VERSION "DNNBNNNYNNNNNNNNNNNNNNNNNNYYYNNNNNNNNNNNNN/4/%%%/4/'%**4NNN///"

NS_ :

BS_:

BU_: KCU_GS KCU_DM KW LCU_R LCU_F OFFCAR_SKM SKM SWCU VCU DBCU BCU_R BCU_F SCU_DRV DCU_PSG DCU_DRV SCU_PSG ACU OFFCAR_VCU OFFCAR_ACU IVI H_PUMP CCCU OFFCAR_SSCU SSCU M2M RCL_L RCL_R FCL_R FCL_L
VAL_TABLE_ Parking_lights 1 "ON " 0 "OFF" ;
VAL_TABLE_ lamp_fault 3 "Init" 1 "Fault" 0 "NoFault" ;
VAL_TABLE_ aVtSig_EN_ENABLE 1 "ENABLE" 0 "DISABLE" ;
VAL_TABLE_ aVtSig_ST_ON_OFF 1 "ON" 0 "OFF" ;
VAL_TABLE_ aVtSig_REQ_IDLE_ON_OFF 2 "ON" 1 "OFF" 0 "IDLE" ;
VAL_TABLE_ aVtSig_REQ_ON_OFF 1 "ON" 0 "OFF" ;
VAL_TABLE_ Statusvalues 1 "On" 0 "IDLE" ;
VAL_TABLE_ Enable_Disable 1 "Enable" 0 "Disable" ;
VAL_TABLE_ OpenClose 1 "OPEN" 0 "CLOSE" ;
VAL_TABLE_ DayNight 1 "Day" 0 "Night" ;
VAL_TABLE_ Applied_Not_Applied 2 "Applied" 1 "Not applied" 0 "IDLE" ;
VAL_TABLE_ Activate_Deactivate 2 "Activate" 1 "Deactivate" 0 "IDLE" ;
VAL_TABLE_ Stop_resume_charging 2 "Resume" 1 "Stop" 0 "IDLE" ;
VAL_TABLE_ Open_Request 2 "CLOSE" 1 "OPEN" 0 "IDLE" ;
VAL_TABLE_ HW_index 1 "6D IMU" 0 "5D IMU" ;
VAL_TABLE_ Window_Control 4 "Request auto down" 3 "Request down" 2 "Request auto up" 1 "Request up" 0 "IDLE" ;
VAL_TABLE_ acceleration_gyroscope_state 15 "Signal failure" 14 "Initialisation is running" 12 "Signal in specification " 11 "Initialisation is ready" 8 "Reserved" 7 "Reserved" 1 "IMU not available" 0 "IMU available" ;
VAL_TABLE_ AC_Modes 3 "HEAT" 2 "COOL" 1 "FAN" 0 "DRY" ;
VAL_TABLE_ Wipers_state 1 "Stop" 0 "Start" ;
VAL_TABLE_ ON_OFF 0 "IDLE" 2 "ON" 1 "OFF" ;
VAL_TABLE_ VehicleStates 5 "Charging" 4 "Precharging" 3 "Theft" 2 "Sleep" 1 "Accessory" 0 "Standby" ;
VAL_TABLE_ Fault_State 1 "FAULT" 0 "CLEAR" ;
VAL_TABLE_ Door_State 1 "CLOSED" 0 "OPEN" ;
VAL_TABLE_ MirrorHeaterRequest 1 "HEATER ON" 0 "HEATER OFF" ;
VAL_TABLE_ Lockrequest 2 "UNLOCK" 1 "LOCK" 0 "IDLE" ;
VAL_TABLE_ Window_Request 2 "DRIVE DOWN" 1 "DRIVE UP" 0 "STOP" ;
VAL_TABLE_ MirrorLightStatus 1 "LIGHT ON" 0 "LIGHT OFF" ;
VAL_TABLE_ MirrorRequest 4 "DRIVE RIGHT" 3 "DRIVE LEFT" 2 "DRIVE DOWN" 1 "DRIVE UP" 0 "STOPPED" ;
VAL_TABLE_ state1 1 "on" 0 "off" ;
VAL_TABLE_ Enable 1 "Enable Seat ECU" 0 "No action" ;
VAL_TABLE_ TORQUE_VECTORING_MODES 2 "FWD" 1 "AWL" 0 "RWL" ;
VAL_TABLE_ MODE_GEARBOX 4 "M" 3 "D" 2 "N" 1 "R" 0 "P" ;
VAL_TABLE_ Light_State 1 "NON FUNCTIOINAL" 0 "OK" ;
VAL_TABLE_ Strip_REQ 2 "ON 100percent" 1 "ON 50percent" 0 "OFF" ;
VAL_TABLE_ Beam_REQ 1 "ON" 0 "OFF" ;
VAL_TABLE_ HeaterStatus 2 "Seat HEater On High Level" 1 "Seat Heater On Low Level" 0 "Seat Heater Dissabled" ;
VAL_TABLE_ C1_KEYFOB_RKE_button_value 18 "Long press BT6" 17 "Long press BT5" 16 "Long press BT4" 15 "Long press BT3" 14 "Long press BT2" 13 "Long press BT1" 12 "Double press BT6" 11 "Double press BT5" 10 "Double press BT4" 9 "Double press BT3" 8 "Double press BT2" 7 "Double press BT1" 6 "Short press BT6" 5 "Short press BT5" 4 "Short press BT4" 3 "Short press BT3" 2 "Short press BT2" 1 "Short press BT1" 0 "No keys are pressed" ;
VAL_TABLE_ KEYFOB_PEPS_Status 6 "KEYFOB detected INSIDE" 5 "KEYFOB detected on FRONT side" 4 "KEYFOB detected on BACKside" 3 "KEYFOB detected on RIGHT side" 2 "KEYFOB detected on LEFT side" 1 "EARLY KEYFOB detection" 0 "KEYFOB is not detected" ;
VAL_TABLE_ Antenna_status 2 "Open" 1 "Short circuit" 0 "Ok" ;
VAL_TABLE_ DataBase_KEYFOB_Status 0 "EMPTY" 1 "1 Active KEYFOB" 2 "2 Active KEYFOBs" 3 "3 Active KEYFOBs" 4 "4 Active KEYFOBs" ;
VAL_TABLE_ KEYFOB_IMMO_Status 0 "IDLE" 1 "Not authenticated" 2 "Authenticated" ;
VAL_TABLE_ KEYFOB_Battery_Status 0 "OK" 1 "LOW" ;
VAL_TABLE_ Rampup_status 1 "Program 2 selected" 0 "Program 1 selected" ;
VAL_TABLE_ Motor_status 3 "Motor is stopped due to error" 2 "Motor is manually stopped" 1 "Motor given speed not reached" 0 "Motor is running at given speed" ;
VAL_TABLE_ Rampup_program 1 "program 2" 0 "program 1" ;
VAL_TABLE_ Motor_start_stop 1 "Motor start" 0 "Motor stop" ;

BO_ 2564460785 OFFCAR_SSCU_REQ: 8 OFFCAR_SSCU
 SG_ OFFCAR_SSCU_req : 7|64@0- (1,0) [0|0] ""  SSCU

BO_ 2564485520 OFFCAR_SSCU_RESP: 8 SSCU
 SG_ OFFCAR_SSCU_resp : 7|64@0+ (1,0) [0|0] ""  OFFCAR_SSCU

BO_ 158 BODY_KCU_GS_REQ: 3 KCU_GS
 SG_ IVI_PRND_mode_REQ : 2|3@0+ (1,0) [0|7] "enum"  VCU,M2M
 SG_ CRC : 23|8@0+ (1,0) [0|255] ""  VCU
 SG_ COUNTER : 11|4@0+ (1,0) [0|15] ""  VCU

BO_ 157 BODY_KCU_DM_REQ: 3 KCU_DM
 SG_ IVI_driving_mode_REQ : 3|4@0+ (1,0) [0|7] "enum"  VCU,M2M
 SG_ IVI_stability_mode_REQ : 6|3@0+ (1,0) [0|6] "enum"  VCU,M2M
 SG_ CRC : 23|8@0+ (1,0) [0|255] ""  VCU
 SG_ COUNTER : 11|4@0+ (1,0) [0|15] ""  VCU

BO_ 950 IVI_GPS: 8 IVI
 SG_ IVI_latitude : 7|25@0- (1E-005,0) [-90|90] "deg"  OFFCAR_VCU
 SG_ IVI_longitude : 30|26@0- (1E-005,0) [-180|180] "deg"  OFFCAR_VCU
 SG_ IVI_altitude : 52|13@0+ (1,-400) [-400|7791] "m"  OFFCAR_VCU

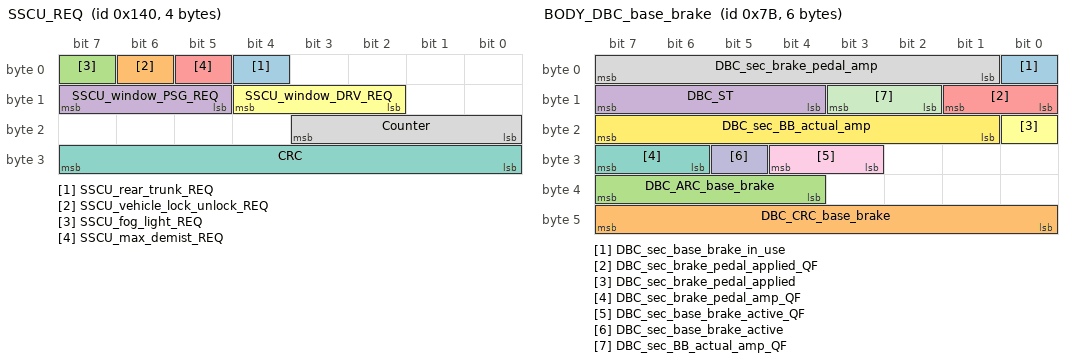
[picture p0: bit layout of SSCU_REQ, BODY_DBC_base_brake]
BO_ 320 SSCU_REQ: 4 SSCU
 SG_ SSCU_rear_trunk_REQ : 4|1@0+ (1,0) [0|1] ""  VCU
 SG_ SSCU_vehicle_lock_unlock_REQ : 6|1@0+ (1,0) [0|1] ""  VCU
 SG_ SSCU_fog_light_REQ : 7|1@0+ (1,0) [0|1] ""  BCU_R,VCU
 SG_ SSCU_window_PSG_REQ : 15|3@0+ (1,0) [0|7] ""  VCU
 SG_ SSCU_max_demist_REQ : 5|1@0+ (1,0) [0|1] ""  IVI
 SG_ SSCU_window_DRV_REQ : 12|3@0+ (1,0) [0|7] ""  VCU
 SG_ CRC : 31|8@0+ (1,0) [0|255] ""  DCU_DRV,DCU_PSG,IVI,VCU
 SG_ Counter : 19|4@0+ (1,0) [0|15] ""  DCU_DRV,DCU_PSG,IVI,VCU

BO_ 1300 SSCU_ERR: 3 SSCU
 SG_ SSCU_thermal_driver_led_ERR : 8|1@0+ (1,0) [0|1] ""  VCU,IVI
 SG_ SSCU_right_window_led_ERR : 9|1@0+ (1,0) [0|1] ""  VCU,IVI
 SG_ SSCU_left_window_led_ERR : 0|1@0+ (1,0) [0|1] ""  VCU,IVI
 SG_ SSCU_rear_fog_led_ERR : 2|2@0+ (1,0) [0|3] ""  VCU,IVI
 SG_ SSCU_max_demist_led_ERR : 4|2@0+ (1,0) [0|3] ""  VCU,IVI
 SG_ SSCU_doors_lock_led_ERR : 6|2@0+ (1,0) [0|3] ""  VCU,IVI
 SG_ SSCU_rear_trunk_led_ERR : 7|1@0+ (1,0) [0|1] ""  VCU,IVI
 SG_ SSCU_mcu_ERR : 11|2@0+ (1,0) [0|3] ""  VCU,IVI
 SG_ SSCU_right_window_key_ERR : 12|1@0+ (1,0) [0|1] ""  VCU,IVI
 SG_ SSCU_left_window_key_ERR : 13|1@0+ (1,0) [0|1] ""  VCU,IVI
 SG_ SSCU_rear_fog_key_ERR : 14|1@0+ (1,0) [0|1] ""  VCU,IVI
 SG_ SSCU_max_demist_key_ERR : 15|1@0+ (1,0) [0|1] ""  VCU,IVI
 SG_ SSCU_doors_lock_key_ERR : 16|1@0+ (1,0) [0|1] ""  VCU,IVI
 SG_ SSCU_rear_trunk_key_ERR : 17|1@0+ (1,0) [0|1] ""  VCU,IVI
 SG_ SSCU_right_window_key_incohe_ERR : 18|1@0+ (1,0) [0|1] ""  VCU,IVI
 SG_ SSCU_left_window_key_incohe_ERR : 19|1@0+ (1,0) [0|1] ""  VCU,IVI
 SG_ SSCU_communication_ERR : 20|1@0+ (1,0) [0|1] ""  VCU,IVI

BO_ 123 BODY_DBC_base_brake: 6 VCU
 SG_ DBC_sec_base_brake_in_use : 0|1@0+ (1,0) [0|1] ""  BCU_F,BCU_R
 SG_ DBC_CRC_base_brake : 47|8@0+ (1,0) [0|255] ""  BCU_F,BCU_R
 SG_ DBC_ARC_base_brake : 39|4@0+ (1,0) [0|15] ""  BCU_F,BCU_R
 SG_ DBC_ST : 15|4@0+ (1,0) [0|12] ""  BCU_F,BCU_R
 SG_ DBC_sec_brake_pedal_applied_QF : 9|2@0+ (1,0) [0|1] ""  BCU_F,BCU_R
 SG_ DBC_sec_brake_pedal_applied : 16|1@0+ (1,0) [0|1] ""  BCU_F,BCU_R
 SG_ DBC_sec_brake_pedal_amp_QF : 31|2@0+ (1,0) [0|1] ""  BCU_F,BCU_R
 SG_ DBC_sec_brake_pedal_amp : 7|7@0+ (1,0) [0|100] "%"  BCU_F,BCU_R
 SG_ DBC_sec_base_brake_active_QF : 28|2@0+ (1,0) [0|2] ""  BCU_F,BCU_R
 SG_ DBC_sec_base_brake_active : 29|1@0+ (1,0) [0|1] ""  BCU_F,BCU_R
 SG_ DBC_sec_BB_actual_amp_QF : 11|2@0+ (1,0) [0|3] ""  BCU_F,BCU_R
 SG_ DBC_sec_BB_actual_amp : 23|7@0+ (1,0) [0|100] "%"  BCU_F,BCU_R

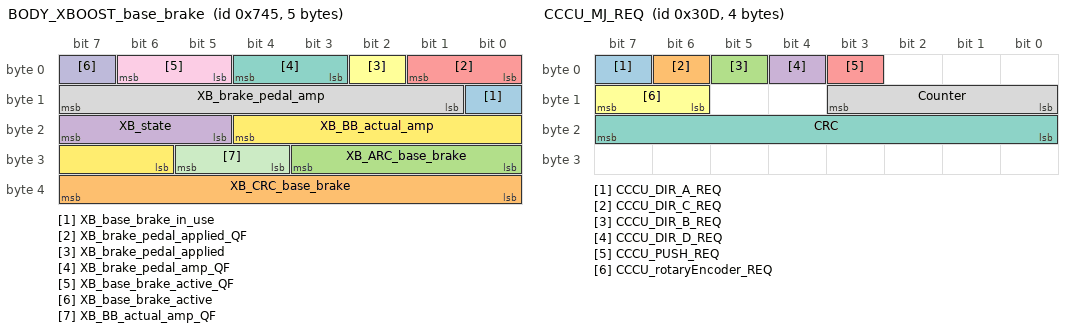
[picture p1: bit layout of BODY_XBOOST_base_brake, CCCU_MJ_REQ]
BO_ 1861 BODY_XBOOST_base_brake: 5 VCU
 SG_ XB_base_brake_in_use : 8|1@0+ (1,0) [0|1] ""  BCU_F,BCU_R
 SG_ XB_CRC_base_brake : 39|8@0+ (1,0) [0|255] ""  BCU_F,BCU_R
 SG_ XB_ARC_base_brake : 27|4@0+ (1,0) [0|15] ""  BCU_F,BCU_R
 SG_ XB_state : 23|3@0+ (1,0) [0|6] ""  BCU_F,BCU_R
 SG_ XB_brake_pedal_applied_QF : 1|2@0+ (1,0) [0|2] ""  BCU_F,BCU_R
 SG_ XB_brake_pedal_applied : 2|1@0+ (1,0) [0|1] ""  BCU_F,BCU_R
 SG_ XB_brake_pedal_amp_QF : 4|2@0+ (1,0) [0|3] ""  BCU_F,BCU_R
 SG_ XB_brake_pedal_amp : 15|7@0+ (1,0) [0|100] "%"  BCU_F,BCU_R
 SG_ XB_base_brake_active_QF : 6|2@0+ (1,0) [0|2] ""  BCU_F,BCU_R
 SG_ XB_base_brake_active : 7|1@0+ (1,0) [0|1] ""  BCU_F,BCU_R
 SG_ XB_BB_actual_amp_QF : 29|2@0+ (1,0) [0|3] ""  BCU_F,BCU_R
 SG_ XB_BB_actual_amp : 20|7@0+ (1,0) [0|100] "%"  BCU_F,BCU_R

BO_ 808 SKM_ST: 3 SKM
 SG_ SKM_KEYBLADE_unlock_ST : 1|1@0+ (1,0) [0|1] ""  VCU,M2M
 SG_ SKM_PEPS_active_ST : 2|1@0+ (1,0) [0|1] ""  VCU,M2M
 SG_ SKM_KEYFOB_data_base_ST : 5|3@0+ (1,0) [0|4] ""  VCU,M2M
 SG_ SKM_KEYFOB_IMMO_ST : 7|2@0+ (1,0) [0|3] ""  VCU,M2M
 SG_ CRC : 23|8@0+ (1,0) [0|255] ""  VCU
 SG_ COUNTER : 11|4@0+ (1,0) [0|15] ""  VCU

BO_ 804 SKM_KEYFOB_ST: 7 SKM
 SG_ SKM_KEYFOB_PEPS_ST_4 : 36|3@0+ (1,0) [0|7] ""  VCU,M2M
 SG_ SKM_KEYFOB_PEPS_ST_3 : 30|3@0+ (1,0) [0|7] ""  VCU,M2M
 SG_ SKM_KEYFOB_PEPS_ST_2 : 8|3@0+ (1,0) [0|7] ""  VCU,M2M
 SG_ SKM_KEYFOB_PEPS_ST_1 : 2|3@0+ (1,0) [0|7] ""  VCU,M2M
 SG_ SKM_KEYFOB_RKE_distance_4 : 33|1@0+ (1,0) [0|1] ""  VCU,M2M
 SG_ SKM_KEYFOB_RKE_distance_3 : 26|1@0+ (1,0) [0|1] ""  VCU,M2M
 SG_ SKM_KEYFOB_RKE_distance_2 : 21|1@0+ (1,0) [0|1] ""  VCU,M2M
 SG_ SKM_KEYFOB_RKE_distance_1 : 15|1@0+ (1,0) [0|1] ""  VCU,M2M
 SG_ SKM_KEYFOB_RKE_ST_4 : 25|5@0+ (1,0) [0|31] ""  BCU_R,VCU,M2M
 SG_ SKM_KEYFOB_RKE_ST_3 : 19|5@0+ (1,0) [0|31] ""  BCU_R,VCU,M2M
 SG_ SKM_KEYFOB_RKE_ST_2 : 13|5@0+ (1,0) [0|31] ""  BCU_R,VCU,M2M
 SG_ SKM_KEYFOB_RKE_ST_1 : 7|5@0+ (1,0) [0|31] ""  BCU_R,VCU,M2M
 SG_ SKM_KEYFOB_battery_ST_4 : 32|1@0+ (1,0) [0|1] ""  VCU,M2M
 SG_ SKM_KEYFOB_battery_ST_3 : 27|1@0+ (1,0) [0|1] ""  VCU,M2M
 SG_ SKM_KEYFOB_battery_ST_2 : 20|1@0+ (1,0) [0|1] ""  VCU,M2M
 SG_ SKM_KEYFOB_battery_ST_1 : 14|1@0+ (1,0) [0|1] ""  VCU,M2M
 SG_ CRC : 55|8@0+ (1,0) [0|255] ""  VCU
 SG_ COUNTER : 43|4@0+ (1,0) [0|15] ""  VCU

BO_ 2025 BODY_LCU_F_UDS_RESP: 8 LCU_F
 SG_ LCU_F_uds_resp : 7|64@0+ (1,0) [0|255] ""  IVI,DBCU

BO_ 2024 BODY_LCU_F_UDS_REQ: 8 IVI
 SG_ LCU_F_uds_req : 7|64@0+ (1,0) [0|255] ""  LCU_F

BO_ 1584 LCU_F_XCP: 8 LCU_F
 SG_ LCU_F_xcp : 0|64@1+ (1,0) [0|1.84467440737096E+019] ""  OFFCAR_VCU

BO_ 1585 OFFCAR_LCU_F_XCP: 8 OFFCAR_VCU
 SG_ OFFCAR_LCU_F_xcp : 0|64@1+ (1,0) [0|0] ""  LCU_F

BO_ 2027 BODY_LCU_R_UDS_RESP: 8 LCU_R
 SG_ LCU_R_uds_resp : 7|64@0+ (1,0) [0|255] ""  IVI,DBCU

BO_ 2026 BODY_LCU_R_UDS_REQ: 8 IVI
 SG_ LCU_R_uds_req : 7|64@0+ (1,0) [0|255] ""  LCU_R

BO_ 1586 LCU_R_XCP: 8 LCU_R
 SG_ LCU_R_xcp : 0|64@1+ (1,0) [0|1.84467440737096E+019] ""  OFFCAR_VCU

BO_ 1587 OFFCAR_LCU_R_XCP: 8 OFFCAR_VCU
 SG_ OFFCAR_LCU_R_xcp : 0|64@1+ (1,0) [0|0] ""  LCU_R

BO_ 2029 BODY_CCCU_UDS_RESP: 8 CCCU
 SG_ CCCU_uds_resp : 7|64@0+ (1,0) [0|255] ""  IVI,DBCU

BO_ 2028 BODY_CCCU_UDS_REQ: 8 IVI
 SG_ CCCU_uds_req : 7|64@0+ (1,0) [0|255] ""  CCCU

BO_ 1582 CCCU_XCP: 8 CCCU
 SG_ CCCU_xcp : 0|64@1+ (1,0) [0|1.84467440737096E+019] ""  OFFCAR_VCU

BO_ 1156 CCCU_Bootloader: 8 CCCU
 SG_ CCCU_Bootloader : 0|64@1+ (1,0) [0|1.84467440737096E+019] ""  OFFCAR_VCU

BO_ 1157 OFFCAR_CCCU_Bootloader: 8 OFFCAR_VCU
 SG_ OFFCAR_CCCU_bootloader : 0|64@1+ (1,0) [0|0] ""  CCCU

BO_ 1583 OFFCAR_CCCU_XCP: 8 OFFCAR_VCU
 SG_ OFFCAR_CCCU_xcp : 0|64@1+ (1,0) [0|0] ""  CCCU

BO_ 1048 CCCU_version_info: 8 CCCU
 SG_ CCCU_versionDbc m3 : 63|8@0+ (1,0) [0|255] ""  OFFCAR_VCU,M2M
 SG_ CCCU_versionSerialNumber m3 : 15|48@0+ (1,0) [0|281474976710655] ""  OFFCAR_VCU,M2M
 SG_ CCCU_HW_versionPatch m2 : 31|8@0+ (1,0) [0|255] ""  OFFCAR_VCU,M2M
 SG_ CCCU_HW_versionMinor m2 : 23|8@0+ (1,0) [0|255] ""  OFFCAR_VCU,M2M
 SG_ CCCU_HW_versionMajor m2 : 15|8@0+ (1,0) [0|255] ""  OFFCAR_VCU,M2M
 SG_ CCCU_FW_commitHash m1 : 39|32@0+ (1,0) [0|4294967295] ""  OFFCAR_VCU,M2M
 SG_ CCCU_FW_versionPatch m1 : 31|8@0+ (1,0) [0|255] ""  OFFCAR_VCU,M2M
 SG_ CCCU_FW_versionMinor m1 : 23|8@0+ (1,0) [0|255] ""  OFFCAR_VCU,M2M
 SG_ CCCU_FW_versionMajor m1 : 15|8@0+ (1,0) [0|255] ""  OFFCAR_VCU,M2M
 SG_ CCCU_FW_versionDev m1 : 5|1@0+ (1,0) [0|1] ""  OFFCAR_VCU,M2M
 SG_ CCCU_BL_commitHash m0 : 39|32@0+ (1,0) [0|4294967295] ""  OFFCAR_VCU,M2M
 SG_ CCCU_BL_versionPatch m0 : 31|8@0+ (1,0) [0|255] ""  OFFCAR_VCU,M2M
 SG_ CCCU_BL_versionMinor m0 : 23|8@0+ (1,0) [0|255] ""  OFFCAR_VCU,M2M
 SG_ CCCU_BL_versionMajor m0 : 15|8@0+ (1,0) [0|255] ""  OFFCAR_VCU,M2M
 SG_ CCCU_BL_versionDev m0 : 5|1@0+ (1,0) [0|1] ""  OFFCAR_VCU,M2M
 SG_ CCCU_version_info_MUX M : 7|2@0+ (1,0) [0|3] ""  OFFCAR_VCU,M2M

BO_ 1299 CCCU_ERR: 4 CCCU
 SG_ CCCU_internal_FATAL_ERR : 0|1@0+ (1,0) [0|1] ""  VCU,IVI,M2M
 SG_ CCCU_internal_ERR : 1|1@0+ (1,0) [0|1] ""  VCU,IVI,M2M
 SG_ CCCU_joystick_ERR : 3|1@0+ (1,0) [0|1] ""  VCU,IVI,M2M
 SG_ Counter : 19|4@0+ (1,0) [0|15] ""  VCU,IVI,M2M
 SG_ CRC : 31|8@0+ (1,0) [0|255] ""  VCU,IVI,M2M

BO_ 781 CCCU_MJ_REQ: 4 CCCU
 SG_ CCCU_DIR_A_REQ : 7|1@0+ (1,0) [0|1] ""  IVI,VCU,M2M
 SG_ CCCU_DIR_C_REQ : 6|1@0+ (1,0) [0|1] ""  IVI,VCU,M2M
 SG_ CCCU_DIR_B_REQ : 5|1@0+ (1,0) [0|1] ""  IVI,VCU,M2M
 SG_ CCCU_DIR_D_REQ : 4|1@0+ (1,0) [0|1] ""  IVI,VCU,M2M
 SG_ CCCU_PUSH_REQ : 3|1@0+ (1,0) [0|1] ""  IVI,VCU,M2M
 SG_ CCCU_rotaryEncoder_REQ : 15|2@0+ (1,0) [0|2] "enum"  IVI,VCU,M2M
 SG_ CRC : 23|8@0+ (1,0) [0|255] ""  IVI,VCU
 SG_ Counter : 11|4@0+ (1,0) [0|15] ""  IVI,VCU

BO_ 1823 BODY_IMU1_CLU_ID3: 8 VCU
 SG_ IMU1_vert_acc_QF : 20|4@1+ (1,0) [0|0] ""  BCU_F,BCU_R
 SG_ IMU1_pitch_rate_QF : 16|4@1+ (1,0) [0|0] ""  BCU_F,BCU_R
 SG_ IMU1_pitch_rate : 0|16@1+ (0.005,-163.83) [-163.83|163.845] "deg/s"  BCU_F,BCU_R
 SG_ IMU1_chksum_clu_id3 : 56|8@1+ (1,0) [0|0] ""  BCU_F,BCU_R
 SG_ IMU1_aliv_clu_id3 : 52|4@1+ (1,0) [0|15] ""  BCU_F,BCU_R
 SG_ IMU1_vert_acc : 24|16@1+ (0.002,-65.532) [-65.532|65.538] "m/s2"  BCU_F,BCU_R

BO_ 1822 BODY_IMU1_CLU_ID2: 8 VCU
 SG_ IMU1_long_acc : 24|16@1+ (0.002,-65.532) [-65.532|65.538] "m/s2"  BCU_F,BCU_R
 SG_ IMU1_long_acc_QF : 20|4@1+ (1,0) [0|0] ""  BCU_F,BCU_R
 SG_ IMU1_roll_rate_QF : 16|4@1+ (1,0) [0|0] ""  BCU_F,BCU_R
 SG_ IMU1_chksum_clu_id2 : 56|8@1+ (1,0) [0|0] ""  BCU_F,BCU_R
 SG_ IMU1_aliv_clu_id2 : 52|4@1+ (1,0) [0|15] ""  BCU_F,BCU_R
 SG_ IMU1_roll_rate : 0|16@1+ (0.005,-163.83) [-163.83|163.845] "deg/s"  BCU_F,BCU_R

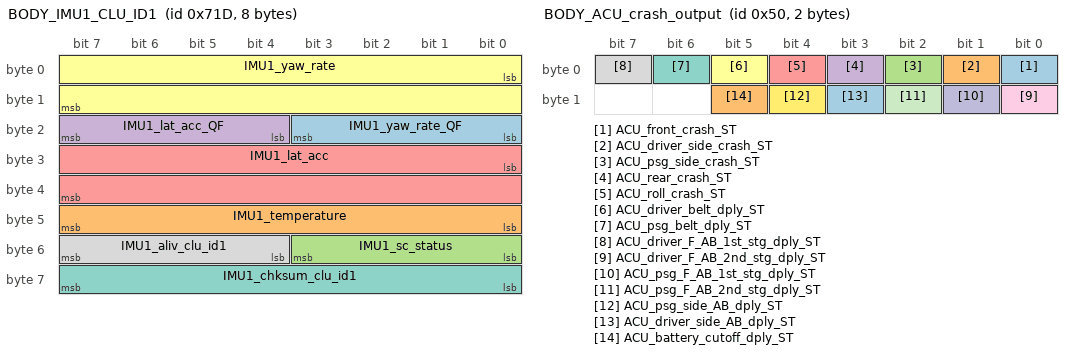
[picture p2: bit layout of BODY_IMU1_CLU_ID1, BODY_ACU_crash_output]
BO_ 1821 BODY_IMU1_CLU_ID1: 8 VCU
 SG_ IMU1_yaw_rate_QF : 16|4@1+ (1,0) [0|0] ""  BCU_F,BCU_R,ACU
 SG_ IMU1_temperature : 40|8@1+ (1,-50) [-50|205] "degC"  BCU_F,BCU_R
 SG_ IMU1_sc_status : 48|4@1+ (1,0) [0|0] ""  BCU_F,BCU_R
 SG_ IMU1_lat_acc_QF : 20|4@1+ (1,0) [0|0] ""  BCU_F,BCU_R
 SG_ IMU1_lat_acc : 24|16@1+ (0.002,-65.532) [-65.532|65.538] "m/s2"  BCU_F,BCU_R
 SG_ IMU1_yaw_rate : 0|16@1+ (0.005,-163.83) [-163.83|163.845] "deg/s"  BCU_F,BCU_R,ACU
 SG_ IMU1_chksum_clu_id1 : 56|8@1+ (1,0) [0|0] ""  BCU_F,BCU_R
 SG_ IMU1_aliv_clu_id1 : 52|4@1+ (1,0) [0|15] ""  BCU_F,BCU_R

BO_ 2009 BODY_SWCU_UDS_RESP: 8 SWCU
 SG_ SWCU_uds_resp : 7|64@0+ (1,0) [0|255] ""  IVI,DBCU

BO_ 2008 BODY_SWCU_UDS_REQ: 8 IVI
 SG_ SWCU_uds_req : 7|64@0+ (1,0) [0|255] ""  SWCU

BO_ 2003 BODY_SKM_UDS_RESP: 8 SKM
 SG_ SKM_uds_resp : 7|64@0+ (1,0) [0|255] ""  IVI,DBCU

BO_ 2002 BODY_SKM_UDS_REQ: 8 IVI
 SG_ SKM_uds_req : 7|64@0+ (1,0) [0|255] ""  SKM

BO_ 2001 BODY_DBCU_UDS_RESP: 8 DBCU
 SG_ DBCU_uds_resp : 7|64@0+ (1,0) [0|255] ""  IVI

BO_ 2000 BODY_DBCU_UDS_REQ: 8 IVI
 SG_ DBCU_uds_req : 7|64@0+ (1,0) [0|255] ""  DBCU

BO_ 1998 BODY_BCU_R_UDS_REQ: 8 IVI
 SG_ BCU_R_uds_req : 7|64@0+ (1,0) [0|255] ""  BCU_R

BO_ 1999 BODY_BCU_R_UDS_RESP: 8 BCU_R
 SG_ BCU_R_uds_resp : 7|64@0+ (1,0) [0|255] ""  IVI,DBCU

BO_ 1997 BODY_BCU_F_UDS_RESP: 8 BCU_F
 SG_ BCU_F_uds_resp : 7|64@0+ (1,0) [0|255] ""  IVI,DBCU

BO_ 1996 BODY_BCU_F_UDS_REQ: 8 IVI
 SG_ BCU_F_uds_req : 7|64@0+ (1,0) [0|255] ""  BCU_F

BO_ 1995 BODY_SCU_PSG_UDS_RESP: 8 SCU_PSG
 SG_ SCU_PSG_uds_resp : 7|64@0+ (1,0) [0|255] ""  IVI,DBCU

BO_ 1994 BODY_SCU_PSG_UDS_REQ: 8 IVI
 SG_ SCU_PSG_uds_req : 7|64@0+ (1,0) [0|255] ""  SCU_PSG

BO_ 1993 BODY_SCU_DRV_UDS_RESP: 8 SCU_DRV
 SG_ SCU_DRV_uds_resp : 7|64@0+ (1,0) [0|255] ""  IVI,DBCU

BO_ 1992 BODY_SCU_DRV_UDS_REQ: 8 IVI
 SG_ SCU_DRV_uds_req : 7|64@0+ (1,0) [0|255] ""  SCU_DRV

BO_ 1991 BODY_DCU_PSG_UDS_RESP: 8 DCU_PSG
 SG_ DCU_PSG_uds_resp : 7|64@0+ (1,0) [0|255] ""  IVI,DBCU

BO_ 1990 BODY_DCU_PSG_UDS_REQ: 8 IVI
 SG_ DCU_PSG_uds_req : 7|64@0+ (1,0) [0|255] ""  DCU_PSG

BO_ 1989 BODY_DCU_DRV_UDS_RESP: 8 DCU_DRV
 SG_ DCU_DRV_uds_resp : 7|64@0+ (1,0) [0|255] ""  IVI,DBCU

BO_ 1988 BODY_DCU_DRV_UDS_REQ: 8 IVI
 SG_ DCU_DRV_uds_req : 7|64@0+ (1,0) [0|255] ""  DCU_DRV

BO_ 1987 BODY_IVI_UDS_RESP: 8 IVI
 SG_ IVI_uds_resp : 7|64@0+ (1,0) [0|255] ""  IVI,DBCU

BO_ 1986 BODY_IVI_UDS_REQ: 8 IVI
 SG_ IVI_uds_req : 7|64@0+ (1,0) [0|255] ""  IVI

BO_ 1985 BODY_VCU_UDS_RESP: 8 VCU
 SG_ VCU_uds_resp : 7|64@0+ (1,0) [0|255] ""  IVI,DBCU

BO_ 1984 BODY_VCU_UDS_REQ: 8 IVI
 SG_ VCU_uds_req : 7|64@0+ (1,0) [0|255] ""  VCU

BO_ 1977 BODY_XBOOST_UDS_RESP: 8 VCU
 SG_ XBOOST_uds_resp : 7|64@0+ (1,0) [0|255] ""  IVI,DBCU

BO_ 1976 BODY_XBOOST_UDS_REQ: 8 IVI
 SG_ XBOOST_uds_req : 7|64@0+ (1,0) [0|255] ""  VCU

BO_ 1975 BODY_PDM_F_UDS_RESP: 8 VCU
 SG_ PDM_F_uds_resp : 7|64@0+ (1,0) [0|255] ""  IVI,DBCU

BO_ 1983 BODY_PDM_F_UDS_REQ: 8 IVI
 SG_ PDM_F_uds_req : 7|64@0+ (1,0) [0|255] ""  VCU

BO_ 1973 BODY_PCU_UDS_RESP: 8 VCU
 SG_ PCU_uds_resp : 7|64@0+ (1,0) [0|255] ""  IVI,DBCU

BO_ 1972 BODY_PCU_UDS_REQ: 8 IVI
 SG_ PCU_uds_req : 7|64@0+ (1,0) [0|255] ""  VCU

BO_ 1971 BODY_PDU_UDS_RESP: 8 VCU
 SG_ PDU_uds_resp : 7|64@0+ (1,0) [0|255] ""  IVI,DBCU

BO_ 1970 BODY_PDU_UDS_REQ: 8 IVI
 SG_ PDU_uds_req : 7|64@0+ (1,0) [0|255] ""  VCU

BO_ 1955 BODY_DBC1280_UDS_RESP: 8 VCU
 SG_ DBC1280_uds_resp : 7|64@0+ (1,0) [0|255] ""  IVI,DBCU

BO_ 1954 BODY_DBC1280_UDS_REQ: 8 IVI
 SG_ DBC1280_uds_req : 7|64@0+ (1,0) [0|255] ""  VCU

BO_ 1953 BODY_PDM_R_UDS_RESP: 8 VCU
 SG_ PDM_R_uds_resp : 7|64@0+ (1,0) [0|255] ""  IVI,DBCU

BO_ 1952 BODY_PDM_R_UDS_REQ: 8 IVI
 SG_ PDM_R_uds_req : 7|64@0+ (1,0) [0|255] ""  VCU

BO_ 1939 BODY_CCU_F_UDS_RESP: 8 VCU
 SG_ CCU_F_uds_resp : 7|64@0+ (1,0) [0|255] ""  IVI,DBCU

BO_ 1938 BODY_CCU_F_UDS_REQ: 8 IVI
 SG_ CCU_F_uds_req : 7|64@0+ (1,0) [0|255] ""  VCU

BO_ 1927 BODY_OBC_UDS_RESP: 8 VCU
 SG_ OBC_uds_resp : 7|64@0+ (1,0) [0|255] ""  IVI,DBCU

BO_ 1926 BODY_OBC_UDS_REQ: 8 IVI
 SG_ OBC_uds_req : 7|64@0+ (1,0) [0|255] ""  VCU

BO_ 1925 BODY_CCU_R_UDS_RESP: 8 VCU
 SG_ CCU_R_uds_resp : 7|64@0+ (1,0) [0|255] ""  IVI,DBCU

BO_ 1924 BODY_CCU_R_UDS_REQ: 8 IVI
 SG_ CCU_R_uds_req : 7|64@0+ (1,0) [0|255] ""  VCU

BO_ 1923 BODY_BFI_RL_UDS_RESP: 8 VCU
 SG_ BFI_RL_uds_resp : 7|64@0+ (1,0) [0|255] ""  IVI,DBCU

BO_ 1922 BODY_BFI_RL_UDS_REQ: 8 IVI
 SG_ BFI_RL_uds_req : 7|64@0+ (1,0) [0|255] ""  VCU

BO_ 1921 BODY_BFI_RR_UDS_RESP: 8 VCU
 SG_ BFI_RR_uds_resp : 7|64@0+ (1,0) [0|255] ""  IVI,DBCU

BO_ 1920 BODY_BFI_RR_UDS_REQ: 8 IVI
 SG_ BFI_RR_uds_req : 7|64@0+ (1,0) [0|255] ""  VCU

BO_ 948 BODY_PDU_SLAVE_01_UDS_RESP: 8 VCU
 SG_ PDU_slave_01_uds_resp : 7|64@0+ (1,0) [0|255] ""  IVI,DBCU

BO_ 947 BODY_PDU_SLAVE_01_UDS_REQ: 8 IVI
 SG_ PDU_slave_01_uds_req : 7|64@0+ (1,0) [0|255] ""  VCU

BO_ 1005 BODY_PDU_SLAVE_02_UDS_RESP: 8 VCU
 SG_ PDU_slave_02_uds_resp : 7|64@0+ (1,0) [0|255] ""  IVI,DBCU

BO_ 949 BODY_PDU_SLAVE_02_UDS_REQ: 8 IVI
 SG_ PDU_slave_02_uds_req : 7|64@0+ (1,0) [0|255] ""  VCU

BO_ 952 BODY_PDU_SLAVE_03_UDS_RESP: 8 VCU
 SG_ PDU_slave_03_uds_resp : 7|64@0+ (1,0) [0|255] ""  IVI,DBCU

BO_ 951 BODY_PDU_SLAVE_03_UDS_REQ: 8 IVI
 SG_ PDU_slave_03_uds_req : 7|64@0+ (1,0) [0|255] ""  VCU

BO_ 954 BODY_PDU_SLAVE_04_UDS_RESP: 8 VCU
 SG_ PDU_slave_04_uds_resp : 7|64@0+ (1,0) [0|255] ""  IVI,DBCU

BO_ 953 BODY_PDU_SLAVE_04_UDS_REQ: 8 IVI
 SG_ PDU_slave_04_uds_req : 7|64@0+ (1,0) [0|255] ""  VCU

BO_ 956 BODY_PDU_SLAVE_05_UDS_RESP: 8 VCU
 SG_ PDU_slave_05_uds_resp : 7|64@0+ (1,0) [0|255] ""  IVI,DBCU

BO_ 955 BODY_PDU_SLAVE_05_UDS_REQ: 8 IVI
 SG_ PDU_slave_05_uds_req : 7|64@0+ (1,0) [0|255] ""  VCU

BO_ 958 BODY_PDU_SLAVE_06_UDS_RESP: 8 VCU
 SG_ PDU_slave_06_uds_resp : 7|64@0+ (1,0) [0|255] ""  IVI,DBCU

BO_ 957 BODY_PDU_SLAVE_06_UDS_REQ: 8 IVI
 SG_ PDU_slave_06_uds_req : 7|64@0+ (1,0) [0|255] ""  VCU

BO_ 960 BODY_PDU_SLAVE_07_UDS_RESP: 8 VCU
 SG_ PDU_slave_07_uds_resp : 7|64@0+ (1,0) [0|255] ""  IVI,DBCU

BO_ 959 BODY_PDU_SLAVE_07_UDS_REQ: 8 IVI
 SG_ PDU_slave_07_uds_req : 7|64@0+ (1,0) [0|255] ""  VCU

BO_ 962 BODY_PDU_SLAVE_08_UDS_RESP: 8 VCU
 SG_ PDU_slave_08_uds_resp : 7|64@0+ (1,0) [0|255] ""  IVI,DBCU

BO_ 961 BODY_PDU_SLAVE_08_UDS_REQ: 8 IVI
 SG_ PDU_slave_08_uds_req : 7|64@0+ (1,0) [0|255] ""  VCU

BO_ 964 BODY_PDU_SLAVE_09_UDS_RESP: 8 VCU
 SG_ PDU_slave_09_uds_resp : 7|64@0+ (1,0) [0|255] ""  IVI,DBCU

BO_ 963 BODY_PDU_SLAVE_09_UDS_REQ: 8 IVI
 SG_ PDU_slave_09_uds_req : 7|64@0+ (1,0) [0|255] ""  VCU

BO_ 966 BODY_PDU_SLAVE_10_UDS_RESP: 8 VCU
 SG_ PDU_slave_10_uds_resp : 7|64@0+ (1,0) [0|255] ""  IVI,DBCU

BO_ 965 BODY_PDU_SLAVE_10_UDS_REQ: 8 IVI
 SG_ PDU_slave_10_uds_req : 7|64@0+ (1,0) [0|255] ""  VCU

BO_ 968 BODY_PDU_SLAVE_11_UDS_RESP: 8 VCU
 SG_ PDU_slave_11_uds_resp : 7|64@0+ (1,0) [0|255] ""  IVI,DBCU

BO_ 967 BODY_PDU_SLAVE_11_UDS_REQ: 8 IVI
 SG_ PDU_slave_11_uds_req : 7|64@0+ (1,0) [0|255] ""  VCU

BO_ 970 BODY_PDU_SLAVE_12_UDS_RESP: 8 VCU
 SG_ PDU_slave_12_uds_resp : 7|64@0+ (1,0) [0|255] ""  IVI,DBCU

BO_ 969 BODY_PDU_SLAVE_12_UDS_REQ: 8 IVI
 SG_ PDU_slave_12_uds_req : 7|64@0+ (1,0) [0|255] ""  VCU

BO_ 972 BODY_PDU_SLAVE_13_UDS_RESP: 8 VCU
 SG_ PDU_slave_13_uds_resp : 7|64@0+ (1,0) [0|255] ""  IVI,DBCU

BO_ 971 BODY_PDU_SLAVE_13_UDS_REQ: 8 IVI
 SG_ PDU_slave_13_uds_req : 7|64@0+ (1,0) [0|255] ""  VCU

BO_ 974 BODY_PDU_SLAVE_14_UDS_RESP: 8 VCU
 SG_ PDU_slave_14_uds_resp : 7|64@0+ (1,0) [0|255] ""  IVI,DBCU

BO_ 973 BODY_PDU_SLAVE_14_UDS_REQ: 8 IVI
 SG_ PDU_slave_14_uds_req : 7|64@0+ (1,0) [0|255] ""  VCU

BO_ 976 BODY_PDU_SLAVE_15_UDS_RESP: 8 VCU
 SG_ PDU_slave_15_uds_resp : 7|64@0+ (1,0) [0|255] ""  IVI,DBCU

BO_ 975 BODY_PDU_SLAVE_15_UDS_REQ: 8 IVI
 SG_ PDU_slave_15_uds_req : 7|64@0+ (1,0) [0|255] ""  VCU

BO_ 978 BODY_PDU_SLAVE_16_UDS_RESP: 8 VCU
 SG_ PDU_slave_16_uds_resp : 7|64@0+ (1,0) [0|255] ""  IVI,DBCU

BO_ 977 BODY_PDU_SLAVE_16_UDS_REQ: 8 IVI
 SG_ PDU_slave_16_uds_req : 7|64@0+ (1,0) [0|255] ""  VCU

BO_ 980 BODY_PDU_SLAVE_17_UDS_RESP: 8 VCU
 SG_ PDU_slave_17_uds_resp : 7|64@0+ (1,0) [0|255] ""  IVI,DBCU

BO_ 979 BODY_PDU_SLAVE_17_UDS_REQ: 8 IVI
 SG_ PDU_slave_17_uds_req : 7|64@0+ (1,0) [0|255] ""  VCU

BO_ 982 BODY_PDU_SLAVE_18_UDS_RESP: 8 VCU
 SG_ PDU_slave_18_uds_resp : 7|64@0+ (1,0) [0|255] ""  IVI,DBCU

BO_ 981 BODY_PDU_SLAVE_18_UDS_REQ: 8 IVI
 SG_ PDU_slave_18_uds_req : 7|64@0+ (1,0) [0|255] ""  VCU

BO_ 984 BODY_PDU_SLAVE_19_UDS_RESP: 8 VCU
 SG_ PDU_slave_19_uds_resp : 7|64@0+ (1,0) [0|255] ""  IVI,DBCU

BO_ 983 BODY_PDU_SLAVE_19_UDS_REQ: 8 IVI
 SG_ PDU_slave_19_uds_req : 7|64@0+ (1,0) [0|255] ""  VCU

BO_ 986 BODY_PDU_SLAVE_20_UDS_RESP: 8 VCU
 SG_ PDU_slave_20_uds_resp : 7|64@0+ (1,0) [0|255] ""  IVI,DBCU

BO_ 985 BODY_PDU_SLAVE_20_UDS_REQ: 8 IVI
 SG_ PDU_slave_20_uds_req : 7|64@0+ (1,0) [0|255] ""  VCU

BO_ 988 BODY_PDU_SLAVE_21_UDS_RESP: 8 VCU
 SG_ PDU_slave_21_uds_resp : 7|64@0+ (1,0) [0|255] ""  IVI,DBCU

BO_ 987 BODY_PDU_SLAVE_21_UDS_REQ: 8 IVI
 SG_ PDU_slave_21_uds_req : 7|64@0+ (1,0) [0|255] ""  VCU

BO_ 990 BODY_PDU_SLAVE_22_UDS_RESP: 8 VCU
 SG_ PDU_slave_22_uds_resp : 7|64@0+ (1,0) [0|255] ""  IVI,DBCU

BO_ 989 BODY_PDU_SLAVE_22_UDS_REQ: 8 IVI
 SG_ PDU_slave_22_uds_req : 7|64@0+ (1,0) [0|255] ""  VCU

BO_ 992 BODY_PDU_SLAVE_23_UDS_RESP: 8 VCU
 SG_ PDU_slave_23_uds_resp : 7|64@0+ (1,0) [0|255] ""  IVI,DBCU

BO_ 991 BODY_PDU_SLAVE_23_UDS_REQ: 8 IVI
 SG_ PDU_slave_23_uds_req : 7|64@0+ (1,0) [0|255] ""  VCU

BO_ 994 BODY_PDU_SLAVE_24_UDS_RESP: 8 VCU
 SG_ PDU_slave_24_uds_resp : 7|64@0+ (1,0) [0|255] ""  IVI,DBCU

BO_ 993 BODY_PDU_SLAVE_24_UDS_REQ: 8 IVI
 SG_ PDU_slave_24_uds_req : 7|64@0+ (1,0) [0|255] ""  VCU

BO_ 996 BODY_PDU_SLAVE_25_UDS_RESP: 8 VCU
 SG_ PDU_slave_25_uds_resp : 7|64@0+ (1,0) [0|255] ""  IVI,DBCU

BO_ 995 BODY_PDU_SLAVE_25_UDS_REQ: 8 IVI
 SG_ PDU_slave_25_uds_req : 7|64@0+ (1,0) [0|255] ""  VCU

BO_ 998 BODY_PDU_SLAVE_26_UDS_RESP: 8 VCU
 SG_ PDU_slave_26_uds_resp : 7|64@0+ (1,0) [0|255] ""  IVI,DBCU

BO_ 997 BODY_PDU_SLAVE_26_UDS_REQ: 8 IVI
 SG_ PDU_slave_26_uds_req : 7|64@0+ (1,0) [0|255] ""  VCU

BO_ 1000 BODY_PDU_SLAVE_27_UDS_RESP: 8 VCU
 SG_ PDU_slave_27_uds_resp : 7|64@0+ (1,0) [0|255] ""  IVI,DBCU

BO_ 999 BODY_PDU_SLAVE_27_UDS_REQ: 8 IVI
 SG_ PDU_slave_27_uds_req : 7|64@0+ (1,0) [0|255] ""  VCU

BO_ 1002 BODY_PDU_SLAVE_28_UDS_RESP: 8 VCU
 SG_ PDU_slave_28_uds_resp : 7|64@0+ (1,0) [0|255] ""  IVI,DBCU

BO_ 1001 BODY_PDU_SLAVE_28_UDS_REQ: 8 IVI
 SG_ PDU_slave_28_uds_req : 7|64@0+ (1,0) [0|255] ""  VCU

BO_ 1004 BODY_PDU_SLAVE_29_UDS_RESP: 8 VCU
 SG_ PDU_slave_29_uds_resp : 7|64@0+ (1,0) [0|255] ""  IVI,DBCU

BO_ 1003 BODY_PDU_SLAVE_29_UDS_REQ: 8 IVI
 SG_ PDU_slave_29_uds_req : 7|64@0+ (1,0) [0|255] ""  VCU

BO_ 2297364746 H_PUMP_ST: 8 H_PUMP
 SG_ H_PUMP_motor_temp : 50|8@0- (1,80) [-48|207] "�C"  BCU_R,M2M
 SG_ H_PUMP_inverter_temp : 42|8@0- (1,80) [-48|207] "�C"  BCU_R,M2M
 SG_ H_PUMP_input_voltage : 34|8@0+ (0.25,0) [0|63.75] "V"  BCU_R,M2M
 SG_ H_PUMP_actual_current : 26|8@0+ (0.12,0) [0|30.6] "A"  BCU_R,M2M
 SG_ H_PUMP_actual_motor_speed : 22|12@0+ (1,0) [0|4095] "rpm"  BCU_R,M2M,IVI
 SG_ H_PUMP_motor_ST : 7|2@0+ (1,0) [0|3] ""  BCU_R,M2M
 SG_ H_PUMP_motor_temp_low_ERR : 13|1@0+ (1,0) [0|1] ""  BCU_R,M2M
 SG_ H_PUMP_motor_temp_high_ERR : 14|1@0+ (1,0) [0|1] ""  BCU_R,M2M
 SG_ H_PUMP_motor_start_ERR : 10|1@0+ (1,0) [0|1] ""  BCU_R,M2M
 SG_ H_PUMP_motor_rampup_ERR : 9|1@0+ (1,0) [0|1] ""  BCU_R,M2M
 SG_ H_PUMP_voltage_low_ERR : 8|1@0+ (1,0) [0|1] ""  BCU_R,M2M
 SG_ H_PUMP_voltage_high_ERR : 23|1@0+ (1,0) [0|1] ""  BCU_R,M2M
 SG_ H_PUMP_inverter_temp_high_ERR : 12|1@0+ (1,0) [0|1] ""  BCU_R,M2M
 SG_ H_PUMP_inverter_current_high_ERR : 11|1@0+ (1,0) [0|1] ""  BCU_R,M2M
 SG_ H_PUMP_motor_temp_low_WARN : 3|1@0+ (1,0) [0|1] ""  BCU_R,M2M
 SG_ H_PUMP_motor_temp_high_WARN : 4|1@0+ (1,0) [0|1] ""  BCU_R,M2M
 SG_ H_PUMP_voltage_low_WARN : 0|1@0+ (1,0) [0|1] ""  BCU_R,M2M
 SG_ H_PUMP_voltage_high_WARN : 15|1@0+ (1,0) [0|1] ""  BCU_R,M2M
 SG_ H_PUMP_inverter_temp_high_WARN : 2|1@0+ (1,0) [0|1] ""  BCU_R,M2M
 SG_ H_PUMP_inv_current_high_WARN : 1|1@0+ (1,0) [0|1] ""  BCU_R,M2M
 SG_ H_PUMP_rampup_ST : 5|1@0+ (1,0) [0|1] ""  BCU_R,M2M

BO_ 2364475905 BCU_R_hydraulic_pump: 2 BCU_R
 SG_ BCU_R_clear_err_REQ : 10|1@0+ (1,0) [0|1] ""  H_PUMP,M2M
 SG_ BCU_R_rampup_REQ : 6|1@0+ (1,0) [0|1] ""  H_PUMP,M2M
 SG_ BCU_R_motor_EN : 7|1@0+ (1,0) [0|1] ""  H_PUMP,M2M
 SG_ BCU_R_set_point_motor_speed_REQ : 5|11@0+ (1.2,600) [600|3000] "rpm"  H_PUMP,M2M

BO_ 1792 OFFCAR_ACU_func_REQ: 8 OFFCAR_ACU
 SG_ OFFCAR_ACU_functional_REQ : 7|64@0+ (1,0) [0|0] ""  ACU

BO_ 2033 OFFCAR_ACU_dply_REQ: 8 OFFCAR_ACU
 SG_ OFFCAR_ACU_deployment_REQ : 7|64@0+ (1,0) [0|0] ""  ACU

BO_ 1813 BODY_ACU_UDS_REQ: 8 IVI
 SG_ ACU_uds_req : 7|64@0+ (1,0) [0|0] ""  ACU

BO_ 2041 OFFCAR_ACU_dply_RESP: 8 ACU
 SG_ ACU_airbag_deployment_RESP : 7|64@0+ (1,0) [0|0] ""  OFFCAR_ACU

BO_ 1919 BODY_ACU_UDS_RESP: 8 ACU
 SG_ ACU_uds_resp : 7|64@0+ (1,0) [0|0] ""  IVI,DBCU

BO_ 80 BODY_ACU_crash_output: 2 ACU
 SG_ ACU_front_crash_ST : 0|1@0+ (1,0) [0|1] ""  VCU,M2M
 SG_ ACU_driver_side_crash_ST : 1|1@0+ (1,0) [0|1] ""  VCU,M2M
 SG_ ACU_psg_side_crash_ST : 2|1@0+ (1,0) [0|1] ""  VCU,M2M
 SG_ ACU_rear_crash_ST : 3|1@0+ (1,0) [0|1] ""  VCU,M2M
 SG_ ACU_roll_crash_ST : 4|1@0+ (1,0) [0|1] ""  VCU,M2M
 SG_ ACU_driver_belt_dply_ST : 5|1@0+ (1,0) [0|1] ""  VCU,M2M
 SG_ ACU_psg_belt_dply_ST : 6|1@0+ (1,0) [0|1] ""  VCU,M2M
 SG_ ACU_driver_F_AB_1st_stg_dply_ST : 7|1@0+ (1,0) [0|1] ""  VCU,M2M
 SG_ ACU_driver_F_AB_2nd_stg_dply_ST : 8|1@0+ (1,0) [0|1] ""  VCU,M2M
 SG_ ACU_psg_F_AB_1st_stg_dply_ST : 9|1@0+ (1,0) [0|1] ""  VCU,M2M
 SG_ ACU_psg_F_AB_2nd_stg_dply_ST : 10|1@0+ (1,0) [0|1] ""  VCU,M2M
 SG_ ACU_psg_side_AB_dply_ST : 12|1@0+ (1,0) [0|1] ""  VCU,M2M
 SG_ ACU_driver_side_AB_dply_ST : 11|1@0+ (1,0) [0|1] ""  VCU,M2M
 SG_ ACU_battery_cutoff_dply_ST : 13|1@0+ (1,0) [0|1] ""  VCU,M2M

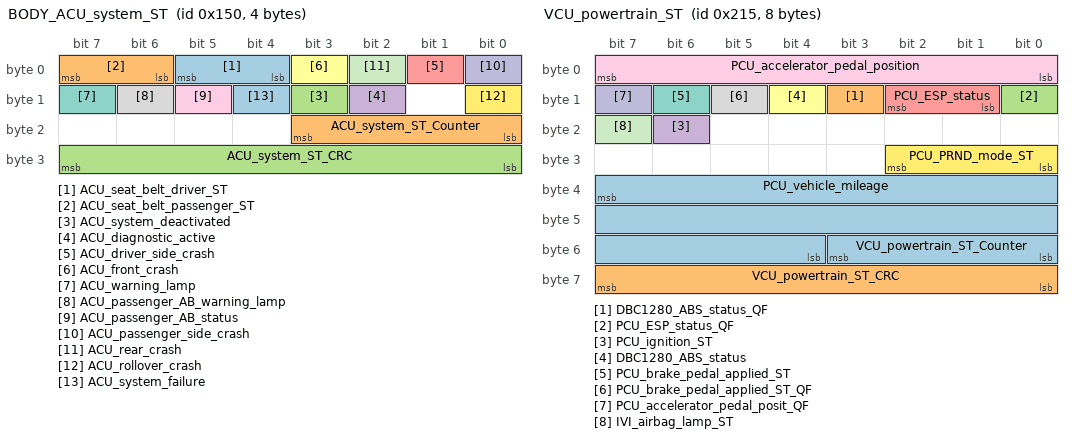
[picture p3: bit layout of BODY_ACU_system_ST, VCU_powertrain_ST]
BO_ 336 BODY_ACU_system_ST: 4 ACU
 SG_ ACU_seat_belt_driver_ST : 5|2@0+ (1,0) [0|3] ""  VCU,IVI,M2M
 SG_ ACU_seat_belt_passenger_ST : 7|2@0+ (1,0) [0|3] ""  VCU,IVI,SCU_PSG,M2M
 SG_ ACU_system_deactivated : 11|1@0+ (1,0) [0|1] ""  VCU,IVI,M2M
 SG_ ACU_diagnostic_active : 10|1@0+ (1,0) [0|1] ""  VCU,IVI,M2M
 SG_ ACU_driver_side_crash : 1|1@0+ (1,0) [0|1] ""  VCU,IVI,BCU_F,M2M
 SG_ ACU_front_crash : 3|1@0+ (1,0) [0|1] ""  VCU,IVI,BCU_F,M2M
 SG_ ACU_warning_lamp : 15|1@0+ (1,0) [0|1] ""  VCU,IVI,M2M
 SG_ ACU_passenger_AB_warning_lamp : 14|1@0+ (1,0) [0|1] ""  VCU,IVI,M2M
 SG_ ACU_passenger_AB_status : 13|1@0+ (1,0) [0|1] ""  VCU,IVI,M2M
 SG_ ACU_passenger_side_crash : 0|1@0+ (1,0) [0|1] ""  VCU,IVI,BCU_F,M2M
 SG_ ACU_rear_crash : 2|1@0+ (1,0) [0|1] ""  VCU,IVI,BCU_F,M2M
 SG_ ACU_rollover_crash : 8|1@0+ (1,0) [0|1] ""  VCU,IVI,BCU_F,M2M
 SG_ ACU_system_failure : 12|1@0+ (1,0) [0|1] ""  VCU,IVI,M2M
 SG_ ACU_system_ST_Counter : 19|4@0+ (1,0) [0|15] ""  VCU,IVI
 SG_ ACU_system_ST_CRC : 31|8@0+ (1,0) [0|255] ""  VCU,IVI

BO_ 533 VCU_powertrain_ST: 8 VCU
 SG_ PCU_vehicle_mileage : 39|20@0+ (1,0) [0|1048575] "km"  ACU,M2M
 SG_ DBC1280_ABS_status_QF : 11|1@0+ (1,0) [0|1] ""  ACU,M2M
 SG_ PCU_ESP_status_QF : 8|1@0+ (1,0) [0|1] ""  ACU,M2M
 SG_ PCU_ignition_ST : 22|1@0+ (1,0) [0|1] ""  ACU,M2M
 SG_ PCU_ESP_status : 10|2@0+ (1,0) [0|2] ""  ACU,M2M
 SG_ DBC1280_ABS_status : 12|1@0+ (1,0) [0|1] ""  ACU,M2M
 SG_ PCU_brake_pedal_applied_ST : 14|1@0+ (1,0) [0|1] ""  ACU,M2M
 SG_ PCU_brake_pedal_applied_ST_QF : 13|1@0+ (1,0) [0|1] ""  ACU,M2M
 SG_ PCU_accelerator_pedal_position : 7|8@0+ (0.4,0) [0|100] "%"  ACU,M2M
 SG_ PCU_accelerator_pedal_posit_QF : 15|1@0+ (1,0) [0|1] ""  ACU,M2M
 SG_ IVI_airbag_lamp_ST : 23|1@0+ (1,0) [0|1] ""  ACU,M2M
 SG_ PCU_PRND_mode_ST : 26|3@0+ (1,0) [0|7] "enum"  ACU,M2M
 SG_ VCU_powertrain_ST_Counter : 51|4@0+ (1,0) [0|15] ""  ACU
 SG_ VCU_powertrain_ST_CRC : 63|8@0+ (1,0) [0|255] ""  ACU

BO_ 1024 VCU_VIN: 8 VCU
 SG_ VIN_9 m1 : 23|8@0+ (1,0) [0|255] ""  ACU
 SG_ VIN_8 m1 : 15|8@0+ (1,0) [0|255] ""  ACU
 SG_ VIN_7 m0 : 63|8@0+ (1,0) [0|255] ""  ACU
 SG_ VIN_6 m0 : 55|8@0+ (1,0) [0|255] ""  ACU
 SG_ VIN_5 m0 : 47|8@0+ (1,0) [0|255] ""  ACU
 SG_ VIN_4 m0 : 39|8@0+ (1,0) [0|255] ""  ACU
 SG_ VIN_3 m0 : 31|8@0+ (1,0) [0|255] ""  ACU
 SG_ VIN_2 m0 : 23|8@0+ (1,0) [0|255] ""  ACU
 SG_ VIN_17 m2 : 31|8@0+ (1,0) [0|255] ""  ACU
 SG_ VIN_16 m2 : 23|8@0+ (1,0) [0|255] ""  ACU
 SG_ VIN_15 m2 : 15|8@0+ (1,0) [0|255] ""  ACU
 SG_ VIN_14 m1 : 63|8@0+ (1,0) [0|255] ""  ACU
 SG_ VIN_13 m1 : 55|8@0+ (1,0) [0|255] ""  ACU
 SG_ VIN_12 m1 : 47|8@0+ (1,0) [0|255] ""  ACU
 SG_ VIN_11 m1 : 39|8@0+ (1,0) [0|255] ""  ACU
 SG_ VIN_10 m1 : 31|8@0+ (1,0) [0|255] ""  ACU
 SG_ VIN_1 m0 : 15|8@0+ (1,0) [0|255] ""  ACU
 SG_ VIN_MUX M : 7|8@0+ (1,0) [0|255] ""  ACU

BO_ 523 BODY_IVI_timestamp: 5 IVI
 SG_ IVI_date_year : 7|7@0+ (1,2000) [2000|2127] "year"  ACU,VCU,M2M,SKM,SWCU
 SG_ IVI_date_second : 39|6@0+ (1,0) [0|59] "second"  ACU,VCU,M2M,SKM,SWCU
 SG_ IVI_date_month : 0|4@0+ (1,0) [0|12] "month"  ACU,VCU,M2M,SKM,SWCU
 SG_ IVI_date_minute : 31|6@0+ (1,0) [0|59] "minute"  ACU,VCU,M2M,SKM,SWCU
 SG_ IVI_date_hour : 23|5@0+ (1,0) [0|23] "hour"  ACU,VCU,M2M,SKM,SWCU
 SG_ IVI_date_day : 12|5@0+ (1,0) [0|31] "day"  ACU,VCU,M2M,SKM,SWCU

BO_ 524 IVI_ambient_lights_REQ: 7 IVI
 SG_ IVI_red_REQ : 7|8@0+ (1,0) [0|255] ""  DBCU,BCU_R,M2M
 SG_ IVI_green_REQ : 15|8@0+ (1,0) [0|255] ""  DBCU,BCU_R,M2M
 SG_ IVI_blue_REQ : 23|8@0+ (1,0) [0|255] ""  DBCU,BCU_R,M2M
 SG_ IVI_intensity_REQ : 31|4@0+ (6.67,0) [0|100] "%"  DBCU,BCU_R,M2M
 SG_ IVI_white_red_REQ : 39|8@0+ (1,0) [0|255] ""  DBCU,BCU_R,M2M
 SG_ IVI_white_green_REQ : 47|8@0+ (1,0) [0|255] ""  DBCU,BCU_R,M2M
 SG_ IVI_white_blue_REQ : 55|8@0+ (1,0) [0|255] ""  DBCU,BCU_R,M2M

BO_ 660 BODY_CCU_REQ: 1 VCU
 SG_ CCU_F_aero_cooling_REQ : 7|2@0+ (1,0) [0|3] "enum"  BCU_F
 SG_ CCU_R_aero_cooling_REQ : 5|2@0+ (1,0) [0|3] "enum"  BCU_R

BO_ 1155 OFFCAR_IVI_Bootloader: 8 OFFCAR_VCU
 SG_ OFFCAR_IVI_bootloader : 0|64@1+ (1,0) [0|0] ""  IVI

BO_ 1154 IVI_Bootloader: 8 IVI
 SG_ IVI_bootloader : 0|64@1+ (1,0) [0|0] ""  OFFCAR_VCU

BO_ 642 OFFCAR_SKM_REQ: 1 OFFCAR_SKM
 SG_ OFFCAR_SKM_PEPS_EN : 5|1@0+ (1,0) [0|0] ""  SKM
 SG_ OFFCAR_SKM_learning_mode_EN : 4|3@0+ (1,0) [0|0] ""  SKM
 SG_ OFFCAR_SKM_IMMO_mode_EN : 6|1@0+ (1,0) [0|0] ""  SKM
 SG_ OFFCAR_SKM_ignition_ST : 7|1@0+ (1,0) [0|0] ""  SKM

BO_ 117 BODY_EPS_02: 8 VCU
 SG_ EPS_PinionAgValid : 9|2@0+ (1,0) [0|3] "" BCU_F,BCU_R
 SG_ EPS_PinionAg : 22|15@0+ (0.1,-1638.4) [-1638.4|1638.2] "Deg" BCU_F,BCU_R

BO_ 641 OFFCAR_SKM_KEYFOB_learn_value: 8 OFFCAR_SKM
 SG_ OFFCAR_SKM_key_learn_val_4 : 55|16@0+ (1,0) [0|65535] ""  SKM
 SG_ OFFCAR_SKM_key_learn_val_3 : 39|16@0+ (1,0) [0|65535] ""  SKM
 SG_ OFFCAR_SKM_key_learn_val_2 : 23|16@0+ (1,0) [0|65535] ""  SKM
 SG_ OFFCAR_SKM_key_learn_val_1 : 7|16@0+ (1,0) [0|65535] ""  SKM

BO_ 1294 IVI_ERR: 8 IVI
 SG_ IVI_reserved_ERR : 7|64@0+ (1,0) [0|0] ""  VCU,M2M

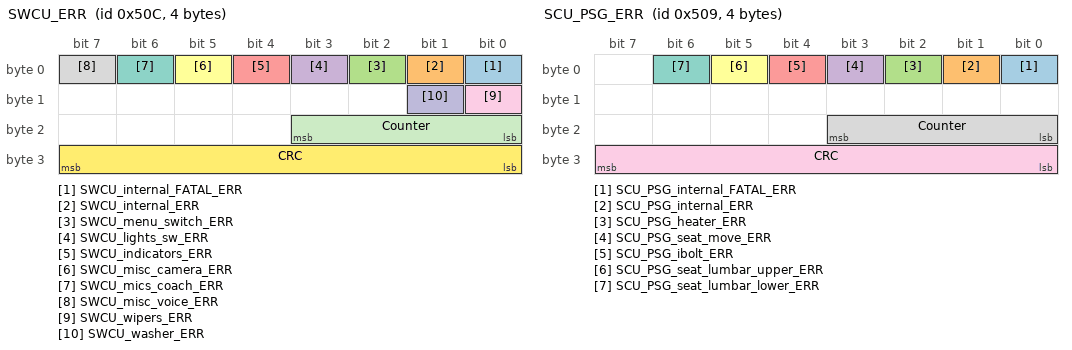
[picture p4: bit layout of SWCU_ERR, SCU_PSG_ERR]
BO_ 1292 SWCU_ERR: 4 SWCU
 SG_ SWCU_internal_FATAL_ERR : 0|1@0+ (1,0) [0|1] "" VCU,IVI,M2M
 SG_ SWCU_internal_ERR : 1|1@0+ (1,0) [0|1] "" VCU,IVI,M2M
 SG_ SWCU_menu_switch_ERR : 2|1@0+ (1,0) [0|1] "" VCU,IVI,M2M
 SG_ SWCU_lights_sw_ERR : 3|1@0+ (1,0) [0|1] "" VCU,IVI,M2M
 SG_ SWCU_indicators_ERR : 4|1@0+ (1,0) [0|1] "" VCU,IVI,M2M
 SG_ SWCU_misc_camera_ERR : 5|1@0+ (1,0) [0|1] "" VCU,IVI,M2M
 SG_ SWCU_mics_coach_ERR : 6|1@0+ (1,0) [0|1] "" VCU,IVI,M2M
 SG_ SWCU_misc_voice_ERR : 7|1@0+ (1,0) [0|1] "" VCU,IVI,M2M
 SG_ SWCU_wipers_ERR : 8|1@0+ (1,0) [0|1] "" VCU,IVI,M2M
 SG_ SWCU_washer_ERR : 9|1@0+ (1,0) [0|1] "" VCU,IVI,M2M
 SG_ Counter : 19|4@0+ (1,0)[0|15] "" VCU,IVI,M2M
 SG_ CRC : 31|8@0+ (1,0)[0|255] "" VCU,IVI,M2M

BO_ 779 BODY_PCU_suspension_ST: 4 VCU
 SG_ PCU_suspension_lvl_RR : 31|8@0+ (0.1,-12.5) [-12.5|13] "mm"  BCU_R
 SG_ PCU_suspension_lvl_RL : 23|8@0+ (0.1,-12.5) [-12.5|13] "mm"  BCU_R
 SG_ PCU_suspension_lvl_FR : 15|8@0+ (0.1,-12.5) [-12.5|13] "mm"  BCU_R
 SG_ PCU_suspension_lvl_FL : 7|8@0+ (0.1,-12.5) [-12.5|13] "mm"  BCU_R

BO_ 1289 SCU_PSG_ERR: 4 SCU_PSG
 SG_ SCU_PSG_internal_FATAL_ERR : 0|1@0+ (1,0) [0|1] "" VCU,IVI,M2M
 SG_ SCU_PSG_internal_ERR : 1|1@0+ (1,0) [0|1] "" VCU,IVI,M2M
 SG_ SCU_PSG_heater_ERR : 2|1@0+ (1,0) [0|1] "" VCU,IVI,M2M
 SG_ SCU_PSG_seat_move_ERR : 3|1@0+ (1,0) [0|1] "" VCU,IVI,M2M
 SG_ SCU_PSG_ibolt_ERR : 4|1@0+ (1,0) [0|1] "" VCU,IVI,M2M
 SG_ SCU_PSG_seat_lumbar_upper_ERR : 5|1@0+ (1,0) [0|1] "" IVI,VCU,M2M
 SG_ SCU_PSG_seat_lumbar_lower_ERR : 6|1@0+ (1,0) [0|1] "" IVI,VCU,M2M
 SG_ Counter : 19|4@0+ (1,0)[0|15] "" VCU,IVI,M2M
 SG_ CRC : 31|8@0+ (1,0)[0|255] "" VCU,IVI,M2M

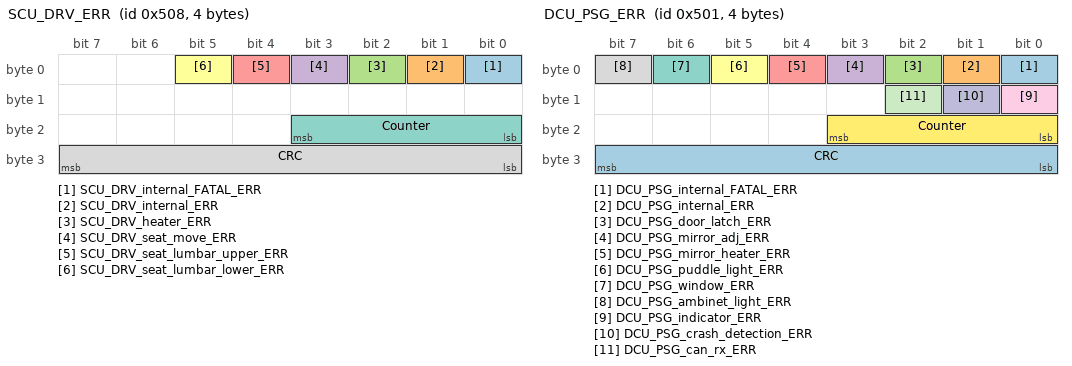
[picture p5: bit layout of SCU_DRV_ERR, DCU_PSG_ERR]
BO_ 1288 SCU_DRV_ERR: 4 SCU_DRV
 SG_ SCU_DRV_internal_FATAL_ERR : 0|1@0+ (1,0) [0|1] "" VCU,IVI,M2M
 SG_ SCU_DRV_internal_ERR : 1|1@0+ (1,0) [0|1] "" VCU,IVI,M2M
 SG_ SCU_DRV_heater_ERR : 2|1@0+ (1,0) [0|1] "" VCU,IVI,M2M
 SG_ SCU_DRV_seat_move_ERR : 3|1@0+ (1,0) [0|1] "" VCU,IVI,M2M
 SG_ SCU_DRV_seat_lumbar_upper_ERR : 4|1@0+ (1,0) [0|1] "" IVI,VCU,M2M
 SG_ SCU_DRV_seat_lumbar_lower_ERR : 5|1@0+ (1,0) [0|1] "" IVI,VCU,M2M
 SG_ Counter : 19|4@0+ (1,0)[0|15] "" VCU,IVI,M2M
 SG_ CRC : 31|8@0+ (1,0)[0|255] "" VCU,IVI,M2M

BO_ 1283 DBCU_ERR: 4 DBCU
 SG_ DBCU_internal_FATAL_ERR : 0|1@0+ (1,0) [0|1] ""  VCU,IVI,M2M
 SG_ DBCU_internal_ERR : 1|1@0+ (1,0) [0|1] ""  VCU,IVI,M2M
 SG_ DBCU_camera_heater_ERR : 2|1@0+ (1,0) [0|1] ""  VCU,IVI,M2M
 SG_ DBCU_glovebox_ERR : 3|1@0+ (1,0) [0|1] ""  VCU,IVI,M2M
 SG_ DBCU_horn_sw_ERR : 4|1@0+ (1,0) [0|1] ""  VCU,IVI,M2M
 SG_ DBCU_illumination_ERR : 5|1@0+ (1,0) [0|1] ""  VCU,IVI,M2M
 SG_ DBCU_IVI_disp_pwr_ERR : 6|1@0+ (1,0) [0|1] ""  VCU,IVI,M2M
 SG_ DBCU_IVI_eth_pwr_ERR : 7|1@0+ (1,0) [0|1] ""  VCU,IVI,M2M
 SG_ DBCU_pre_amp_ERR : 8|1@0+ (1,0) [0|1] ""  VCU,IVI,M2M
 SG_ DBCU_SWCU_pwr_ERR : 9|1@0+ (1,0) [0|1] ""  VCU,IVI,M2M
 SG_ DBCU_steering_clmn_depth_ERR : 10|1@0+ (1,0) [0|1] ""  VCU,IVI,M2M
 SG_ DBCU_steering_clmn_height_ERR : 11|1@0+ (1,0) [0|1] ""  VCU,IVI,M2M
 SG_ DBCU_illumination_knob_ERR : 12|1@0+ (1,0) [0|1] ""  VCU,IVI,M2M
 SG_ DBCU_diag_port_pwr_ERR : 13|1@0+ (1,0) [0|1] ""  VCU,IVI,M2M
 SG_ DBCU_IVI_disp_knob_pwr_ERR : 14|1@0+ (1,0) [0|1] ""  VCU,IVI,M2M
 SG_ DBCU_CCCU_pwr_ERR : 15|1@0+ (1,0) [0|1] ""  VCU,IVI,M2M
 SG_ Counter : 19|4@0+ (1,0) [0|15] ""  VCU,IVI,M2M
 SG_ CRC : 31|8@0+ (1,0) [0|255] ""  VCU,IVI,M2M

BO_ 1281 DCU_PSG_ERR: 4 DCU_PSG
 SG_ DCU_PSG_internal_FATAL_ERR : 0|1@0+ (1,0) [0|1] ""  VCU,IVI,M2M
 SG_ DCU_PSG_internal_ERR : 1|1@0+ (1,0) [0|1] ""  VCU,IVI,M2M
 SG_ DCU_PSG_door_latch_ERR : 2|1@0+ (1,0) [0|1] ""  VCU,IVI,M2M
 SG_ DCU_PSG_mirror_adj_ERR : 3|1@0+ (1,0) [0|1] ""  VCU,IVI,M2M
 SG_ DCU_PSG_mirror_heater_ERR : 4|1@0+ (1,0) [0|1] ""  VCU,IVI,M2M
 SG_ DCU_PSG_puddle_light_ERR : 5|1@0+ (1,0) [0|1] ""  VCU,IVI,M2M
 SG_ DCU_PSG_window_ERR : 6|1@0+ (1,0) [0|1] ""  VCU,IVI,M2M
 SG_ DCU_PSG_ambinet_light_ERR : 7|1@0+ (1,0) [0|1] ""  VCU,IVI,M2M
 SG_ DCU_PSG_indicator_ERR : 8|1@0+ (1,0) [0|1] ""  VCU,IVI,M2M
 SG_ DCU_PSG_crash_detection_ERR : 9|1@0+ (1,0) [0|1] ""  VCU,IVI,M2M
 SG_ DCU_PSG_can_rx_ERR : 10|1@0+ (1,0) [0|1] ""  VCU,IVI,M2M
 SG_ Counter : 19|4@0+ (1,0) [0|15] ""  VCU,IVI,M2M
 SG_ CRC : 31|8@0+ (1,0) [0|255] ""  VCU,IVI,M2M

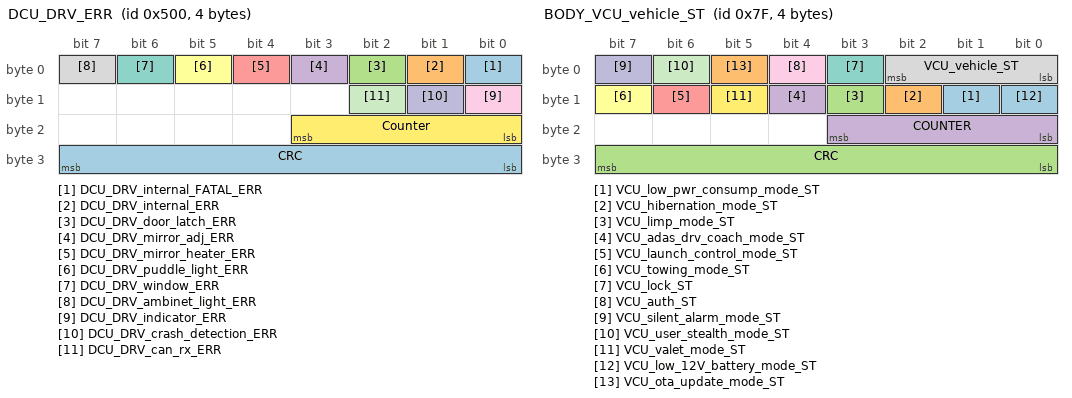
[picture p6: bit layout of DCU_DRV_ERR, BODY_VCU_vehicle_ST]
BO_ 1280 DCU_DRV_ERR: 4 DCU_DRV
 SG_ DCU_DRV_internal_FATAL_ERR : 0|1@0+ (1,0) [0|1] ""  VCU,IVI,M2M
 SG_ DCU_DRV_internal_ERR : 1|1@0+ (1,0) [0|1] ""  VCU,IVI,M2M
 SG_ DCU_DRV_door_latch_ERR : 2|1@0+ (1,0) [0|1] ""  VCU,IVI,M2M
 SG_ DCU_DRV_mirror_adj_ERR : 3|1@0+ (1,0) [0|1] ""  VCU,IVI,M2M
 SG_ DCU_DRV_mirror_heater_ERR : 4|1@0+ (1,0) [0|1] ""  VCU,IVI,M2M
 SG_ DCU_DRV_puddle_light_ERR : 5|1@0+ (1,0) [0|1] ""  VCU,IVI,M2M
 SG_ DCU_DRV_window_ERR : 6|1@0+ (1,0) [0|1] ""  VCU,IVI,M2M
 SG_ DCU_DRV_ambinet_light_ERR : 7|1@0+ (1,0) [0|1] ""  VCU,IVI,M2M
 SG_ DCU_DRV_indicator_ERR : 8|1@0+ (1,0) [0|1] ""  VCU,IVI,M2M
 SG_ DCU_DRV_crash_detection_ERR : 9|1@0+ (1,0) [0|1] ""  VCU,IVI,M2M
 SG_ DCU_DRV_can_rx_ERR : 10|1@0+ (1,0) [0|1] ""  VCU,IVI,M2M
 SG_ Counter : 19|4@0+ (1,0) [0|15] ""  VCU,IVI,M2M
 SG_ CRC : 31|8@0+ (1,0) [0|255] ""  VCU,IVI,M2M

BO_ 1319 SKM_KEYFOB_RKE_RSSI_DBG: 8 SKM
 SG_ SKM_KEYFOB_4_RKE_RSSI : 55|16@0+ (1,0) [0|0] ""  OFFCAR_SKM
 SG_ SKM_KEYFOB_3_RKE_RSSI : 39|16@0+ (1,0) [0|0] ""  OFFCAR_SKM
 SG_ SKM_KEYFOB_2_RKE_RSSI : 23|16@0+ (1,0) [0|0] ""  OFFCAR_SKM
 SG_ SKM_KEYFOB_1_RKE_RSSI : 7|16@0+ (1,0) [0|0] ""  OFFCAR_SKM

BO_ 2032 OFFCAR_command_REQ: 8 OFFCAR_VCU
 SG_ OFFCAR_mule_gear_REQ : 7|1@0+ (1,0) [0|1] "enum"  BCU_R

BO_ 1579 OFFCAR_VCU_XCP: 8 OFFCAR_VCU
 SG_ OFFCAR_VCU_xcp : 0|64@1+ (1,0) [0|0] ""  VCU

BO_ 1578 VCU_XCP: 8 VCU
 SG_ VCU_xcp : 0|64@1+ (1,0) [0|0] ""  OFFCAR_VCU

BO_ 1573 OFFCAR_SWCU_XCP: 8 OFFCAR_VCU
 SG_ OFFCAR_SWCU_xcp : 0|64@1+ (1,0) [0|0] ""  SWCU

BO_ 1572 SWCU_XCP: 8 SWCU
 SG_ SWCU_xcp : 0|64@1+ (1,0) [0|0] ""  OFFCAR_VCU

BO_ 1571 OFFCAR_SKM_XCP: 8 OFFCAR_VCU
 SG_ OFFCAR_SKM_xcp : 0|64@1+ (1,0) [0|0] ""  SKM

BO_ 1570 SKM_XCP: 8 SKM
 SG_ SKM_xcp : 0|64@1+ (1,0) [0|0] ""  OFFCAR_VCU

BO_ 1566 OFFCAR_DCU_PSG_XCP: 8 OFFCAR_VCU
 SG_ OFFCAR_DCU_PSG_xcp : 0|64@1+ (1,0) [0|0] ""  DCU_PSG

BO_ 1565 DCU_PSG_XCP: 8 DCU_PSG
 SG_ DCU_PSG_xcp : 0|64@1+ (1,0) [0|0] ""  OFFCAR_VCU

BO_ 1563 OFFCAR_DCU_DRV_XCP: 8 OFFCAR_VCU
 SG_ OFFCAR_DCU_DRV_xcp : 0|64@1+ (1,0) [0|0] ""  DCU_DRV

BO_ 1562 DCU_DRV_XCP: 8 DCU_DRV
 SG_ DCU_DRV_xcp : 0|64@1+ (1,0) [0|0] ""  OFFCAR_VCU

BO_ 1561 OFFCAR_DBCU_XCP: 8 OFFCAR_VCU
 SG_ OFFCAR_DBCU_xcp : 0|64@1+ (1,0) [0|0] ""  DBCU

BO_ 1560 DBCU_XCP: 8 DBCU
 SG_ DBCU_xcp : 0|64@1+ (1,0) [0|0] ""  OFFCAR_VCU

BO_ 1555 OFFCAR_BCU_R_XCP: 8 OFFCAR_VCU
 SG_ OFFCAR_BCU_R_xcp : 0|64@1+ (1,0) [0|0] ""  BCU_R

BO_ 1554 BCU_R_XCP: 8 BCU_R
 SG_ BCU_R_xcp : 0|64@1+ (1,0) [0|0] ""  OFFCAR_VCU

BO_ 1553 OFFCAR_BCU_F_XCP: 8 OFFCAR_VCU
 SG_ OFFCAR_BCU_F_xcp : 0|64@1+ (1,0) [0|0] ""  BCU_F

BO_ 1552 BCU_F_XCP: 8 BCU_F
 SG_ BCU_F_xcp : 0|64@1+ (1,0) [0|0] ""  OFFCAR_VCU

BO_ 1539 OFFCAR_SCU_PSG_XCP: 8 OFFCAR_VCU
 SG_ OFFCAR_SCU_PSG_xcp : 0|64@1+ (1,0) [0|0] ""  SCU_PSG

BO_ 1538 SCU_PSG_XCP: 8 SCU_PSG
 SG_ SCU_PSG_xcp : 0|64@1+ (1,0) [0|0] ""  OFFCAR_VCU

BO_ 1537 OFFCAR_SCU_DRV_XCP: 8 OFFCAR_VCU
 SG_ OFFCAR_SCU_DRV_xcp : 0|64@1+ (1,0) [0|0] ""  SCU_DRV

BO_ 1536 SCU_DRV_XCP: 8 SCU_DRV
 SG_ SCU_DRV_xcp : 0|64@1+ (1,0) [0|0] ""  OFFCAR_VCU

BO_ 127 BODY_VCU_vehicle_ST: 4 VCU
 SG_ VCU_low_pwr_consump_mode_ST : 9|1@0+ (1,0) [0|1] "" IVI,M2M,SCU_DRV,SCU_PSG,SWCU,DCU_DRV,DCU_PSG,SKM,DBCU,BCU_F,BCU_R
 SG_ VCU_hibernation_mode_ST : 10|1@0+ (1,0) [0|1] "" IVI,M2M
 SG_ VCU_limp_mode_ST : 11|1@0+ (1,0) [0|1] "" IVI,M2M
 SG_ VCU_adas_drv_coach_mode_ST : 12|1@0+ (1,0) [0|1] "" IVI,M2M,SWCU
 SG_ VCU_launch_control_mode_ST : 14|1@0+ (1,0) [0|1] "" IVI,M2M,SWCU
 SG_ VCU_towing_mode_ST : 15|1@0+ (1,0) [0|1] "" IVI,M2M
 SG_ VCU_lock_ST : 3|1@0+ (1,0) [0|1] ""  BCU_R,IVI,DCU_PSG,DCU_DRV,M2M
 SG_ VCU_vehicle_ST : 2|3@0+ (1,0) [0|7] ""  SWCU,SCU_PSG,SCU_DRV,IVI,DCU_PSG,DCU_DRV,BCU_R,BCU_F,SKM,DBCU,M2M
 SG_ VCU_auth_ST : 4|1@0+ (1,0) [0|1] ""  IVI,M2M
 SG_ VCU_silent_alarm_mode_ST : 7|1@0+ (1,0) [0|1] ""  IVI,M2M,SWCU,DCU_DRV,DCU_PSG,SKM,BCU_F,BCU_R,DBCU
 SG_ VCU_user_stealth_mode_ST : 6|1@0+ (1,0) [0|1] ""  IVI,M2M,SCU_DRV,SCU_PSG,SWCU,DCU_DRV,DCU_PSG,SKM,DBCU,BCU_F,BCU_R
 SG_ VCU_valet_mode_ST : 13|1@0+ (1,0) [0|1] ""  IVI,M2M,SCU_DRV,SCU_PSG,SWCU,DCU_DRV,DCU_PSG,SKM,DBCU,BCU_F,BCU_R
 SG_ VCU_low_12V_battery_mode_ST : 8|1@0+ (1,0) [0|1] "" IVI,M2M,SCU_DRV,SCU_PSG,SWCU,DCU_DRV,DCU_PSG,SKM,DBCU,BCU_F,BCU_R
 SG_ VCU_ota_update_mode_ST : 5|1@0+ (1,0) [0|1] "" IVI,M2M,SCU_DRV,SCU_PSG,SWCU,DCU_DRV,DCU_PSG,SKM,DBCU,BCU_F,BCU_R
 SG_ CRC : 31|8@0+ (1,0) [0|255] ""  SWCU,SCU_PSG,SCU_DRV,IVI,DCU_PSG,DCU_DRV,SKM,BCU_R,BCU_F,DBCU
 SG_ COUNTER : 19|4@0+ (1,0) [0|15] ""  SWCU,SCU_PSG,SCU_DRV,IVI,DCU_PSG,DCU_DRV,SKM,BCU_R,BCU_F,DBCU

BO_ 803 SKM_KEYFOB_learn_value: 8 SKM
 SG_ SKM_VCU_key_learn_val_4 : 55|16@0+ (1,0) [0|65535] ""  OFFCAR_SKM
 SG_ SKM_VCU_key_learn_val_3 : 39|16@0+ (1,0) [0|65535] ""  OFFCAR_SKM
 SG_ SKM_VCU_key_learn_val_2 : 23|16@0+ (1,0) [0|65535] ""  OFFCAR_SKM
 SG_ SKM_VCU_key_learn_val_1 : 7|16@0+ (1,0) [0|65535] ""  OFFCAR_SKM

BO_ 1153 OFFCAR_SKM_Bootloader: 8 OFFCAR_VCU
 SG_ OFFCAR_SKM_bootloader : 0|64@1+ (1,0) [0|0] ""  SKM

BO_ 1152 SKM_Bootloader: 8 SKM
 SG_ SKM_bootloader : 0|64@1+ (1,0) [0|0] ""  OFFCAR_VCU

BO_ 1318 SKM_KEYFOB_4_RSSI_DBG: 8 SKM
 SG_ SKM_KEYFOB_4_RSSI_4 : 55|16@0+ (1,0) [0|65535] ""  OFFCAR_SKM
 SG_ SKM_KEYFOB_4_RSSI_3 : 39|16@0+ (1,0) [0|65535] ""  OFFCAR_SKM
 SG_ SKM_KEYFOB_4_RSSI_2 : 23|16@0+ (1,0) [0|65535] ""  OFFCAR_SKM
 SG_ SKM_KEYFOB_4_RSSI_1 : 7|16@0+ (1,0) [0|65535] ""  OFFCAR_SKM

BO_ 1317 SKM_KEYFOB_3_RSSI_DBG: 8 SKM
 SG_ SKM_KEYFOB_3_RSSI_4 : 55|16@0+ (1,0) [0|65535] ""  OFFCAR_SKM
 SG_ SKM_KEYFOB_3_RSSI_3 : 39|16@0+ (1,0) [0|65535] ""  OFFCAR_SKM
 SG_ SKM_KEYFOB_3_RSSI_2 : 23|16@0+ (1,0) [0|65535] ""  OFFCAR_SKM
 SG_ SKM_KEYFOB_3_RSSI_1 : 7|16@0+ (1,0) [0|65535] ""  OFFCAR_SKM

BO_ 1316 SKM_KEYFOB_2_RSSI_DBG: 8 SKM
 SG_ SKM_KEYFOB_2_RSSI_4 : 55|16@0+ (1,0) [0|65535] ""  OFFCAR_SKM
 SG_ SKM_KEYFOB_2_RSSI_3 : 39|16@0+ (1,0) [0|65535] ""  OFFCAR_SKM
 SG_ SKM_KEYFOB_2_RSSI_2 : 23|16@0+ (1,0) [0|65535] ""  OFFCAR_SKM
 SG_ SKM_KEYFOB_2_RSSI_1 : 7|16@0+ (1,0) [0|65535] ""  OFFCAR_SKM

BO_ 1315 SKM_KEYFOB_1_RSSI_DBG: 8 SKM
 SG_ SKM_KEYFOB_1_RSSI_4 : 55|16@0+ (1,0) [0|65535] ""  OFFCAR_SKM
 SG_ SKM_KEYFOB_1_RSSI_3 : 39|16@0+ (1,0) [0|65535] ""  OFFCAR_SKM
 SG_ SKM_KEYFOB_1_RSSI_2 : 23|16@0+ (1,0) [0|65535] ""  OFFCAR_SKM
 SG_ SKM_KEYFOB_1_RSSI_1 : 7|16@0+ (1,0) [0|65535] ""  OFFCAR_SKM

BO_ 640 VCU_SKM_REQ: 3 VCU
 SG_ VCU_PEPS_EN : 6|1@0+ (1,0) [0|1] ""  SKM,M2M
 SG_ VCU_IMMO_mode_EN : 7|1@0+ (1,0) [0|1] ""  SKM,M2M
 SG_ CRC : 23|8@0+ (1,0) [0|255] ""  SKM
 SG_ COUNTER : 11|4@0+ (1,0) [0|15] ""  SKM

BO_ 1041 SKM_version_info: 8 SKM
 SG_ SKM_FW_commit_hash m1 : 39|32@0+ (1,0) [0|0] ""  OFFCAR_SKM,OFFCAR_VCU,M2M
 SG_ SKM_BL_commit_hash m0 : 39|32@0+ (1,0) [0|0] ""  OFFCAR_SKM,OFFCAR_VCU,M2M
 SG_ SKM_version_dbc m3 : 63|8@0+ (1,0) [0|255] ""  OFFCAR_SKM,OFFCAR_VCU,M2M
 SG_ SKM_BL_version_dev m0 : 5|1@0+ (1,0) [0|1] ""  OFFCAR_SKM,OFFCAR_VCU,M2M
 SG_ SKM_FW_version_dev m1 : 5|1@0+ (1,0) [0|1] ""  OFFCAR_SKM,OFFCAR_VCU,M2M
 SG_ SKM_HW_version_patch m2 : 31|8@0+ (1,0) [0|255] ""  OFFCAR_SKM,OFFCAR_VCU,M2M
 SG_ SKM_HW_version_minor m2 : 23|8@0+ (1,0) [0|255] ""  OFFCAR_SKM,OFFCAR_VCU,M2M
 SG_ SKM_HW_version_major m2 : 15|8@0+ (1,0) [0|255] ""  OFFCAR_SKM,OFFCAR_VCU,M2M
 SG_ SKM_FW_version_patch m1 : 31|8@0+ (1,0) [0|255] ""  OFFCAR_SKM,OFFCAR_VCU,M2M
 SG_ SKM_FW_version_minor m1 : 23|8@0+ (1,0) [0|255] ""  OFFCAR_SKM,OFFCAR_VCU,M2M
 SG_ SKM_FW_version_major m1 : 15|8@0+ (1,0) [0|255] ""  OFFCAR_SKM,OFFCAR_VCU,M2M
 SG_ SKM_BL_version_patch m0 : 31|8@0+ (1,0) [0|255] ""  OFFCAR_SKM,OFFCAR_VCU,M2M
 SG_ SKM_BL_version_minor m0 : 23|8@0+ (1,0) [0|255] ""  OFFCAR_SKM,OFFCAR_VCU,M2M
 SG_ SKM_BL_version_major m0 : 15|8@0+ (1,0) [0|255] ""  OFFCAR_SKM,OFFCAR_VCU,M2M
 SG_ SKM_version_serial_number m3 : 15|48@0+ (1,0) [0|281474976710655] ""  OFFCAR_SKM,OFFCAR_VCU,M2M
 SG_ SKM_version_info_MUX M : 7|2@0+ (1,0) [0|3] ""  OFFCAR_SKM,OFFCAR_VCU,M2M

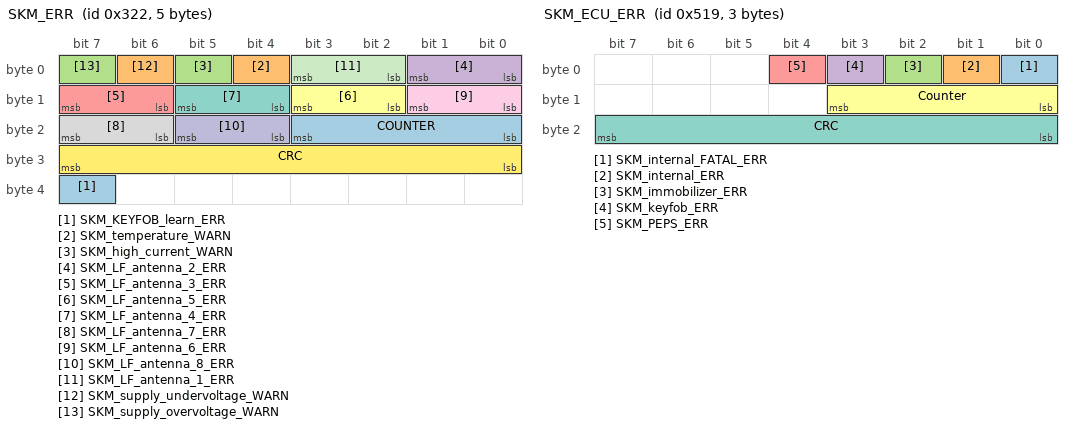
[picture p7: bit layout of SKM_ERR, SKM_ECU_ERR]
BO_ 802 SKM_ERR: 5 SKM
 SG_ SKM_KEYFOB_learn_ERR : 39|1@0+ (1,0) [0|1] ""  OFFCAR_SKM
 SG_ SKM_temperature_WARN : 4|1@0+ (1,0) [0|1] ""  OFFCAR_SKM
 SG_ SKM_high_current_WARN : 5|1@0+ (1,0) [0|1] ""  OFFCAR_SKM
 SG_ SKM_LF_antenna_2_ERR : 1|2@0+ (1,0) [0|2] ""  OFFCAR_SKM
 SG_ SKM_LF_antenna_3_ERR : 15|2@0+ (1,0) [0|2] ""  OFFCAR_SKM
 SG_ SKM_LF_antenna_5_ERR : 11|2@0+ (1,0) [0|2] ""  OFFCAR_SKM
 SG_ SKM_LF_antenna_4_ERR : 13|2@0+ (1,0) [0|2] ""  OFFCAR_SKM
 SG_ SKM_LF_antenna_7_ERR : 23|2@0+ (1,0) [0|2] ""  OFFCAR_SKM
 SG_ SKM_LF_antenna_6_ERR : 9|2@0+ (1,0) [0|2] ""  OFFCAR_SKM
 SG_ SKM_LF_antenna_8_ERR : 21|2@0+ (1,0) [0|2] ""  OFFCAR_SKM
 SG_ SKM_LF_antenna_1_ERR : 3|2@0+ (1,0) [0|2] ""  OFFCAR_SKM
 SG_ CRC : 31|8@0+ (1,0) [0|255] ""  OFFCAR_SKM
 SG_ COUNTER : 19|4@0+ (1,0) [0|15] ""  OFFCAR_SKM
 SG_ SKM_supply_undervoltage_WARN : 6|1@0+ (1,0) [0|1] ""  OFFCAR_SKM
 SG_ SKM_supply_overvoltage_WARN : 7|1@0+ (1,0) [0|1] ""  OFFCAR_SKM

BO_ 1305 SKM_ECU_ERR: 3 SKM
 SG_ SKM_internal_FATAL_ERR : 0|1@0+ (1,0) [0|1] "" VCU,IVI,M2M
 SG_ SKM_internal_ERR : 1|1@0+ (1,0) [0|1] "" VCU,IVI,M2M
 SG_ SKM_immobilizer_ERR : 2|1@0+ (1,0) [0|1] "" VCU,IVI,M2M
 SG_ SKM_keyfob_ERR : 3|1@0+ (1,0) [0|1] "" VCU,IVI,M2M
 SG_ SKM_PEPS_ERR : 4|1@0+ (1,0) [0|1] "" VCU,IVI,M2M
 SG_ Counter : 11|4@0+ (1,0)[0|15] "" VCU,IVI,M2M
 SG_ CRC : 23|8@0+ (1,0)[0|255] "" VCU,IVI,M2M

BO_ 801 SKM_KEYFOB_ST_DBG: 7 SKM
 SG_ SKM_PEPS_active_ST : 46|1@0+ (1,0) [0|1] ""  OFFCAR_SKM
 SG_ SKM_KEYFOB_battery_ST_4 : 36|1@0+ (1,0) [0|1] ""  OFFCAR_SKM
 SG_ SKM_KEYFOB_battery_ST_3 : 37|1@0+ (1,0) [0|1] ""  OFFCAR_SKM
 SG_ SKM_KEYFOB_battery_ST_2 : 38|1@0+ (1,0) [0|1] ""  OFFCAR_SKM
 SG_ SKM_KEYFOB_RKE_ST_4 : 8|5@0+ (1,0) [0|31] ""  OFFCAR_SKM
 SG_ SKM_KEYFOB_RKE_ST_3 : 13|5@0+ (1,0) [0|31] ""  OFFCAR_SKM
 SG_ SKM_KEYFOB_RKE_ST_2 : 2|5@0+ (1,0) [0|31] ""  OFFCAR_SKM
 SG_ SKM_KEYFOB_RKE_ST_1 : 7|5@0+ (1,0) [0|31] ""  OFFCAR_SKM
 SG_ SKM_KEYFOB_PEPS_ST_4 : 26|3@0+ (1,0) [0|7] ""  OFFCAR_SKM
 SG_ SKM_KEYFOB_PEPS_ST_3 : 29|3@0+ (1,0) [0|7] ""  OFFCAR_SKM
 SG_ SKM_KEYFOB_PEPS_ST_2 : 16|3@0+ (1,0) [0|7] ""  OFFCAR_SKM
 SG_ SKM_KEYFOB_PEPS_ST_1 : 19|3@0+ (1,0) [0|7] ""  OFFCAR_SKM
 SG_ SKM_KEYFOB_data_base_ST : 33|3@0+ (1,0) [0|4] ""  OFFCAR_SKM
 SG_ SKM_KEYFOB_battery_ST_1 : 39|1@0+ (1,0) [0|1] ""  OFFCAR_SKM
 SG_ SKM_KEYFOB_IMMO_ST : 35|2@0+ (1,0) [0|3] ""  OFFCAR_SKM
 SG_ CRC : 55|8@0+ (1,0) [0|255] ""  OFFCAR_SKM
 SG_ COUNTER : 43|4@0+ (1,0) [0|15] ""  OFFCAR_SKM

BO_ 1112 DCU_PSG_Bootloader: 8 DCU_PSG
 SG_ DCU_PSG_bootloader : 0|64@1+ (1,0) [0|0] ""  OFFCAR_VCU

BO_ 1113 OFFCAR_DCU_PSG_Bootloader: 8 OFFCAR_VCU
 SG_ OFFCAR_DCU_PSG_bootloader : 0|64@1+ (1,0) [0|0] ""  DCU_PSG

BO_ 1111 OFFCAR_DCU_DRV_Bootloader: 8 OFFCAR_VCU
 SG_ OFFCAR_DCU_DRV_bootloader : 0|64@1+ (1,0) [0|0] ""  DCU_DRV

BO_ 1110 DCU_DRV_Bootloader: 8 DCU_DRV
 SG_ DCU_DRV_bootloader : 0|64@1+ (1,0) [0|0] ""  OFFCAR_VCU

BO_ 1121 OFFCAR_BCU_F_Bootloader: 8 OFFCAR_VCU
 SG_ OFFCAR_BCU_F_bootloader : 0|64@1+ (1,0) [0|0] ""  BCU_F

BO_ 1120 BCU_F_Bootloader: 8 BCU_F
 SG_ BCU_F_bootloader : 0|64@1+ (1,0) [0|0] ""  OFFCAR_VCU

BO_ 1117 OFFCAR_DBCU_Bootloader: 8 OFFCAR_VCU
 SG_ OFFCAR_DBCU_bootloader : 0|64@1+ (1,0) [0|0] ""  DBCU

BO_ 1116 DBCU_Bootloader: 8 DBCU
 SG_ DBCU_bootloader : 0|64@1+ (1,0) [0|0] ""  OFFCAR_VCU

BO_ 1109 OFFCAR_SCU_PSG_Bootloader: 8 OFFCAR_VCU
 SG_ OFFCAR_SCU_PSG_bootloader : 0|64@1+ (1,0) [0|0] ""  SCU_PSG

BO_ 1107 OFFCAR_SCU_DRV_Bootloader: 8 OFFCAR_VCU
 SG_ OFFCAR_SCU_DRV_bootloader : 0|64@1+ (1,0) [0|0] ""  SCU_DRV

BO_ 1108 SCU_PSG_Bootloader: 8 SCU_PSG
 SG_ SCU_PSG_bootloader : 0|64@1+ (1,0) [0|0] ""  OFFCAR_VCU

BO_ 1106 SCU_DRV_Bootloader: 8 SCU_DRV
 SG_ SCU_DRV_bootloader : 0|64@1+ (1,0) [0|0] ""  OFFCAR_VCU

BO_ 1150 SWCU_Bootloader: 8 SWCU
 SG_ SWCU_bootloader : 0|64@1+ (1,0) [0|0] ""  OFFCAR_VCU

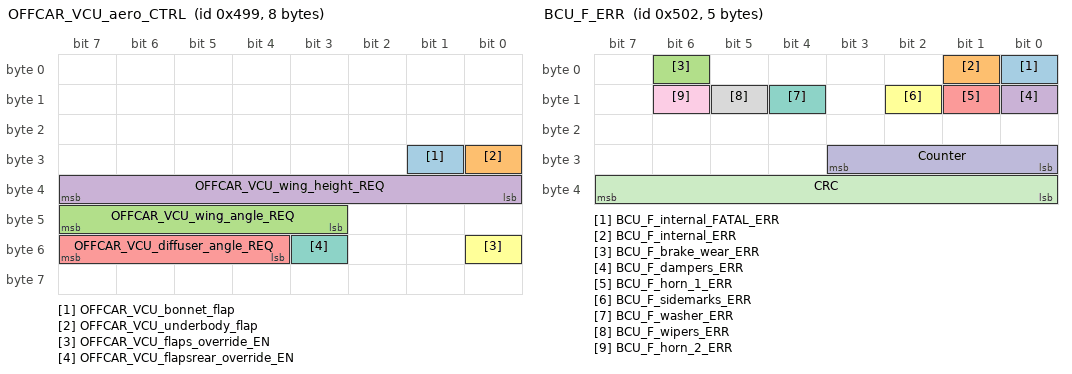
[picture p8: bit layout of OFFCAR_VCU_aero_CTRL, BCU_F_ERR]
BO_ 1177 OFFCAR_VCU_aero_CTRL: 8 OFFCAR_VCU
 SG_ OFFCAR_VCU_bonnet_flap : 25|1@0+ (1,0) [0|0] ""  BCU_F
 SG_ OFFCAR_VCU_underbody_flap : 24|1@0+ (1,0) [0|0] ""  BCU_F
 SG_ OFFCAR_VCU_wing_angle_REQ : 47|5@0- (1,15) [-1|30] "deg"  BCU_R
 SG_ OFFCAR_VCU_wing_height_REQ : 39|8@0- (1,127) [-1|254] "mm"  BCU_R
 SG_ OFFCAR_VCU_diffuser_angle_REQ : 55|4@0- (1,7) [-1|14] "deg"  BCU_R
 SG_ OFFCAR_VCU_flaps_override_EN : 48|1@0+ (1,0) [0|0] ""  BCU_F
 SG_ OFFCAR_VCU_flapsrear_override_EN : 51|1@0+ (1,0) [0|0] ""  BCU_R

BO_ 1151 OFFCAR_SWCU_Bootloader: 8 OFFCAR_VCU
 SG_ OFFCAR_SWCU_bootloader : 0|64@1+ (1,0) [0|0] ""  SWCU

BO_ 1119 OFFCAR_BCU_R_Bootloader: 8 OFFCAR_VCU
 SG_ OFFCAR_BCU_R_bootloader : 0|64@1+ (1,0) [0|0] ""  BCU_R

BO_ 1118 BCU_R_Bootloader: 8 BCU_R
 SG_ BCU_R_bootloader : 0|64@1+ (1,0) [0|0] ""  OFFCAR_VCU

BO_ 1115 OFFCAR_VCU_Bootloader: 8 OFFCAR_VCU
 SG_ OFFCAR_VCU_bootloader : 0|64@1+ (1,0) [0|0] ""  VCU

BO_ 1114 VCU_Bootloader: 8 VCU
 SG_ VCU_bootloader : 0|64@1+ (1,0) [0|0] ""  OFFCAR_VCU

BO_ 1282 BCU_F_ERR: 5 BCU_F
 SG_ BCU_F_internal_FATAL_ERR : 0|1@0+ (1,0) [0|1] ""  VCU,IVI,M2M
 SG_ BCU_F_internal_ERR : 1|1@0+ (1,0) [0|1] ""  VCU,IVI,M2M
 SG_ BCU_F_brake_wear_ERR : 6|1@0+ (1,0) [0|1] ""  VCU,IVI,M2M
 SG_ BCU_F_dampers_ERR : 8|1@0+ (1,0) [0|1] ""  VCU,IVI,M2M
 SG_ BCU_F_horn_1_ERR : 9|1@0+ (1,0) [0|1] ""  VCU,IVI,M2M
 SG_ BCU_F_sidemarks_ERR : 10|1@0+ (1,0) [0|1] ""  VCU,IVI,M2M
 SG_ BCU_F_washer_ERR : 12|1@0+ (1,0) [0|1] ""  VCU,IVI,M2M
 SG_ BCU_F_wipers_ERR : 13|1@0+ (1,0) [0|1] ""  VCU,IVI,M2M
 SG_ BCU_F_horn_2_ERR : 14|1@0+ (1,0) [0|1] ""  VCU,IVI,M2M
 SG_ Counter : 27|4@0+ (1,0) [0|15] ""  VCU,IVI,M2M
 SG_ CRC : 39|8@0+ (1,0) [0|255] ""  VCU,IVI,M2M

BO_ 1293 BCU_R_ERR: 5 BCU_R
 SG_ BCU_R_internal_FATAL_ERR : 0|1@0+ (1,0) [0|1] "" VCU,IVI,M2M
 SG_ BCU_R_internal_ERR : 1|1@0+ (1,0) [0|1] "" VCU,IVI,M2M
 SG_ BCU_R_hydraulic_pump_ERR : 2|1@0+ (1,0) [0|1] "" VCU,IVI,M2M
 SG_ BCU_R_hydraulic_accumulator_ERR : 3|1@0+ (1,0) [0|1] "" VCU,IVI,M2M
 SG_ BCU_R_suspension_ERR : 5|1@0+ (1,0) [0|1] "" VCU,IVI,M2M
 SG_ BCU_R_wing_angle_ERR : 6|1@0+ (1,0) [0|1] "" VCU,IVI,M2M
 SG_ BCU_R_wing_height_ERR : 7|1@0+ (1,0) [0|1] "" VCU,IVI,M2M
 SG_ BCU_R_reverse_light_ERR : 9|1@0+ (1,0) [0|1] "" VCU,IVI,M2M
 SG_ BCU_R_fog_light_ERR : 10|1@0+ (1,0) [0|1] "" VCU,IVI,M2M
 SG_ BCU_R_brakes_wear_ERR : 11|1@0+ (1,0)[0|1] "" VCU,IVI,M2M
 SG_ BCU_R_tailgate_latch_ERR : 12|1@0+ (1,0)[0|1] "" VCU,IVI,M2M
 SG_ BCU_R_sidemarks_ERR : 13|1@0+ (1,0)[0|1] "" VCU,IVI,M2M
 SG_ BCU_R_licenselight_ERR : 15|1@0+ (1,0)[0|1] "" VCU,IVI,M2M
 SG_ BCU_R_brake_light_ERR : 16|1@0+ (1,0)[0|1] "" VCU,IVI,M2M
 SG_ BCU_R_trunk_light_ERR : 17|1@0+ (1,0)[0|1] "" VCU,IVI,M2M
 SG_ BCU_R_ultrasonic_board_ERR : 18|1@0+ (1,0) [0|16] ""  VCU,M2M
 SG_ Counter : 27|4@0+ (1,0)[0|15] "" VCU,IVI,M2M
 SG_ CRC : 39|8@0+ (1,0)[0|255] "" VCU,IVI,M2M

BO_ 768 BODY_IVI_GW_REQ: 8 IVI
 SG_ IVI_charge_soc_LIM_CTRL : 39|7@0+ (1,0) [0|100] "%"  VCU,M2M
 SG_ IVI_stop_resume_charging_REQ : 7|2@0+ (1,0) [0|3] ""  VCU,M2M
 SG_ IVI_charge_current_LIM_CTRL : 31|7@0+ (1,0) [0|32] "A"  VCU,M2M
 SG_ IVI_TPMS_low_pressure_reset_REQ : 41|1@0+ (1,0) [0|0] ""  VCU,M2M
 SG_ IVI_valet_mode_REQ : 42|1@0+ (1,0) [0|1] ""  VCU,DBCU,M2M
 SG_ IVI_AC_recirculation_REQ : 55|2@0+ (1,0) [0|0] ""  VCU,M2M
 SG_ IVI_AC_flow_dir_REQ : 23|7@0+ (1,0) [0|7] ""  VCU,M2M
 SG_ IVI_AC_temp_CTRL : 15|8@0+ (0.5,-40) [-40|62] "C"  VCU,M2M
 SG_ IVI_AC_ON_CTRL : 1|1@0+ (1,0) [0|1] ""  VCU,M2M
 SG_ IVI_AC_fan_speed_REQ : 5|4@0+ (1,0) [0|15] ""  VCU,M2M
 SG_ IVI_AC_max_demist_REQ : 40|1@0+ (1,0) [0|1] ""  VCU,DCU_DRV,DCU_PSG,M2M,DBCU
 SG_ IVI_AC_max_cooling_REQ : 16|1@0+ (1,0) [0|1] ""  VCU,M2M
 SG_ IVI_AC_max_heating_REQ : 24|1@0+ (1,0) [0|1] ""  VCU,M2M
 SG_ IVI_AC_auto_mode_REQ : 32|1@0+ (1,0) [0|1] ""  VCU,M2M
 SG_ IVI_precooling_REQ : 47|1@0+ (1,0) [0|1] ""  VCU,M2M
 SG_ IVI_preheating_REQ : 46|1@0+ (1,0) [0|1] ""  VCU,M2M
 SG_ Counter : 51|4@0+ (1,0) [0|15] ""  VCU
 SG_ CRC : 63|8@0+ (1,0) [0|255] ""  VCU

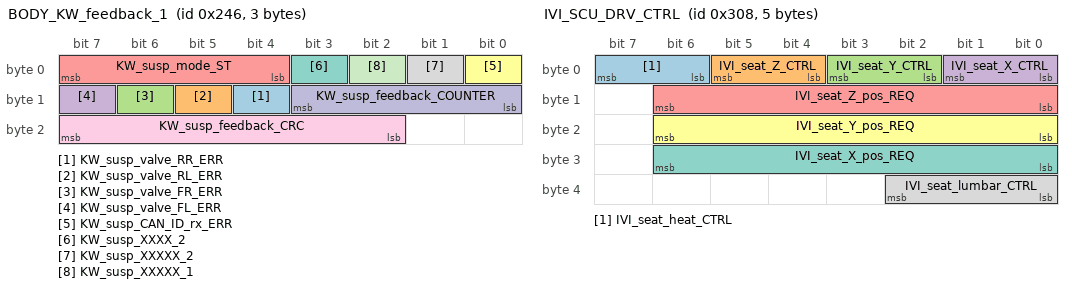
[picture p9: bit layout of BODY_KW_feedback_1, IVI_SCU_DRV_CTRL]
BO_ 582 BODY_KW_feedback_1: 3 KW
 SG_ KW_susp_valve_RR_ERR : 12|1@0+ (1,0) [0|1] ""  VCU,M2M
 SG_ KW_susp_valve_RL_ERR : 13|1@0+ (1,0) [0|1] ""  VCU,M2M
 SG_ KW_susp_valve_FR_ERR : 14|1@0+ (1,0) [0|1] ""  VCU,M2M
 SG_ KW_susp_valve_FL_ERR : 15|1@0+ (1,0) [0|1] ""  VCU,M2M
 SG_ KW_susp_mode_ST : 7|4@0+ (1,0) [0|5] ""  VCU,M2M
 SG_ KW_susp_CAN_ID_rx_ERR : 0|1@0+ (1,0) [0|1] ""  VCU,M2M
 SG_ KW_susp_XXXX_2 : 3|1@0+ (1,0) [0|1] ""  VCU,M2M
 SG_ KW_susp_XXXXX_2 : 1|1@0+ (1,0) [0|1] ""  VCU,M2M
 SG_ KW_susp_feedback_CRC : 23|6@0+ (1,0) [0|255] ""  VCU,M2M
 SG_ KW_susp_feedback_COUNTER : 11|4@0+ (1,0) [0|15] ""  VCU,M2M
 SG_ KW_susp_XXXXX_1 : 2|1@0+ (1,0) [0|1] ""  VCU,M2M

BO_ 583 KW_feedback_2: 4 KW
 SG_ KW_susp_current_demand_rr : 21|6@0+ (0.03,0) [0|1.875] "A"  VCU,M2M
 SG_ KW_susp_current_demand_rl : 29|6@0+ (0.03,0) [0|1.875] "A"  VCU,M2M
 SG_ KW_susp_current_demand_fr : 5|6@0+ (0.03,0) [0|1.875] "A"  VCU,M2M
 SG_ KW_susp_current_demand_fl : 13|6@0+ (0.03,0) [0|1.875] "A"  VCU,M2M

BO_ 1045 VCU_version_info: 8 VCU
 SG_ VCU_FW_commit_hash m1 : 39|32@0+ (1,0) [0|0] ""  OFFCAR_VCU,M2M
 SG_ VCU_BL_commit_hash m0 : 39|32@0+ (1,0) [0|0] ""  OFFCAR_VCU,M2M
 SG_ VCU_version_dbc m3 : 63|8@0+ (1,0) [0|255] ""  OFFCAR_VCU,M2M
 SG_ VCU_BL_version_dev m0 : 5|1@0+ (1,0) [0|1] ""  OFFCAR_VCU,M2M
 SG_ VCU_FW_version_dev m1 : 5|1@0+ (1,0) [0|1] ""  OFFCAR_VCU,M2M
 SG_ VCU_HW_version_patch m2 : 31|8@0+ (1,0) [0|16777215] ""  OFFCAR_VCU,M2M
 SG_ VCU_HW_version_minor m2 : 23|8@0+ (1,0) [0|16777215] ""  OFFCAR_VCU,M2M
 SG_ VCU_HW_version_major m2 : 15|8@0+ (1,0) [0|16777215] ""  OFFCAR_VCU,M2M
 SG_ VCU_FW_version_patch m1 : 31|8@0+ (1,0) [0|16777215] ""  OFFCAR_VCU,M2M
 SG_ VCU_FW_version_minor m1 : 23|8@0+ (1,0) [0|16777215] ""  OFFCAR_VCU,M2M
 SG_ VCU_FW_version_major m1 : 15|8@0+ (1,0) [0|16777215] ""  OFFCAR_VCU,M2M
 SG_ VCU_BL_version_patch m0 : 31|8@0+ (1,0) [0|16777215] ""  OFFCAR_VCU,M2M
 SG_ VCU_BL_version_minor m0 : 23|8@0+ (1,0) [0|16777215] ""  OFFCAR_VCU,M2M
 SG_ VCU_BL_version_major m0 : 15|8@0+ (1,0) [0|16777215] ""  OFFCAR_VCU,M2M
 SG_ VCU_version_serial_number m3 : 15|48@0+ (1,0) [0|65535] ""  OFFCAR_VCU,M2M
 SG_ VCU_version_info_MUX M : 7|2@0+ (1,0) [0|3] ""  OFFCAR_VCU,M2M

BO_ 1032 BCU_F_version_info: 8 BCU_F
 SG_ BCU_F_FW_commit_hash m1 : 39|32@0+ (1,0) [0|0] ""  OFFCAR_VCU,M2M
 SG_ BCU_F_BL_commit_hash m0 : 39|32@0+ (1,0) [0|0] ""  OFFCAR_VCU,M2M
 SG_ BCU_F_version_dbc m3 : 63|8@0+ (1,0) [0|255] ""  OFFCAR_VCU,M2M
 SG_ BCU_F_BL_version_dev m0 : 5|1@0+ (1,0) [0|1] ""  OFFCAR_VCU,M2M
 SG_ BCU_F_FW_version_dev m1 : 5|1@0+ (1,0) [0|1] ""  OFFCAR_VCU,M2M
 SG_ BCU_F_HW_version_patch m2 : 31|8@0+ (1,0) [0|16777215] ""  OFFCAR_VCU,M2M
 SG_ BCU_F_HW_version_minor m2 : 23|8@0+ (1,0) [0|16777215] ""  OFFCAR_VCU,M2M
 SG_ BCU_F_HW_version_major m2 : 15|8@0+ (1,0) [0|16777215] ""  OFFCAR_VCU,M2M
 SG_ BCU_F_FW_version_patch m1 : 31|8@0+ (1,0) [0|16777215] ""  OFFCAR_VCU,M2M
 SG_ BCU_F_FW_version_minor m1 : 23|8@0+ (1,0) [0|16777215] ""  OFFCAR_VCU,M2M
 SG_ BCU_F_FW_version_major m1 : 15|8@0+ (1,0) [0|16777215] ""  OFFCAR_VCU,M2M
 SG_ BCU_F_BL_version_patch m0 : 31|8@0+ (1,0) [0|16777215] ""  OFFCAR_VCU,M2M
 SG_ BCU_F_BL_version_minor m0 : 23|8@0+ (1,0) [0|16777215] ""  OFFCAR_VCU,M2M
 SG_ BCU_F_BL_version_major m0 : 15|8@0+ (1,0) [0|16777215] ""  OFFCAR_VCU,M2M
 SG_ BCU_F_version_serial_number m3 : 15|48@0+ (1,0) [0|65535] ""  OFFCAR_VCU,M2M
 SG_ BCU_F_version_info_MUX M : 7|2@0+ (1,0) [0|3] ""  OFFCAR_VCU,M2M

BO_ 1033 BCU_R_version_info: 8 BCU_R
 SG_ BCU_R_FW_commit_hash m1 : 39|32@0+ (1,0) [0|0] ""  OFFCAR_VCU,M2M
 SG_ BCU_R_BL_commit_hash m0 : 39|32@0+ (1,0) [0|0] ""  OFFCAR_VCU,M2M
 SG_ BCU_R_version_dbc m3 : 63|8@0+ (1,0) [0|255] ""  OFFCAR_VCU,M2M
 SG_ BCU_R_BL_version_dev m0 : 5|1@0+ (1,0) [0|1] ""  OFFCAR_VCU,M2M
 SG_ BCU_R_FW_version_dev m1 : 5|1@0+ (1,0) [0|1] ""  OFFCAR_VCU,M2M
 SG_ BCU_R_HW_version_patch m2 : 31|8@0+ (1,0) [0|16777215] ""  OFFCAR_VCU,M2M
 SG_ BCU_R_HW_version_minor m2 : 23|8@0+ (1,0) [0|16777215] ""  OFFCAR_VCU,M2M
 SG_ BCU_R_HW_version_major m2 : 15|8@0+ (1,0) [0|16777215] ""  OFFCAR_VCU,M2M
 SG_ BCU_R_FW_version_patch m1 : 31|8@0+ (1,0) [0|16777215] ""  OFFCAR_VCU,M2M
 SG_ BCU_R_FW_version_minor m1 : 23|8@0+ (1,0) [0|16777215] ""  OFFCAR_VCU,M2M
 SG_ BCU_R_FW_version_major m1 : 15|8@0+ (1,0) [0|16777215] ""  OFFCAR_VCU,M2M
 SG_ BCU_R_BL_version_patch m0 : 31|8@0+ (1,0) [0|16777215] ""  OFFCAR_VCU,M2M
 SG_ BCU_R_BL_version_minor m0 : 23|8@0+ (1,0) [0|16777215] ""  OFFCAR_VCU,M2M
 SG_ BCU_R_BL_version_major m0 : 15|8@0+ (1,0) [0|16777215] ""  OFFCAR_VCU,M2M
 SG_ BCU_R_version_serial_number m3 : 15|48@0+ (1,0) [0|65535] ""  OFFCAR_VCU,M2M
 SG_ BCU_R_version_info_MUX M : 7|2@0+ (1,0) [0|3] ""  OFFCAR_VCU,M2M

BO_ 1047 IVI_version_info: 8 IVI
 SG_ IVI_version_dbc m3 : 63|8@0+ (1,0) [0|0] ""  OFFCAR_VCU,M2M
 SG_ IVI_version_serial_number m3 : 15|48@0+ (1,0) [0|0] ""  OFFCAR_VCU,M2M
 SG_ IVI_HW_version_patch m2 : 31|8@0+ (1,0) [0|0] ""  OFFCAR_VCU,M2M
 SG_ IVI_HW_version_minor m2 : 23|8@0+ (1,0) [0|0] ""  OFFCAR_VCU,M2M
 SG_ IVI_HW_version_major m2 : 15|8@0+ (1,0) [0|0] ""  OFFCAR_VCU,M2M
 SG_ IVI_FW_commit_hash m1 : 39|32@0+ (1,0) [0|0] ""  OFFCAR_VCU,M2M
 SG_ IVI_FW_version_patch m1 : 31|8@0+ (1,0) [0|0] ""  OFFCAR_VCU,M2M
 SG_ IVI_FW_version_minor m1 : 23|8@0+ (1,0) [0|0] ""  OFFCAR_VCU,M2M
 SG_ IVI_FW_version_major m1 : 15|8@0+ (1,0) [0|0] ""  OFFCAR_VCU,M2M
 SG_ IVI_FW_version_dev m1 : 5|1@0+ (1,0) [0|0] ""  OFFCAR_VCU,M2M
 SG_ IVI_BL_commit_hash m0 : 39|32@0+ (1,0) [0|0] ""  OFFCAR_VCU,M2M
 SG_ IVI_BL_version_patch m0 : 31|8@0+ (1,0) [0|0] ""  OFFCAR_VCU,M2M
 SG_ IVI_BL_version_minor m0 : 23|8@0+ (1,0) [0|0] ""  OFFCAR_VCU,M2M
 SG_ IVI_BL_version_major m0 : 15|8@0+ (1,0) [0|0] ""  OFFCAR_VCU,M2M
 SG_ IVI_BL_version_dev m0 : 5|1@0+ (1,0) [0|0] ""  OFFCAR_VCU,M2M
 SG_ IVI_version_info_MUX M : 7|2@0+ (1,0) [0|0] ""  OFFCAR_VCU,M2M

BO_ 1042 SWCU_version_info: 8 SWCU
 SG_ SWCU_version_dbc m3 : 63|8@0+ (1,0) [0|0] ""  OFFCAR_VCU,M2M
 SG_ SWCU_version_serial_number m3 : 15|48@0+ (1,0) [0|0] ""  OFFCAR_VCU,M2M
 SG_ SWCU_HW_version_patch m2 : 31|8@0+ (1,0) [0|0] ""  OFFCAR_VCU,M2M
 SG_ SWCU_HW_version_minor m2 : 23|8@0+ (1,0) [0|0] ""  OFFCAR_VCU,M2M
 SG_ SWCU_HW_version_major m2 : 15|8@0+ (1,0) [0|0] ""  OFFCAR_VCU,M2M
 SG_ SWCU_FW_commit_hash m1 : 39|32@0+ (1,0) [0|0] ""  OFFCAR_VCU,M2M
 SG_ SWCU_FW_version_patch m1 : 31|8@0+ (1,0) [0|0] ""  OFFCAR_VCU,M2M
 SG_ SWCU_FW_version_minor m1 : 23|8@0+ (1,0) [0|0] ""  OFFCAR_VCU,M2M
 SG_ SWCU_FW_version_major m1 : 15|8@0+ (1,0) [0|0] ""  OFFCAR_VCU,M2M
 SG_ SWCU_FW_version_dev m1 : 5|1@0+ (1,0) [0|0] ""  OFFCAR_VCU,M2M
 SG_ SWCU_BL_commit_hash m0 : 39|32@0+ (1,0) [0|0] ""  OFFCAR_VCU,M2M
 SG_ SWCU_BL_version_patch m0 : 31|8@0+ (1,0) [0|0] ""  OFFCAR_VCU,M2M
 SG_ SWCU_BL_version_minor m0 : 23|8@0+ (1,0) [0|0] ""  OFFCAR_VCU,M2M
 SG_ SWCU_BL_version_major m0 : 15|8@0+ (1,0) [0|0] ""  OFFCAR_VCU,M2M
 SG_ SWCU_BL_version_dev m0 : 5|1@0+ (1,0) [0|0] ""  OFFCAR_VCU,M2M
 SG_ SWCU_version_info_MUX M : 7|2@0+ (1,0) [0|0] ""  OFFCAR_VCU,M2M

BO_ 1036 DBCU_version_info: 8 DBCU
 SG_ DBCU_FW_commit_hash m1 : 39|32@0+ (1,0) [0|0] ""  OFFCAR_VCU,M2M
 SG_ DBCU_BL_commit_hash m0 : 39|32@0+ (1,0) [0|0] ""  OFFCAR_VCU,M2M
 SG_ DBCU_version_dbc m3 : 63|8@0+ (1,0) [0|255] ""  OFFCAR_VCU,M2M
 SG_ DBCU_BL_version_dev m0 : 5|1@0+ (1,0) [0|1] ""  OFFCAR_VCU,M2M
 SG_ DBCU_FW_version_dev m1 : 5|1@0+ (1,0) [0|1] ""  OFFCAR_VCU,M2M
 SG_ DBCU_HW_version_patch m2 : 31|8@0+ (1,0) [0|16777215] ""  OFFCAR_VCU,M2M
 SG_ DBCU_HW_version_minor m2 : 23|8@0+ (1,0) [0|16777215] ""  OFFCAR_VCU,M2M
 SG_ DBCU_HW_version_major m2 : 15|8@0+ (1,0) [0|16777215] ""  OFFCAR_VCU,M2M
 SG_ DBCU_FW_version_patch m1 : 31|8@0+ (1,0) [0|16777215] ""  OFFCAR_VCU,M2M
 SG_ DBCU_FW_version_minor m1 : 23|8@0+ (1,0) [0|16777215] ""  OFFCAR_VCU,M2M
 SG_ DBCU_FW_version_major m1 : 15|8@0+ (1,0) [0|16777215] ""  OFFCAR_VCU,M2M
 SG_ DBCU_BL_version_patch m0 : 31|8@0+ (1,0) [0|16777215] ""  OFFCAR_VCU,M2M
 SG_ DBCU_BL_version_minor m0 : 23|8@0+ (1,0) [0|16777215] ""  OFFCAR_VCU,M2M
 SG_ DBCU_BL_version_major m0 : 15|8@0+ (1,0) [0|16777215] ""  OFFCAR_VCU,M2M
 SG_ DBCU_version_serial_number m3 : 15|48@0+ (1,0) [0|65535] ""  OFFCAR_VCU,M2M
 SG_ DBCU_version_info_MUX M : 7|2@0+ (1,0) [0|3] ""  OFFCAR_VCU,M2M

BO_ 1025 SCU_PSG_version_info: 8 SCU_PSG
 SG_ SCU_PSG_FW_commit_hash m1 : 39|32@0+ (1,0) [0|0] ""  OFFCAR_VCU,M2M
 SG_ SCU_PSG_BL_commit_hash m0 : 39|32@0+ (1,0) [0|0] ""  OFFCAR_VCU,M2M
 SG_ SCU_PSG_version_dbc m3 : 63|8@0+ (1,0) [0|255] ""  OFFCAR_VCU,M2M
 SG_ SCU_PSG_BL_version_dev m0 : 5|1@0+ (1,0) [0|1] ""  OFFCAR_VCU,M2M
 SG_ SCU_PSG_FW_version_dev m1 : 5|1@0+ (1,0) [0|1] ""  OFFCAR_VCU,M2M
 SG_ SCU_PSG_HW_version_patch m2 : 31|8@0+ (1,0) [0|16777215] ""  OFFCAR_VCU,M2M
 SG_ SCU_PSG_HW_version_minor m2 : 23|8@0+ (1,0) [0|16777215] ""  OFFCAR_VCU,M2M
 SG_ SCU_PSG_HW_version_major m2 : 15|8@0+ (1,0) [0|16777215] ""  OFFCAR_VCU,M2M
 SG_ SCU_PSG_FW_version_patch m1 : 31|8@0+ (1,0) [0|16777215] ""  OFFCAR_VCU,M2M
 SG_ SCU_PSG_FW_version_minor m1 : 23|8@0+ (1,0) [0|16777215] ""  OFFCAR_VCU,M2M
 SG_ SCU_PSG_FW_version_major m1 : 15|8@0+ (1,0) [0|16777215] ""  OFFCAR_VCU,M2M
 SG_ SCU_PSG_BL_version_patch m0 : 31|8@0+ (1,0) [0|16777215] ""  OFFCAR_VCU,M2M
 SG_ SCU_PSG_BL_version_minor m0 : 23|8@0+ (1,0) [0|16777215] ""  OFFCAR_VCU,M2M
 SG_ SCU_PSG_BL_version_major m0 : 15|8@0+ (1,0) [0|16777215] ""  OFFCAR_VCU,M2M
 SG_ SCU_PSG_version_serial_number m3 : 15|48@0+ (1,0) [0|65535] ""  OFFCAR_VCU,M2M
 SG_ SCU_PSG_version_info_MUX M : 7|2@0+ (1,0) [0|3] ""  OFFCAR_VCU,M2M

BO_ 1023 SCU_DRV_version_info: 8 SCU_DRV
 SG_ SCU_DRV_FW_commit_hash m1 : 39|32@0+ (1,0) [0|0] ""  OFFCAR_VCU,M2M
 SG_ SCU_DRV_BL_commit_hash m0 : 39|32@0+ (1,0) [0|0] ""  OFFCAR_VCU,M2M
 SG_ SCU_DRV_version_dbc m3 : 63|8@0+ (1,0) [0|255] ""  OFFCAR_VCU,M2M
 SG_ SCU_DRV_BL_version_dev m0 : 5|1@0+ (1,0) [0|1] ""  OFFCAR_VCU,M2M
 SG_ SCU_DRV_FW_version_dev m1 : 5|1@0+ (1,0) [0|1] ""  OFFCAR_VCU,M2M
 SG_ SCU_DRV_HW_version_patch m2 : 31|8@0+ (1,0) [0|16777215] ""  OFFCAR_VCU,M2M
 SG_ SCU_DRV_HW_version_minor m2 : 23|8@0+ (1,0) [0|16777215] ""  OFFCAR_VCU,M2M
 SG_ SCU_DRV_HW_version_major m2 : 15|8@0+ (1,0) [0|16777215] ""  OFFCAR_VCU,M2M
 SG_ SCU_DRV_FW_version_patch m1 : 31|8@0+ (1,0) [0|16777215] ""  OFFCAR_VCU,M2M
 SG_ SCU_DRV_FW_version_minor m1 : 23|8@0+ (1,0) [0|16777215] ""  OFFCAR_VCU,M2M
 SG_ SCU_DRV_FW_version_major m1 : 15|8@0+ (1,0) [0|16777215] ""  OFFCAR_VCU,M2M
 SG_ SCU_DRV_BL_version_patch m0 : 31|8@0+ (1,0) [0|16777215] ""  OFFCAR_VCU,M2M
 SG_ SCU_DRV_BL_version_minor m0 : 23|8@0+ (1,0) [0|16777215] ""  OFFCAR_VCU,M2M
 SG_ SCU_DRV_BL_version_major m0 : 15|8@0+ (1,0) [0|16777215] ""  OFFCAR_VCU,M2M
 SG_ SCU_DRV_version_serial_number m3 : 15|48@0+ (1,0) [0|65535] ""  OFFCAR_VCU,M2M
 SG_ SCU_DRV_version_info_MUX M : 7|2@0+ (1,0) [0|3] ""  OFFCAR_VCU,M2M

BO_ 1038 DCU_PSG_version_info: 8 DCU_PSG
 SG_ DCU_PSG_FW_commit_hash m1 : 39|32@0+ (1,0) [0|0] ""  OFFCAR_VCU,M2M
 SG_ DCU_PSG_BL_commit_hash m0 : 39|32@0+ (1,0) [0|0] ""  OFFCAR_VCU,M2M
 SG_ DCU_PSG_version_dbc m3 : 63|8@0+ (1,0) [0|255] ""  OFFCAR_VCU,M2M
 SG_ DCU_PSG_BL_version_dev m0 : 5|1@0+ (1,0) [0|1] ""  OFFCAR_VCU,M2M
 SG_ DCU_PSG_FW_version_dev m1 : 5|1@0+ (1,0) [0|1] ""  OFFCAR_VCU,M2M
 SG_ DCU_PSG_HW_version_patch m2 : 31|8@0+ (1,0) [0|16777215] ""  OFFCAR_VCU,M2M
 SG_ DCU_PSG_HW_version_minor m2 : 23|8@0+ (1,0) [0|16777215] ""  OFFCAR_VCU,M2M
 SG_ DCU_PSG_HW_version_major m2 : 15|8@0+ (1,0) [0|16777215] ""  OFFCAR_VCU,M2M
 SG_ DCU_PSG_FW_version_patch m1 : 31|8@0+ (1,0) [0|16777215] ""  OFFCAR_VCU,M2M
 SG_ DCU_PSG_FW_version_minor m1 : 23|8@0+ (1,0) [0|16777215] ""  OFFCAR_VCU,M2M
 SG_ DCU_PSG_FW_version_major m1 : 15|8@0+ (1,0) [0|16777215] ""  OFFCAR_VCU,M2M
 SG_ DCU_PSG_BL_version_patch m0 : 31|8@0+ (1,0) [0|16777215] ""  OFFCAR_VCU,M2M
 SG_ DCU_PSG_BL_version_minor m0 : 23|8@0+ (1,0) [0|16777215] ""  OFFCAR_VCU,M2M
 SG_ DCU_PSG_BL_version_major m0 : 15|8@0+ (1,0) [0|16777215] ""  OFFCAR_VCU,M2M
 SG_ DCU_PSG_version_serial_number m3 : 15|48@0+ (1,0) [0|65535] ""  OFFCAR_VCU,M2M
 SG_ DCU_PSG_version_info_MUX M : 7|2@0+ (1,0) [0|3] ""  OFFCAR_VCU,M2M

BO_ 1037 DCU_DRV_version_info: 8 DCU_DRV
 SG_ DCU_DRV_FW_commit_hash m1 : 39|32@0+ (1,0) [0|0] ""  OFFCAR_VCU,M2M
 SG_ DCU_DRV_BL_commit_hash m0 : 39|32@0+ (1,0) [0|0] ""  OFFCAR_VCU,M2M
 SG_ DCU_DRV_version_dbc m3 : 63|8@0+ (1,0) [0|255] ""  OFFCAR_VCU,M2M
 SG_ DCU_DRV_BL_version_dev m0 : 5|1@0+ (1,0) [0|1] ""  OFFCAR_VCU,M2M
 SG_ DCU_DRV_FW_version_dev m1 : 5|1@0+ (1,0) [0|1] ""  OFFCAR_VCU,M2M
 SG_ DCU_DRV_HW_version_patch m2 : 31|8@0+ (1,0) [0|16777215] ""  OFFCAR_VCU,M2M
 SG_ DCU_DRV_HW_version_minor m2 : 23|8@0+ (1,0) [0|16777215] ""  OFFCAR_VCU,M2M
 SG_ DCU_DRV_HW_version_major m2 : 15|8@0+ (1,0) [0|16777215] ""  OFFCAR_VCU,M2M
 SG_ DCU_DRV_FW_version_patch m1 : 31|8@0+ (1,0) [0|16777215] ""  OFFCAR_VCU,M2M
 SG_ DCU_DRV_FW_version_minor m1 : 23|8@0+ (1,0) [0|16777215] ""  OFFCAR_VCU,M2M
 SG_ DCU_DRV_FW_version_major m1 : 15|8@0+ (1,0) [0|16777215] ""  OFFCAR_VCU,M2M
 SG_ DCU_DRV_BL_version_patch m0 : 31|8@0+ (1,0) [0|16777215] ""  OFFCAR_VCU,M2M
 SG_ DCU_DRV_BL_version_minor m0 : 23|8@0+ (1,0) [0|16777215] ""  OFFCAR_VCU,M2M
 SG_ DCU_DRV_BL_version_major m0 : 15|8@0+ (1,0) [0|16777215] ""  OFFCAR_VCU,M2M
 SG_ DCU_DRV_version_serial_number m3 : 15|48@0+ (1,0) [0|65535] ""  OFFCAR_VCU,M2M
 SG_ DCU_DRV_version_info_MUX M : 7|2@0+ (1,0) [0|3] ""  OFFCAR_VCU,M2M

BO_ 776 IVI_SCU_DRV_CTRL: 5 IVI
 SG_ IVI_seat_heat_CTRL : 7|2@0+ (1,0) [0|0] ""  SCU_DRV,M2M
 SG_ IVI_seat_Z_CTRL : 5|2@0+ (1,0) [0|3] ""  SCU_DRV,M2M
 SG_ IVI_seat_Y_CTRL : 3|2@0+ (1,0) [0|3] ""  SCU_DRV,M2M
 SG_ IVI_seat_X_CTRL : 1|2@0+ (1,0) [0|3] ""  SCU_DRV,M2M
 SG_ IVI_seat_Z_pos_REQ : 14|7@0+ (1,0) [0|127] "%"  SCU_DRV,M2M
 SG_ IVI_seat_Y_pos_REQ : 22|7@0+ (1,0) [0|127] "%"  SCU_DRV,M2M
 SG_ IVI_seat_X_pos_REQ : 30|7@0+ (1,0) [0|127] "%"  SCU_DRV,M2M
 SG_ IVI_seat_lumbar_CTRL : 34|3@0+ (1,0) [0|4] ""  SCU_DRV,M2M

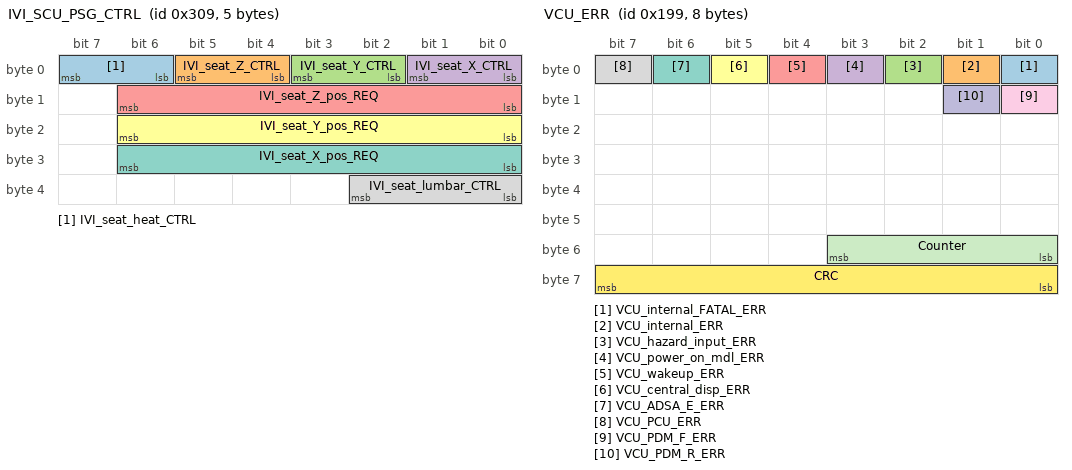
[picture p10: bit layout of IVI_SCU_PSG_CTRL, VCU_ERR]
BO_ 777 IVI_SCU_PSG_CTRL: 5 IVI
 SG_ IVI_seat_heat_CTRL : 7|2@0+ (1,0) [0|0] ""  SCU_PSG,M2M
 SG_ IVI_seat_Z_CTRL : 5|2@0+ (1,0) [0|3] ""  SCU_PSG,M2M
 SG_ IVI_seat_Y_CTRL : 3|2@0+ (1,0) [0|3] ""  SCU_PSG,M2M
 SG_ IVI_seat_X_CTRL : 1|2@0+ (1,0) [0|3] ""  SCU_PSG,M2M
 SG_ IVI_seat_Z_pos_REQ : 14|7@0+ (1,0) [0|127] "%"  SCU_PSG,M2M
 SG_ IVI_seat_Y_pos_REQ : 22|7@0+ (1,0) [0|127] "%"  SCU_PSG,M2M
 SG_ IVI_seat_X_pos_REQ : 30|7@0+ (1,0) [0|127] "%"  SCU_PSG,M2M
 SG_ IVI_seat_lumbar_CTRL : 34|3@0+ (1,0) [0|4] ""  SCU_PSG,M2M

BO_ 409 VCU_ERR: 8 VCU
 SG_ VCU_internal_FATAL_ERR : 0|1@0+ (1,0) [0|1] "" IVI,M2M
 SG_ VCU_internal_ERR : 1|1@0+ (1,0) [0|1] "" IVI,M2M
 SG_ VCU_hazard_input_ERR : 2|1@0+ (1,0) [0|1] "" IVI,M2M
 SG_ VCU_power_on_mdl_ERR : 3|1@0+ (1,0) [0|1] "" IVI,M2M
 SG_ VCU_wakeup_ERR : 4|1@0+ (1,0) [0|1] "" IVI,M2M
 SG_ VCU_central_disp_ERR : 5|1@0+ (1,0) [0|1] "" IVI,M2M
 SG_ VCU_ADSA_E_ERR : 6|1@0+ (1,0) [0|1] "" IVI,M2M
 SG_ VCU_PCU_ERR : 7|1@0+ (1,0) [0|1] "" IVI,M2M
 SG_ VCU_PDM_F_ERR : 8|1@0+ (1,0) [0|1] "" IVI,M2M
 SG_ VCU_PDM_R_ERR : 9|1@0+ (1,0) [0|1] "" IVI,M2M
 SG_ Counter : 51|4@0+ (1,0)[0|15] "" IVI,M2M
 SG_ CRC : 63|8@0+ (1,0)[0|255] "" IVI,M2M

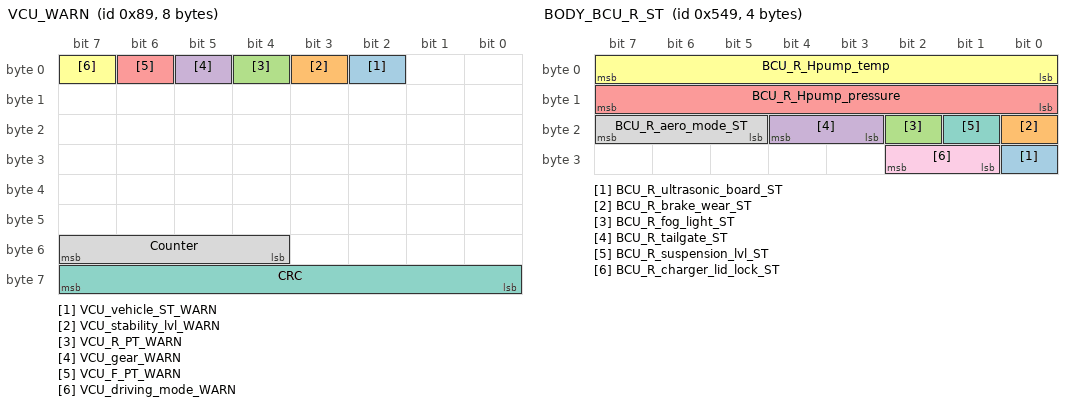
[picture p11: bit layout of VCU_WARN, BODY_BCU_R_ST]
BO_ 137 VCU_WARN: 8 VCU
 SG_ VCU_vehicle_ST_WARN : 2|1@0+ (1,0) [0|1] ""  IVI,M2M
 SG_ VCU_stability_lvl_WARN : 3|1@0+ (1,0) [0|1] ""  IVI,M2M
 SG_ VCU_R_PT_WARN : 4|1@0+ (1,0) [0|1] ""  IVI,M2M
 SG_ VCU_gear_WARN : 5|1@0+ (1,0) [0|1] ""  IVI,M2M
 SG_ VCU_F_PT_WARN : 6|1@0+ (1,0) [0|1] ""  IVI,M2M
 SG_ VCU_driving_mode_WARN : 7|1@0+ (1,0) [0|0] ""  IVI,M2M
 SG_ CRC : 63|8@0+ (1,0) [0|255] ""  IVI
 SG_ Counter : 55|4@0+ (1,0) [0|15] ""  IVI

BO_ 140 VCU_feedback_2: 8 VCU
 SG_ VCU_parking_brake_applied : 5|2@0+ (1,0) [0|3] ""  IVI,M2M
 SG_ VCU_activate_brakes : 7|2@0+ (1,0) [0|1] ""  BCU_R,BCU_F,M2M
 SG_ CRC : 63|8@0+ (1,0) [0|255] ""  IVI
 SG_ Counter : 51|4@0+ (1,0) [0|15] ""  IVI

BO_ 1353 BODY_BCU_R_ST: 4 BCU_R
 SG_ BCU_R_ultrasonic_board_ST : 24|1@0+ (1,0) [0|1] ""  M2M
 SG_ BCU_R_brake_wear_ST : 16|1@0+ (1,0) [0|1] "" IVI,M2M
 SG_ BCU_R_fog_light_ST : 18|1@0+ (1,0) [0|1] "" IVI,SSCU,M2M
 SG_ BCU_R_tailgate_ST : 20|2@0+ (1,0) [0|3] "" IVI,M2M
 SG_ BCU_R_Hpump_pressure : 15|8@0+ (1,0) [0|255] "bar" M2M
 SG_ BCU_R_Hpump_temp : 7|8@0+ (1,-40) [-40|125] "degC" M2M
 SG_ BCU_R_suspension_lvl_ST : 17|1@0+ (1,1) [0|1] "" VCU,IVI,M2M
 SG_ BCU_R_aero_mode_ST : 23|3@0+ (1,0) [0|7] "enum" VCU,M2M
 SG_ BCU_R_charger_lid_lock_ST : 26|2@0+ (1,0) [0|1] "enum" IVI,M2M

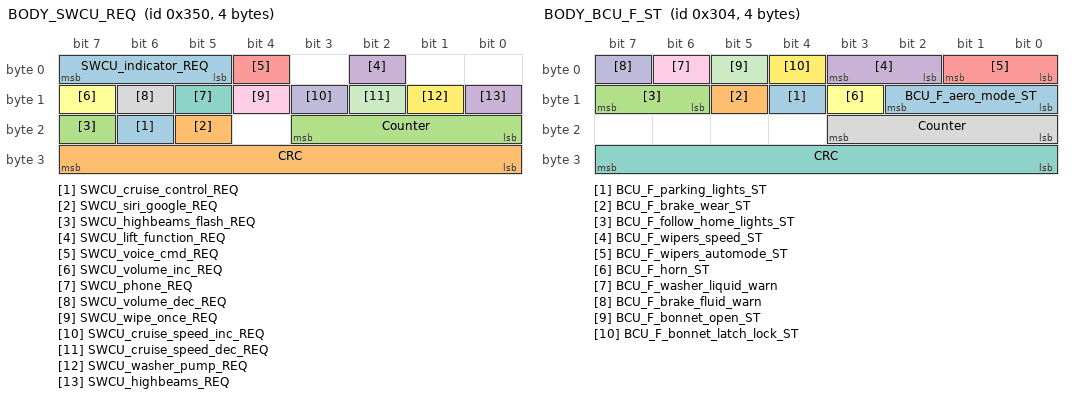
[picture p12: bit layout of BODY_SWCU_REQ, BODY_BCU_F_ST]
BO_ 848 BODY_SWCU_REQ: 4 SWCU
 SG_ SWCU_cruise_control_REQ : 22|1@0+ (1,0) [0|1] ""  VCU,IVI,M2M
 SG_ SWCU_siri_google_REQ : 21|1@0+ (1,0) [0|1] ""  IVI,VCU,M2M
 SG_ SWCU_highbeams_flash_REQ : 23|1@0+ (1,0) [0|1] ""  BCU_F,M2M,VCU,IVI
 SG_ SWCU_lift_function_REQ : 2|1@0+ (1,0) [0|1] ""  BCU_R,VCU,IVI,M2M
 SG_ SWCU_voice_cmd_REQ : 4|1@0+ (1,0) [0|1] ""  VCU,M2M
 SG_ SWCU_volume_inc_REQ : 15|1@0+ (1,0) [0|1] ""  IVI,M2M,VCU
 SG_ SWCU_phone_REQ : 13|1@0+ (1,0) [0|1] ""  IVI,M2M,VCU
 SG_ SWCU_volume_dec_REQ : 14|1@0+ (1,0) [0|1] ""  IVI,M2M,VCU
 SG_ SWCU_wipe_once_REQ : 12|1@0+ (1,0) [0|1] ""  BCU_F,VCU,M2M
 SG_ SWCU_cruise_speed_inc_REQ : 11|1@0+ (1,0) [0|1] ""  VCU,IVI,M2M
 SG_ SWCU_cruise_speed_dec_REQ : 10|1@0+ (1,0) [0|1] ""  VCU,IVI,M2M
 SG_ SWCU_washer_pump_REQ : 9|1@0+ (1,0) [0|1] ""  BCU_F,VCU,M2M
 SG_ SWCU_indicator_REQ : 7|3@0+ (1,0) [0|7] ""  BCU_F,VCU,M2M
 SG_ CRC : 31|8@0+ (1,0) [0|255] ""  IVI,BCU_F,VCU
 SG_ Counter : 19|4@0+ (1,0) [0|15] ""  IVI,BCU_F,VCU
 SG_ SWCU_highbeams_REQ : 8|1@0+ (1,0) [0|1] ""  BCU_F,IVI,VCU,M2M

BO_ 1351 BCU_R_aero: 5 BCU_R
 SG_ CRC : 39|8@0+ (1,0) [0|255] ""  IVI
 SG_ Counter : 27|4@0+ (1,0) [0|15] ""  IVI
 SG_ BCU_R_rear_spoiler_tilt : 15|8@0+ (1,0) [0|0] ""  BCU_F,IVI,M2M
 SG_ BCU_R_rear_spoiler_height : 7|8@0+ (1,0) [0|0] ""  BCU_F,IVI,M2M

BO_ 772 BODY_BCU_F_ST: 4 BCU_F
 SG_ BCU_F_parking_lights_ST : 12|1@0+ (1,0) [0|1] "" IVI,VCU
 SG_ BCU_F_brake_wear_ST : 13|1@0+ (1,0) [0|1] "" IVI,M2M
 SG_ BCU_F_follow_home_lights_ST : 15|2@0+ (1,0) [0|3] "" IVI,M2M
 SG_ BCU_F_wipers_speed_ST : 3|2@0+ (1,0) [0|3] ""  VCU,IVI,M2M
 SG_ BCU_F_wipers_automode_ST : 1|2@0+ (1,0) [0|1] ""  VCU,IVI,M2M
 SG_ BCU_F_horn_ST : 11|1@0+ (1,0) [0|1] ""  IVI,M2M
 SG_ CRC : 31|8@0+ (1,0) [0|255] ""  IVI,VCU
 SG_ Counter : 19|4@0+ (1,0) [0|15] ""  IVI,VCU
 SG_ BCU_F_washer_liquid_warn : 6|1@0+ (1,0) [0|1] ""  IVI,M2M
 SG_ BCU_F_brake_fluid_warn : 7|1@0+ (1,0) [0|1] ""  IVI,M2M
 SG_ BCU_F_bonnet_open_ST : 5|1@0+ (1,0) [0|1] ""  IVI,M2M
 SG_ BCU_F_bonnet_latch_lock_ST : 4|1@0+ (1,0) [0|1] ""  IVI,M2M
 SG_ BCU_F_aero_mode_ST : 10|3@0+ (1,0) [0|7] "enum" VCU,M2M

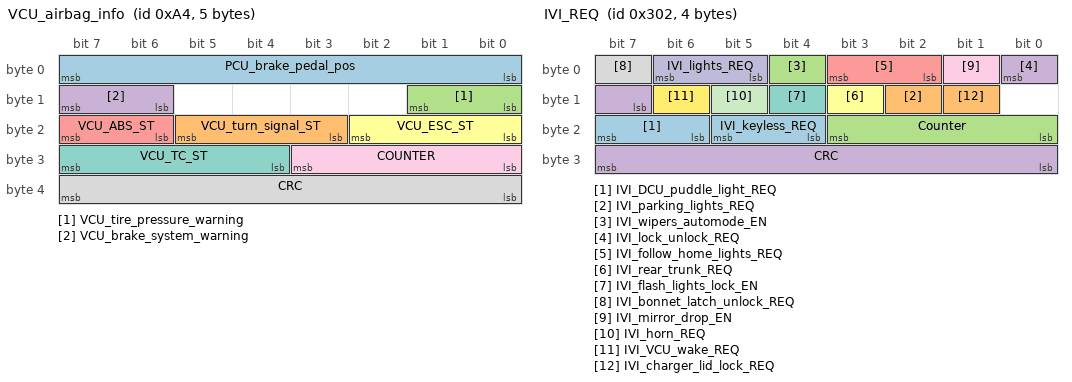
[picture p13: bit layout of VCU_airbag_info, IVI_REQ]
BO_ 164 VCU_airbag_info: 5 VCU
 SG_ PCU_brake_pedal_pos : 7|8@0+ (0.5,0) [0|100] "%"  ACU,M2M
 SG_ VCU_turn_signal_ST : 21|3@0+ (1,0) [0|7] "enum"  ACU,M2M
 SG_ VCU_tire_pressure_warning : 9|2@0+ (1,0) [0|3] ""  ACU,M2M
 SG_ VCU_brake_system_warning : 15|2@0+ (1,0) [0|3] ""  ACU,M2M
 SG_ VCU_ABS_ST : 23|2@0+ (1,0) [0|3] ""  ACU,M2M
 SG_ VCU_ESC_ST : 18|3@0+ (1,0) [0|7] ""  ACU,M2M
 SG_ VCU_TC_ST : 31|4@0+ (1,0) [0|15] ""  ACU,M2M
 SG_ CRC : 39|8@0+ (1,0) [0|255] ""  ACU
 SG_ COUNTER : 27|4@0+ (1,0) [0|15] ""  ACU

BO_ 770 IVI_REQ: 4 IVI
 SG_ IVI_DCU_puddle_light_REQ : 23|2@0+ (1,0) [0|3] ""  DCU_DRV,DCU_PSG
 SG_ IVI_parking_lights_REQ : 10|1@0+ (1,0) [0|1] "" BCU_F
 SG_ IVI_wipers_automode_EN : 4|1@0+ (1,0) [0|1] ""  BCU_F,M2M
 SG_ IVI_lock_unlock_REQ : 0|2@0+ (1,0) [0|2] ""  VCU,M2M
 SG_ IVI_follow_home_lights_REQ : 3|2@0+ (1,0) [0|3] ""  BCU_F,DCU_DRV,DCU_PSG,M2M
 SG_ IVI_rear_trunk_REQ : 11|1@0+ (1,0) [0|1] ""  VCU,M2M
 SG_ IVI_flash_lights_lock_EN : 12|1@0+ (1,0) [0|1] ""  BCU_R,M2M
 SG_ IVI_bonnet_latch_unlock_REQ : 7|1@0+ (1,0) [0|3] ""  BCU_F,M2M
 SG_ IVI_mirror_drop_EN : 1|1@0+ (1,0) [0|1] ""  DCU_DRV,DCU_PSG,M2M
 SG_ IVI_lights_REQ : 6|2@0+ (1,0) [0|2] ""  BCU_F,M2M
 SG_ IVI_horn_REQ : 13|1@0+ (1,0) [0|1] ""  BCU_F,M2M
 SG_ IVI_VCU_wake_REQ : 14|1@0+ (1,0) [0|1] "" VCU,M2M
 SG_ IVI_keyless_REQ : 21|2@0+ (1,0) [0|2] ""  VCU,M2M
 SG_ IVI_charger_lid_lock_REQ : 9|1@0+ (1,0) [0|1] ""  BCU_R
 SG_ Counter : 19|4@0+ (1,0) [0|15] ""  DCU_DRV,DCU_PSG,BCU_F,BCU_R,VCU,DBCU
 SG_ CRC : 31|8@0+ (1,0) [0|255] ""  DCU_DRV,DCU_PSG,BCU_F,BCU_R,VCU,DBCU

BO_ 771 IVI_OTA_ST: 1 IVI
 SG_ IVI_ota_update_REQ : 0|1@0+ (1,0) [0|1] ""  VCU,M2M

BO_ 769 DBCU_ST: 5 DBCU
 SG_ DBCU_SWCU_depth_position : 23|7@0+ (1,0) [0|100] "%"  IVI,M2M
 SG_ DBCU_SWCU_height_position : 15|7@0+ (1,0) [0|100] "%"  IVI,M2M
 SG_ CRC : 39|8@0+ (1,0) [0|255] ""  IVI
 SG_ Counter : 27|4@0+ (1,0) [0|15] ""  IVI
 SG_ DBCU_glovebox_lock_ST : 6|1@0+ (1,0) [0|1] ""  IVI,M2M

BO_ 782 DBCU_REQ: 1 DBCU
 SG_ DBCU_horn_REQ : 0|1@0+ (1,0) [0|1] ""  BCU_F,M2M

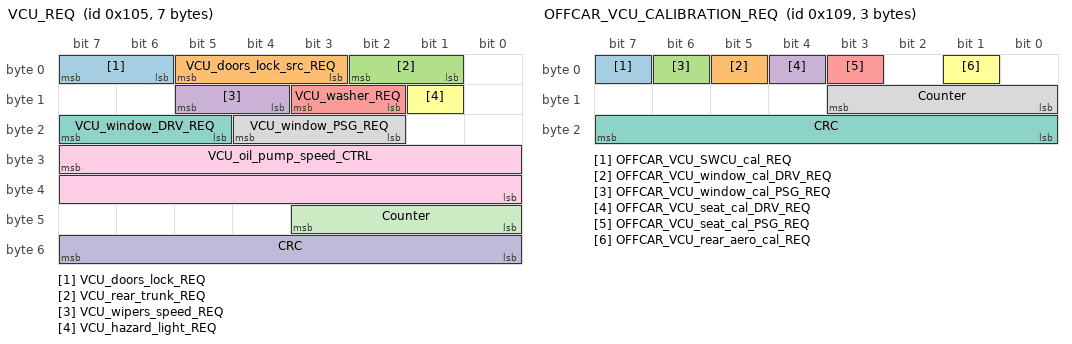
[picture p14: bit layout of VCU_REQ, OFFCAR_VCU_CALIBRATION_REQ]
BO_ 261 VCU_REQ: 7 VCU
 SG_ VCU_doors_lock_REQ : 7|2@0+ (1,0) [0|3] ""  BCU_R,DCU_DRV,DCU_PSG,DBCU,M2M,IVI
 SG_ VCU_doors_lock_src_REQ : 5|3@0+ (1,0) [0|7] ""  BCU_R,DCU_DRV,DCU_PSG,DBCU,M2M
 SG_ VCU_rear_trunk_REQ : 2|2@0+ (1,0) [0|3] "" BCU_R,M2M
 SG_ VCU_wipers_speed_REQ : 13|2@0+ (1,0) [0|3] "enum"  BCU_F,M2M
 SG_ VCU_washer_REQ : 11|2@0+ (1,0) [0|3] ""  BCU_F,M2M
 SG_ VCU_hazard_light_REQ : 9|1@0+ (1,0) [0|1] ""  BCU_F,M2M
 SG_ VCU_window_DRV_REQ : 23|3@0+ (1,0) [0|4] ""  DCU_DRV,M2M
 SG_ VCU_window_PSG_REQ : 20|3@0+ (1,0) [0|4] ""  DCU_PSG,M2M
 SG_ VCU_oil_pump_speed_CTRL : 31|16@0+ (1,0) [0|65535] ""  BCU_R,M2M
 SG_ CRC : 55|8@0+ (1,0) [0|255] ""  DBCU,DCU_DRV,DCU_PSG,BCU_F,BCU_R,IVI
 SG_ Counter : 43|4@0+ (1,0) [0|15] ""  DBCU,DCU_DRV,DCU_PSG,BCU_F,BCU_R,IVI

BO_ 265 OFFCAR_VCU_CALIBRATION_REQ: 3 OFFCAR_VCU
 SG_ OFFCAR_VCU_SWCU_cal_REQ : 7|1@0+ (1,0) [0|0] ""  DBCU
 SG_ OFFCAR_VCU_window_cal_DRV_REQ : 5|1@0+ (1,0) [0|1] ""  DCU_DRV
 SG_ OFFCAR_VCU_window_cal_PSG_REQ : 6|1@0+ (1,0) [0|1] ""  DCU_PSG
 SG_ OFFCAR_VCU_seat_cal_DRV_REQ : 4|1@0+ (1,0) [0|1] ""  SCU_DRV
 SG_ OFFCAR_VCU_seat_cal_PSG_REQ : 3|1@0+ (1,0) [0|1] ""  SCU_PSG
 SG_ OFFCAR_VCU_rear_aero_cal_REQ : 1|1@0+ (1,0) [0|1] ""  BCU_R
 SG_ CRC : 23|8@0+ (1,0) [0|255] ""  SCU_PSG,SCU_DRV,DCU_PSG,DCU_DRV,DBCU
 SG_ Counter : 11|4@0+ (1,0) [0|15] ""  SCU_PSG,SCU_DRV,DCU_PSG,DCU_DRV,DBCU

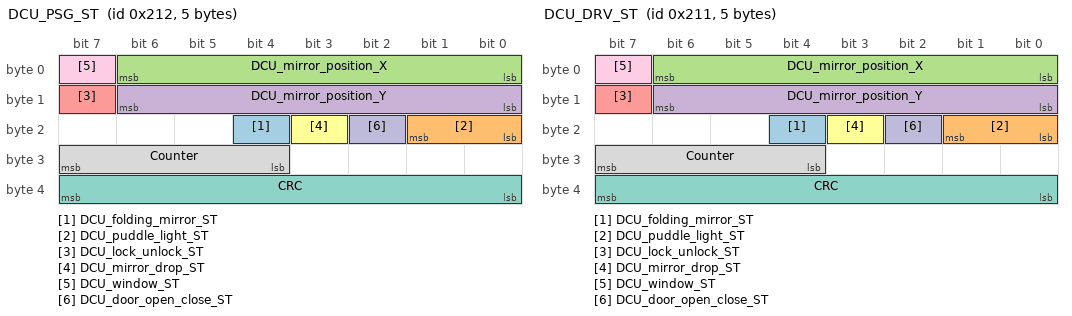
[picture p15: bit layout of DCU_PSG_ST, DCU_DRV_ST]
BO_ 530 DCU_PSG_ST: 5 DCU_PSG
 SG_ DCU_folding_mirror_ST : 20|1@0+ (1,0) [0|1] "" IVI,M2M
 SG_ DCU_puddle_light_ST : 17|2@0+ (1,0) [0|3] ""  IVI,M2M
 SG_ DCU_mirror_position_X : 6|7@0+ (1,0) [0|100] "%"  IVI,M2M
 SG_ DCU_mirror_position_Y : 14|7@0+ (1,0) [0|100] "%"  IVI,M2M
 SG_ DCU_lock_unlock_ST : 15|1@0+ (1,0) [0|1] ""  VCU,M2M
 SG_ DCU_mirror_drop_ST : 19|1@0+ (1,0) [0|1] ""  IVI,M2M
 SG_ CRC : 39|8@0+ (1,0) [0|255] ""  SCU_PSG,BCU_R,IVI,VCU
 SG_ Counter : 31|4@0+ (1,0) [0|15] ""  SCU_PSG,BCU_R,IVI,VCU
 SG_ DCU_window_ST : 7|1@0+ (1,0) [0|1] ""  IVI,VCU,M2M
 SG_ DCU_door_open_close_ST : 18|1@0+ (1,0) [0|1] ""  SCU_PSG,BCU_R,IVI,VCU,BCU_F,DCU_DRV,M2M

BO_ 263 IVI_DCU_PSG_CTRL: 3 IVI
 SG_ IVI_folding_mirror_REQ : 3|2@0+ (1,0) [0|2] "" DCU_PSG,M2M
 SG_ IVI_DCU_mirror_control_REQ : 6|3@0+ (1,0) [0|7] ""  DCU_PSG,M2M
 SG_ IVI_mirror_X_pos_REQ : 1|7@0+ (1,0) [0|127] "%"  DCU_PSG,M2M
 SG_ IVI_mirror_Y_pos_REQ : 10|7@0+ (1,0) [0|127] "%"  DCU_PSG,M2M

BO_ 264 IVI_DCU_DRV_CTRL: 3 IVI
 SG_ IVI_folding_mirror_REQ : 3|2@0+ (1,0) [0|2] "" DCU_DRV,M2M
 SG_ IVI_DCU_mirror_control_REQ : 6|3@0+ (1,0) [0|7] ""  DCU_DRV,M2M
 SG_ IVI_mirror_X_pos_REQ : 1|7@0+ (1,0) [0|127] "%"  DCU_DRV,M2M
 SG_ IVI_mirror_Y_pos_REQ : 10|7@0+ (1,0) [0|127] "%"  DCU_DRV,M2M

BO_ 266 IVI_DBCU_CTRL: 4 IVI
 SG_ IVI_glovebox_lock_REQ : 10|2@0+ (1,0) [0|3] ""  DBCU,M2M
 SG_ IVI_swcol_X_depth_REQ : 7|3@0+ (1,0) [0|7] ""  DBCU,M2M
 SG_ IVI_swcol_Y_height_REQ : 4|3@0+ (1,0) [0|7] ""  DBCU,M2M
 SG_ IVI_swcol_X_depth_pos_REQ : 1|7@0+ (1,0) [0|127] "%"  DBCU,M2M
 SG_ IVI_swcol_Y_height_pos_REQ : 8|7@0+ (1,0) [0|127] "%"  DBCU ,M2M

BO_ 529 DCU_DRV_ST: 5 DCU_DRV
 SG_ DCU_folding_mirror_ST : 20|1@0+ (1,0) [0|1] "" IVI,M2M
 SG_ DCU_puddle_light_ST : 17|2@0+ (1,0) [0|3] ""  IVI,M2M
 SG_ DCU_mirror_position_X : 6|7@0+ (1,0) [0|100] "%"  IVI,M2M
 SG_ DCU_mirror_position_Y : 14|7@0+ (1,0) [0|100] "%"  IVI,M2M
 SG_ DCU_lock_unlock_ST : 15|1@0+ (1,0) [0|1] ""  VCU,M2M
 SG_ DCU_mirror_drop_ST : 19|1@0+ (1,0) [0|1] ""  IVI,M2M
 SG_ CRC : 39|8@0+ (1,0) [0|255] ""  SCU_DRV,BCU_R,IVI,VCU
 SG_ Counter : 31|4@0+ (1,0) [0|15] ""  SCU_DRV,BCU_R,IVI,VCU
 SG_ DCU_window_ST : 7|1@0+ (1,0) [0|1] ""  IVI,VCU,M2M
 SG_ DCU_door_open_close_ST : 18|1@0+ (1,0) [0|1] ""  SCU_DRV,BCU_R,IVI,VCU,BCU_F,DCU_PSG,M2M

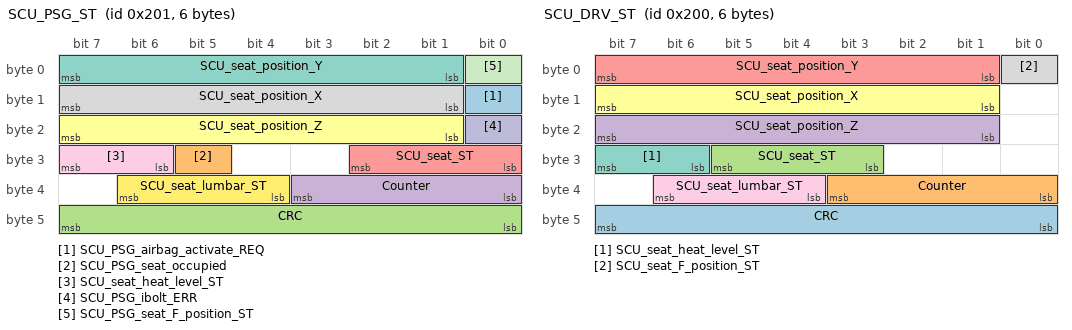
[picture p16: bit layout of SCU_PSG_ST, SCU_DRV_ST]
BO_ 513 SCU_PSG_ST: 6 SCU_PSG
 SG_ SCU_PSG_airbag_activate_REQ : 8|1@0+ (1,0) [0|1] ""  ACU,M2M
 SG_ SCU_PSG_seat_occupied : 29|1@0+ (1,0) [0|1] ""  IVI,VCU,ACU,M2M
 SG_ CRC : 47|8@0+ (1,0) [0|255] ""  IVI,ACU,VCU
 SG_ Counter : 35|4@0+ (1,0) [0|15] ""  IVI,ACU,VCU
 SG_ SCU_seat_ST : 26|3@0+ (1,0) [0|7] ""  IVI,VCU,ACU,M2M
 SG_ SCU_seat_position_Z : 23|7@0+ (1,0) [0|100] "%"  IVI,ACU,M2M
 SG_ SCU_seat_position_Y : 7|7@0+ (1,0) [0|100] "%"  IVI,ACU,M2M
 SG_ SCU_seat_position_X : 15|7@0+ (1,0) [0|100] "%"  IVI,ACU,M2M
 SG_ SCU_seat_heat_level_ST : 31|2@0+ (1,0) [0|3] ""  IVI,ACU,M2M
 SG_ SCU_PSG_ibolt_ERR : 16|1@0+ (1,0) [0|1] ""  ACU,M2M
 SG_ SCU_PSG_seat_F_position_ST : 0|1@0+ (1,0) [0|1] ""  ACU,M2M
 SG_ SCU_seat_lumbar_ST : 38|3@0+ (1,0) [0|4] ""  IVI,M2M

BO_ 512 SCU_DRV_ST: 6 SCU_DRV
 SG_ CRC : 47|8@0+ (1,0) [0|255] ""  ACU,VCU,IVI
 SG_ Counter : 35|4@0+ (1,0) [0|15] ""  ACU,VCU,IVI
 SG_ SCU_seat_ST : 29|3@0+ (1,0) [0|7] ""  ACU,VCU,IVI,M2M
 SG_ SCU_seat_position_Z : 23|7@0+ (1,0) [0|100] "%"  ACU,IVI,M2M
 SG_ SCU_seat_position_Y : 7|7@0+ (1,0) [0|100] "%"  ACU,IVI,M2M
 SG_ SCU_seat_position_X : 15|7@0+ (1,0) [0|100] "%"  ACU,IVI,M2M
 SG_ SCU_seat_heat_level_ST : 31|2@0+ (1,0) [0|0] ""  ACU,IVI,M2M
 SG_ SCU_seat_F_position_ST : 0|1@0+ (1,0) [0|1] ""  ACU,IVI,M2M
 SG_ SCU_seat_lumbar_ST : 38|3@0+ (1,0) [0|4] ""  IVI,M2M

BO_ 111 BODY_ADAS_REQ: 4 VCU
 SG_ ADAS_washer_pump_REQ : 15|2@0+ (1,0) [0|3] ""  BCU_F
 SG_ ADAS_wiper_speed_REQ : 7|8@0+ (1,0) [0|255] "enum"  BCU_F
 SG_ ADAS_ultrasonic_board_ON_REQ : 13|1@0+ (1,0) [0|1] ""  BCU_R
 SG_ CRC : 31|8@0+ (1,0) [0|255] ""  BCU_F
 SG_ COUNTER : 19|4@0+ (1,0) [0|15] ""  BCU_F

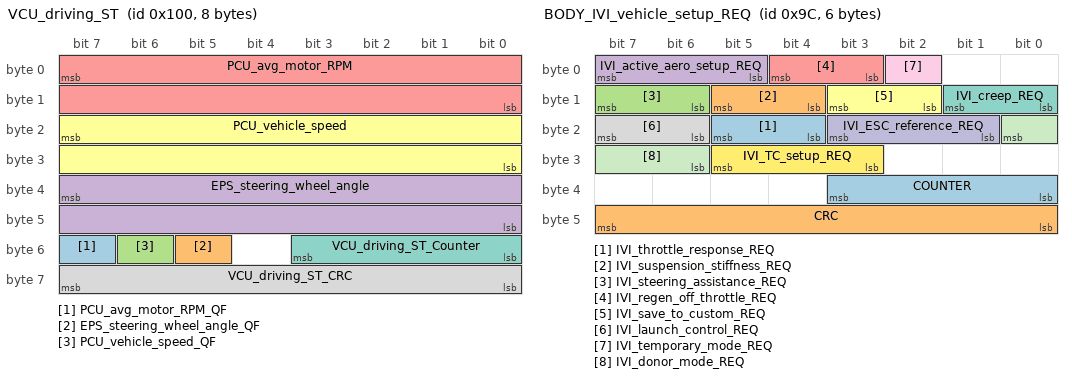
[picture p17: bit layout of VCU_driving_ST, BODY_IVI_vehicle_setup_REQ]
BO_ 256 VCU_driving_ST: 8 VCU
 SG_ PCU_avg_motor_RPM_QF : 55|1@0+ (1,0) [0|1] ""  ACU,M2M
 SG_ EPS_steering_wheel_angle_QF : 53|1@0+ (1,0) [0|1] "0"  ACU,M2M
 SG_ PCU_vehicle_speed_QF : 54|1@0+ (1,0) [0|1] "0"  ACU,M2M
 SG_ EPS_steering_wheel_angle : 39|16@0+ (0.1,-780) [-780|780] "deg"  ACU,M2M
 SG_ PCU_avg_motor_RPM : 7|16@0+ (1,0) [0|65535] "rpm"  ACU,M2M
 SG_ PCU_vehicle_speed : 23|16@0+ (0.01,0) [0|655.35] "km/h"  ACU,BCU_R,M2M
 SG_ VCU_driving_ST_Counter : 51|4@0+ (1,0) [0|15] ""  ACU
 SG_ VCU_driving_ST_CRC : 63|8@0+ (1,0) [0|255] ""  ACU

BO_ 255 BODY_PCU_vehicle_ST: 8 VCU
 SG_ PCU_vehicle_mileage_rest : 55|4@0+ (100,0) [0|1000] "m" SKM,SWCU
 SG_ PCU_vehicle_charging_ST : 30|2@0+ (1,0) [0|3] "enum"  BCU_R
 SG_ CRC : 63|8@0+ (1,0) [0|255] ""  SKM
 SG_ COUNTER : 51|4@0+ (1,0) [0|15] ""  SKM
 SG_ PCU_vehicle_mileage : 27|20@0+ (1,0) [0|1048575] "km"  SKM,SWCU
 SG_ PCU_accelerator_pedal : 7|8@0+ (0.4,0) [0|0] "%"  SKM
 SG_ PCU_vehicle_speed : 15|16@0+ (0.01,0) [0|655.35] "km/h"  SKM,BCU_F,SCU_PSG,SWCU

BO_ 778 BODY_PCU_ST: 4 VCU
 SG_ CRC : 31|8@0+ (1,0) [0|255] "" BCU_R,SKM,DCU_DRV,DCU_PSG
 SG_ COUNTER : 19|4@0+ (1,0) [0|15] "" BCU_R,SKM,DCU_DRV,DCU_PSG
 SG_ CCU_F_ambient_temp : 15|8@0+ (0.4,-40) [-40|62] "degC" DCU_DRV,DCU_PSG,SKM,SWCU,DBCU
 SG_ PDU_HV_battery_SOC : 7|8@0+ (1,0) [0|100] "%"  BCU_R,SKM,SWCU
 SG_ CCU_F_max_demist_ST : 23|1@0+ (1,0) [0|1] ""  SSCU

BO_ 156 BODY_IVI_vehicle_setup_REQ: 6 IVI
 SG_ IVI_throttle_response_REQ : 21|2@0+ (1,0) [0|3] "enum"  VCU,M2M
 SG_ IVI_suspension_stiffness_REQ : 13|2@0+ (1,0) [0|3] "enum"  VCU,M2M
 SG_ IVI_steering_assistance_REQ : 15|2@0+ (1,0) [0|3] "enum"  VCU,M2M
 SG_ IVI_active_aero_setup_REQ : 7|3@0+ (1,0) [0|4] "enum"  VCU,M2M
 SG_ IVI_regen_off_throttle_REQ : 4|2@0+ (1,0) [0|3] "enum"  VCU,M2M
 SG_ IVI_save_to_custom_REQ : 11|2@0+ (1,0) [0|3] "enum"  VCU,M2M
 SG_ IVI_creep_REQ : 9|2@0+ (1,0) [0|3] "enum"  VCU,M2M
 SG_ IVI_launch_control_REQ : 23|2@0+ (1,0) [0|3] "enum"  VCU,M2M
 SG_ IVI_temporary_mode_REQ : 2|1@0+ (1,0) [0|1] "" VCU,M2M
 SG_ IVI_ESC_reference_REQ : 19|3@0+ (1,0) [0|7] "" VCU,M2M
 SG_ IVI_donor_mode_REQ : 16|3@0+ (1,0) [0|7] "" VCU,M2M
 SG_ IVI_TC_setup_REQ : 29|3@0+ (1,0) [0|7] "" VCU,M2M
 SG_ COUNTER : 35|4@0+ (1,0) [0|15] ""  VCU
 SG_ CRC : 47|8@0+ (1,0) [0|255] ""  VCU

BO_ 144 BODY_PCU_vehicle_setup_ST: 8 VCU
 SG_ PCU_PT_front_knob_limit : 7|7@0+ (1,0) [0|127] "%"  OFFCAR_VCU
 SG_ PCU_PT_rear_knob_limit : 15|7@0+ (1,0) [0|127] "%"  OFFCAR_VCU
 SG_ PCU_stability_mode_ST : 23|3@0+ (1,0) [0|7] "enum"  KCU_DM
 SG_ PCU_throttle_response_ST : 17|2@0+ (1,0) [0|3] "enum"  OFFCAR_VCU
 SG_ PCU_PRND_mode_ST : 39|2@0+ (1,0) [0|3] "enum"  DCU_DRV,DCU_PSG,BCU_F,BCU_R,KCU_GS
 SG_ PCU_PRND_modes_AVBL : 45|4@0+ (1,0) [0|15] "enum"  KCU_GS
 SG_ PCU_steering_assistance_ST : 41|2@0+ (1,0) [0|3] "enum"  OFFCAR_VCU
 SG_ PCU_driving_mode_ST : 31|3@0+ (1,0) [0|7] "enum"  KCU_DM,KCU_GS
 SG_ PCU_regen_off_throttle_ST : 37|2@0+ (1,0) [0|3] "enum"  OFFCAR_VCU
 SG_ PCU_suspension_stiffness_ST : 35|2@0+ (1,0) [0|3] "enum"  OFFCAR_VCU
 SG_ PCU_active_aero_setup_ST : 55|3@0+ (1,0) [0|7] "enum"  BCU_F,BCU_R
 SG_ PCU_creep_ST : 47|1@0+ (1,0) [0|1] "enum"  OFFCAR_VCU
 SG_ PCU_tow_mode_ST : 46|1@0+ (1,0) [0|1] ""  OFFCAR_VCU
 SG_ PCU_ignition_ST : 52|1@0+ (1,0) [0|1] "enum" SKM,SWCU,KCU_GS
 SG_ PCU_launch_control_ST : 33|1@0+ (1,0) [0|1] "enum" OFFCAR_VCU
 SG_ COUNTER : 51|4@0+ (1,0) [0|15] ""  SKM,SWCU,KCU_GS,KCU_DM,BCU_F,BCU_R,DCU_DRV,DCU_PSG,OFFCAR_VCU
 SG_ CRC : 63|8@0+ (1,0) [0|255] ""  SKM,SWCU,KCU_GS,KCU_DM,BCU_F,BCU_R,DCU_DRV,DCU_PSG,OFFCAR_VCU

BO_ 291 BODY_PDU_HV_battery_performance: 8 VCU
 SG_ CRC : 63|8@0+ (1,0) [0|255] ""  SKM,SWCU
 SG_ COUNTER : 51|4@0+ (1,0) [0|15] ""  SKM,SWCU
 SG_ PDU_HV_battery_voltage : 7|16@0+ (0.1,0) [0|6553.5] "V"  SKM,SWCU
 SG_ PDU_HV_battery_current : 23|16@0- (0.1,0) [-3276.8|3276.7] "A"  SKM,SWCU
 SG_ PDU_HV_precharge_voltage : 39|16@0- (0.1,0) [-3276.8|3276.7] "V"  SKM,SWCU

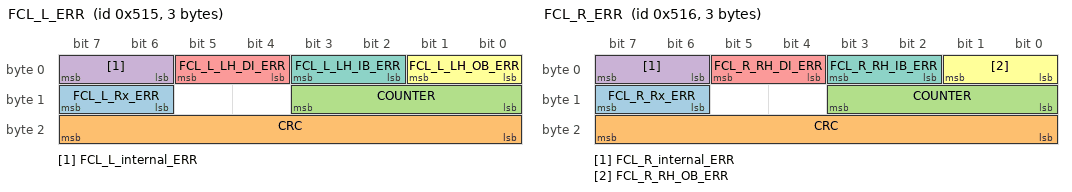
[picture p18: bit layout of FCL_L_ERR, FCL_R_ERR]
BO_ 1301 FCL_L_ERR: 3 FCL_L
 SG_ FCL_L_Rx_ERR : 15|2@0+ (1,0) [0|3] ""  VCU,BCU_F
 SG_ CRC : 23|8@0+ (1,0) [0|255] ""  VCU,BCU_F
 SG_ COUNTER : 11|4@0+ (1,0) [0|15] ""  VCU,BCU_F
 SG_ FCL_L_internal_ERR : 7|2@0+ (1,0) [0|3] ""  VCU,BCU_F
 SG_ FCL_L_LH_DI_ERR : 5|2@0+ (1,0) [0|3] ""  VCU,BCU_F
 SG_ FCL_L_LH_OB_ERR : 1|2@0+ (1,0) [0|3] ""  VCU,BCU_F
 SG_ FCL_L_LH_IB_ERR : 3|2@0+ (1,0) [0|3] ""  VCU,BCU_F

BO_ 1302 FCL_R_ERR: 3 FCL_R
 SG_ FCL_R_Rx_ERR : 15|2@0+ (1,0) [0|3] ""  VCU,BCU_F
 SG_ CRC : 23|8@0+ (1,0) [0|255] ""  VCU,BCU_F
 SG_ COUNTER : 11|4@0+ (1,0) [0|15] ""  VCU,BCU_F
 SG_ FCL_R_internal_ERR : 7|2@0+ (1,0) [0|3] ""  VCU,BCU_F
 SG_ FCL_R_RH_DI_ERR : 5|2@0+ (1,0) [0|3] ""  VCU,BCU_F
 SG_ FCL_R_RH_OB_ERR : 1|2@0+ (1,0) [0|3] ""  VCU,BCU_F
 SG_ FCL_R_RH_IB_ERR : 3|2@0+ (1,0) [0|3] ""  VCU,BCU_F

BO_ 1303 RCL_L_ERR: 3 RCL_L
 SG_ RCL_L_LED_DRIVE_4_ERR : 15|2@0+ (1,0) [0|3] ""  VCU,BCU_F
 SG_ RCL_L_LED_DRIVE_3_ERR : 7|2@0+ (1,0) [0|3] ""  VCU,BCU_F
 SG_ RCL_L_Rx_ERR : 3|2@0+ (1,0) [0|3] ""  VCU,BCU_F
 SG_ CRC : 23|8@0+ (1,0) [0|255] ""  VCU,BCU_F
 SG_ COUNTER : 11|4@0+ (1,0) [0|15] ""  VCU,BCU_F
 SG_ RCL_L_internal_ERR : 1|2@0+ (1,0) [0|3] ""  VCU,BCU_F
 SG_ RCL_L_LED_DRIVE_1_2_ERR : 5|2@0+ (1,0) [0|3] ""  VCU,BCU_F

BO_ 1304 RCL_R_ERR: 3 RCL_R
 SG_ RCL_R_LED_DRIVE_4_ERR : 15|2@0+ (1,0) [0|3] ""  VCU,BCU_F
 SG_ RCL_R_LED_DRIVE_3_ERR : 5|2@0+ (1,0) [0|3] ""  VCU,BCU_F
 SG_ RCL_R_LED_DRIVE_1_2_ERR : 7|2@0+ (1,0) [0|3] ""  VCU,BCU_F
 SG_ RCL_R_Rx_ERR : 3|2@0+ (1,0) [0|3] ""  VCU,BCU_F
 SG_ CRC : 23|8@0+ (1,0) [0|255] ""  VCU,BCU_F
 SG_ COUNTER : 11|4@0+ (1,0) [0|15] ""  VCU,BCU_F
 SG_ RCL_R_internal_ERR : 1|2@0+ (1,0) [0|3] ""  VCU,BCU_F

BO_ 1806 BODY_FCL_R_UDS_REQ: 8 IVI
 SG_ FCL_R_uds_req : 0|64@1- (1,0) [0|0] ""  FCL_R

BO_ 1807 BODY_FCL_R_UDS_RESP: 8 FCL_R
 SG_ FCL_R_uds_resp : 0|64@1- (1,0) [0|0] ""  IVI

BO_ 1804 BODY_FCL_L_UDS_REQ: 8 IVI
 SG_ FCL_L_uds_req : 0|64@1- (1,0) [0|0] ""  FCL_L

BO_ 1805 BODY_FCL_L_UDS_RESP: 8 FCL_L
 SG_ FCL_L_uds_resp : 0|64@1- (1,0) [0|0] ""  IVI

BO_ 1802 BODY_RCL_R_UDS_REQ: 8 IVI
 SG_ RCL_R_uds_req : 0|64@1- (1,0) [0|0] ""  RCL_R

BO_ 1803 BODY_RCL_R_UDS_RESP: 8 RCL_R
 SG_ RCL_R_uds_resp : 0|64@1- (1,0) [0|0] ""  IVI

BO_ 1800 BODY_RCL_L_UDS_REQ: 8 IVI
 SG_ RCL_L_uds_req : 0|64@1- (1,0) [0|0] ""  RCL_L

BO_ 1801 BODY_RCL_L_UDS_RESP: 8 RCL_L
 SG_ RCL_L_uds_resp : 0|64@1- (1,0) [0|0] ""  IVI

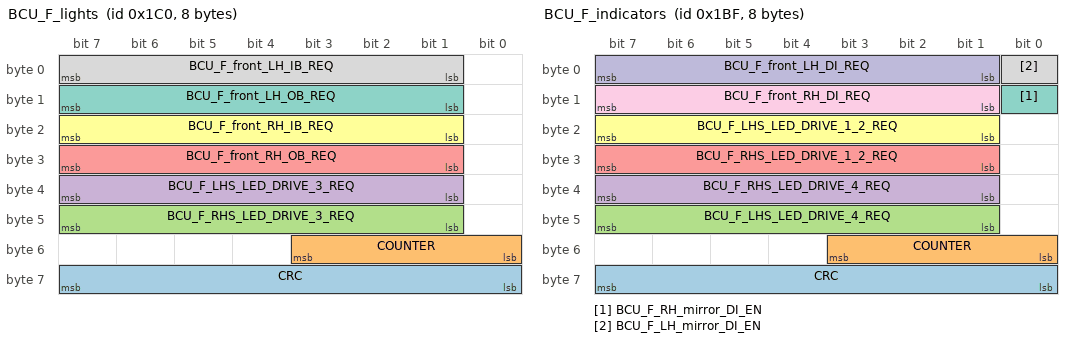
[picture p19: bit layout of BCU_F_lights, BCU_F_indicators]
BO_ 448 BCU_F_lights: 8 BCU_F
 SG_ CRC : 63|8@0+ (1,0) [0|255] ""  FCL_R,RCL_R,RCL_L,LCU_F,LCU_R
 SG_ COUNTER : 51|4@0+ (1,0) [0|15] ""  FCL_R,RCL_R,RCL_L,LCU_F,LCU_R
 SG_ BCU_F_RHS_LED_DRIVE_3_REQ : 47|7@0+ (1,0) [0|100] "%"  RCL_R,LCU_R
 SG_ BCU_F_LHS_LED_DRIVE_3_REQ : 39|7@0+ (1,0) [0|100] "%"  RCL_L,LCU_R
 SG_ BCU_F_front_RH_OB_REQ : 31|7@0+ (1,0) [0|100] "%"  FCL_R,LCU_F
 SG_ BCU_F_front_RH_IB_REQ : 23|7@0+ (1,0) [0|100] "%"  FCL_R,LCU_F
 SG_ BCU_F_front_LH_OB_REQ : 15|7@0+ (1,0) [0|100] "%"  FCL_L,LCU_F
 SG_ BCU_F_front_LH_IB_REQ : 7|7@0+ (1,0) [0|100] "%"  FCL_L,LCU_F

BO_ 447 BCU_F_indicators: 8 BCU_F
 SG_ CRC : 63|8@0+ (1,0) [0|255] ""  FCL_R,RCL_R,RCL_L,DCU_DRV,DCU_PSG,LCU_F,LCU_R,VCU
 SG_ COUNTER : 51|4@0+ (1,0) [0|15] ""  FCL_R,RCL_R,RCL_L,DCU_DRV,DCU_PSG,LCU_F,LCU_R,VCU
 SG_ BCU_F_LHS_LED_DRIVE_4_REQ : 47|7@0+ (1,0) [0|100] "%"  RCL_L,LCU_R,IVI
 SG_ BCU_F_RHS_LED_DRIVE_4_REQ : 39|7@0+ (1,0) [0|100] "%"  RCL_R,LCU_R,IVI
 SG_ BCU_F_RHS_LED_DRIVE_1_2_REQ : 31|7@0+ (1,0) [0|100] "%"  RCL_R,LCU_R
 SG_ BCU_F_LHS_LED_DRIVE_1_2_REQ : 23|7@0+ (1,0) [0|100] "%"  RCL_L,LCU_R
 SG_ BCU_F_RH_mirror_DI_EN : 8|1@0+ (1,0) [0|1] ""  DCU_PSG,IVI,VCU
 SG_ BCU_F_LH_mirror_DI_EN : 0|1@0+ (1,0) [0|1] ""  DCU_DRV,IVI,VCU
 SG_ BCU_F_front_RH_DI_REQ : 15|7@0+ (1,0) [0|100] "%"  FCL_R,LCU_F,IVI,VCU
 SG_ BCU_F_front_LH_DI_REQ : 7|7@0+ (1,0) [0|100] "%"  FCL_L,LCU_F,IVI,VCU

BO_ 128 VCU_ST: 3 VCU
 SG_ VCU_lock_ST : 7|1@0+ (1,0) [0|1] ""  SSCU
 SG_ CRC : 23|8@0+ (1,0) [0|255] ""  SSCU
 SG_ COUNTER : 11|4@0+ (1,0) [0|15] ""  SSCU

BO_ 299 BODY_PDM_F_power_WARN: 3 VCU
 SG_ PDM_F_airbag_WARN : 7|1@0+ (1,0) [0|1] "" ACU
 SG_ PDM_F_adas_WARN : 6|1@0+ (1,0) [0|1] "" ACU
 SG_ PDM_F_dcdc_WARN : 5|1@0+ (1,0) [0|1] "" ACU
 SG_ PDM_F_battery_WARN : 4|1@0+ (1,0) [0|1] "" ACU
 SG_ PDM_F_soh_WARN : 3|1@0+ (1,0) [0|1] "" ACU
 SG_ COUNTER : 11|4@0+ (1,0) [0|15] ""  ACU
 SG_ CRC : 23|8@0+ (1,0) [0|255] ""  ACU

BO_ 300 BODY_PDM_F_power_redn_WARN: 3 VCU
 SG_ PDM_F_airbag_redn_WARN : 7|1@0+ (1,0) [0|1] "" ACU
 SG_ PDM_F_adas_redn_WARN : 6|1@0+ (1,0) [0|1] "" ACU
 SG_ PDM_F_dcdc_redn_WARN : 5|1@0+ (1,0) [0|1] "" ACU
 SG_ PDM_F_battery_redn_WARN : 4|1@0+ (1,0) [0|1] "" ACU
 SG_ PDM_F_soh_redn_WARN : 3|1@0+ (1,0) [0|1] "" ACU
 SG_ COUNTER : 11|4@0+ (1,0) [0|15] ""  ACU
 SG_ CRC : 23|8@0+ (1,0) [0|255] ""  ACU

BO_ 306 BODY_PDM_R_power_WARN: 2 VCU
 SG_ PDM_R_adas_WARN : 7|1@0+ (1,0) [0|1] "" ACU
 SG_ PDM_R_dcdc_WARN : 6|1@0+ (1,0) [0|1] "" ACU
 SG_ PDM_R_battery_WARN : 5|1@0+ (1,0) [0|1] "" ACU
 SG_ PDM_R_soh_WARN : 4|1@0+ (1,0) [0|1] "" ACU
 SG_ COUNTER : 3|4@0+ (1,0) [0|15] ""  ACU
 SG_ CRC : 15|8@0+ (1,0) [0|255] ""  ACU

BO_ 307 BODY_PDM_R_power_redn_WARN: 2 VCU
 SG_ PDM_R_adas_redn_WARN : 7|1@0+ (1,0) [0|1] "" ACU
 SG_ PDM_R_dcdc_redn_WARN : 6|1@0+ (1,0) [0|1] "" ACU
 SG_ PDM_R_battery_redn_WARN : 5|1@0+ (1,0) [0|1] "" ACU
 SG_ PDM_R_soh_redn_WARN : 4|1@0+ (1,0) [0|1] "" ACU
 SG_ COUNTER : 3|4@0+ (1,0) [0|15] ""  ACU
 SG_ CRC : 15|8@0+ (1,0) [0|255] ""  ACU

BO_TX_BU_ 2028 : DBCU,IVI;
BO_TX_BU_ 2008 : DBCU,IVI;
BO_TX_BU_ 2002 : DBCU,IVI;
BO_TX_BU_ 1998 : DBCU,IVI;
BO_TX_BU_ 1996 : DBCU,IVI;
BO_TX_BU_ 1994 : DBCU,IVI;
BO_TX_BU_ 1992 : DBCU,IVI;
BO_TX_BU_ 1990 : DBCU,IVI;
BO_TX_BU_ 1988 : DBCU,IVI;
BO_TX_BU_ 1986 : DBCU,IVI;
BO_TX_BU_ 1984 : DBCU,IVI;
BO_TX_BU_ 1813 : DBCU,IVI;
BO_TX_BU_ 1954 : IVI,DBCU;
BO_TX_BU_ 1952 : IVI,DBCU;
BO_TX_BU_ 1976 : IVI,DBCU;
BO_TX_BU_ 1983 : IVI,DBCU;
BO_TX_BU_ 1972 : IVI,DBCU;
BO_TX_BU_ 1970 : IVI,DBCU;
BO_TX_BU_ 1920 : DBCU,IVI;
BO_TX_BU_ 1922 : DBCU,IVI;
BO_TX_BU_ 1924 : DBCU,IVI;
BO_TX_BU_ 1926 : DBCU,IVI;
BO_TX_BU_ 1938 : DBCU,IVI;
BO_TX_BU_ 2026 : DBCU,IVI;
BO_TX_BU_ 2024 : DBCU,IVI;
BO_TX_BU_ 1806 : DBCU,IVI;
BO_TX_BU_ 1804 : DBCU,IVI;
BO_TX_BU_ 1802 : DBCU,IVI;
BO_TX_BU_ 1800 : DBCU,IVI;
BO_TX_BU_ 947 : DBCU,IVI;
BO_TX_BU_ 949 : DBCU,IVI;
BO_TX_BU_ 951 : DBCU,IVI;
BO_TX_BU_ 953 : DBCU,IVI;
BO_TX_BU_ 955 : DBCU,IVI;
BO_TX_BU_ 957 : DBCU,IVI;
BO_TX_BU_ 959 : DBCU,IVI;
BO_TX_BU_ 961 : DBCU,IVI;
BO_TX_BU_ 963 : DBCU,IVI;
BO_TX_BU_ 965 : DBCU,IVI;
BO_TX_BU_ 967 : DBCU,IVI;
BO_TX_BU_ 969 : DBCU,IVI;
BO_TX_BU_ 971 : DBCU,IVI;
BO_TX_BU_ 973 : DBCU,IVI;
BO_TX_BU_ 975 : DBCU,IVI;
BO_TX_BU_ 977 : DBCU,IVI;
BO_TX_BU_ 979 : DBCU,IVI;
BO_TX_BU_ 981 : DBCU,IVI;
BO_TX_BU_ 983 : DBCU,IVI;
BO_TX_BU_ 985 : DBCU,IVI;
BO_TX_BU_ 987 : DBCU,IVI;
BO_TX_BU_ 989 : DBCU,IVI;
BO_TX_BU_ 991 : DBCU,IVI;
BO_TX_BU_ 993 : DBCU,IVI;
BO_TX_BU_ 995 : DBCU,IVI;
BO_TX_BU_ 997 : DBCU,IVI;
BO_TX_BU_ 999 : DBCU,IVI;
BO_TX_BU_ 1001 : DBCU,IVI;
BO_TX_BU_ 1003 : DBCU,IVI;

CM_ BU_ SSCU "7 switches stack";
CM_ SG_ 111 ADAS_ultrasonic_board_ON_REQ "ADAS ultrasonic board turn on REQ";
CM_ SG_ 1353 BCU_R_ultrasonic_board_ST "Ultrasonic board State";
CM_ SG_ 950 IVI_latitude "GPS latitude coordinate";
CM_ SG_ 950 IVI_longitude "GPS longitude coordinate";
CM_ SG_ 950 IVI_altitude "GPS altitude coordinate";
CM_ SG_ 2564460785 OFFCAR_SSCU_req "This signal is used for diagnostic purposes";
CM_ SG_ 2564485520 OFFCAR_SSCU_resp "This signal is used for diagnostic purposes";
CM_ BO_ 320 "This message is send on request when user presses button.";
CM_ SG_ 320 SSCU_rear_trunk_REQ "Rear_trunk control signal is sent when the button is pressed";
CM_ SG_ 320 SSCU_vehicle_lock_unlock_REQ "Lock_unlock control signal is sent when the button is pressed";
CM_ SG_ 320 SSCU_fog_light_REQ "Controlling the fog light";
CM_ SG_ 320 SSCU_window_PSG_REQ "Open/close door window.  ";
CM_ SG_ 320 SSCU_max_demist_REQ "Max_Demist control signal is sent when the button is pressed";
CM_ SG_ 320 SSCU_window_DRV_REQ "Open/close door window.  ";
CM_ SG_ 320 CRC "Message CRC";
CM_ SG_ 320 Counter "Message sequence number.";
CM_ BO_ 157 "Request from IVI about setting for driving modes";
CM_ SG_ 157 IVI_driving_mode_REQ "Request for driving mode";
CM_ SG_ 157 IVI_stability_mode_REQ "Request for stability level setting";
CM_ SG_ 158 IVI_PRND_mode_REQ "Request for gear";
CM_ SG_ 1300 SSCU_right_window_key_ERR "Key stuck close-after 30s continuative closed status";
CM_ SG_ 1300 SSCU_left_window_key_ERR "Key stuck close-after 30s continuative closed status";
CM_ SG_ 1300 SSCU_rear_fog_key_ERR "Key stuck close-after 30s continuative closed status";
CM_ SG_ 1300 SSCU_max_demist_key_ERR "Key stuck close-after 30s continuative closed status";
CM_ SG_ 1300 SSCU_doors_lock_key_ERR "Key stuck close-after 30s continuative closed status";
CM_ SG_ 1300 SSCU_rear_trunk_key_ERR "Key stuck close-after 30s continuative closed status";
CM_ SG_ 1300 SSCU_right_window_key_incohe_ERR "Window lifter key incoherent status-if the key gives a wrong analog voltage";
CM_ SG_ 1300 SSCU_left_window_key_incohe_ERR "Window lifter key incoherent status-if the key gives a wrong analog voltage";
CM_ SG_ 1300 SSCU_communication_ERR "CAN lines voltages, overcurrent, dominant status timeout, Rx messages";
CM_ BO_ 127 "Vehicle status message with VSM states and vehicle Modes";
CM_ SG_ 127 VCU_lock_ST "Indicating Vehicle Lock status";
CM_ SG_ 127 VCU_vehicle_ST "Current Vehicle State";
CM_ SG_ 127 VCU_auth_ST "Flag indicating if user is authenticated or not";
CM_ SG_ 127 VCU_silent_alarm_mode_ST "Vehicle Silent Alarm Mode Status";
CM_ SG_ 127 VCU_user_stealth_mode_ST "Vehicle User or Stealth Mode Status";
CM_ SG_ 127 VCU_valet_mode_ST "Vehicle Valet Mode Status";
CM_ SG_ 127 VCU_low_pwr_consump_mode_ST "Vehicle Low Power Consumption Mode Status";
CM_ SG_ 127 VCU_hibernation_mode_ST "Vehicle Hibernation Mode Status";
CM_ SG_ 127 VCU_limp_mode_ST "Vehicle Limp Mode Status";
CM_ SG_ 127 VCU_adas_drv_coach_mode_ST "Vehicle ADAS Driving Coach Mode Status";
CM_ SG_ 127 VCU_launch_control_mode_ST "Vehicle Launch Control Mode Status";
CM_ SG_ 127 VCU_towing_mode_ST "Vehicle Towing Mode Status";
CM_ SG_ 127 VCU_low_12V_battery_mode_ST "Vehicle Low 12V Battery Mode Status";
CM_ SG_ 127 VCU_ota_update_mode_ST "OTA update mode Status";
CM_ SG_ 144 PCU_ignition_ST "Telling if powertrain is engaged or disengaged from PCU side";
CM_ BO_ 144 "Acctual driving mode settings from PCU along with available ones";
CM_ SG_ 144 PCU_PRND_mode_ST "Current state of PRND state machine";
CM_ SG_ 144 PCU_PRND_modes_AVBL "List of available PRND modes";
CM_ SG_ 144 PCU_driving_mode_ST "Current driving mode";
CM_ SG_ 144 PCU_PT_front_knob_limit "Current maximum torque on front axle";
CM_ SG_ 144 PCU_PT_rear_knob_limit "Current maximum torque on rear axle";
CM_ SG_ 144 PCU_throttle_response_ST "Current throttle response";
CM_ SG_ 144 PCU_suspension_stiffness_ST "Current stifnes of suspension";
CM_ SG_ 144 PCU_steering_assistance_ST "Current steering asistance";
CM_ SG_ 144 PCU_active_aero_setup_ST "Current active aero setup";
CM_ SG_ 144 PCU_regen_off_throttle_ST "Current regen on throttle release ";
CM_ SG_ 144 PCU_creep_ST "Indicates if creep is on or off";
CM_ SG_ 144 PCU_launch_control_ST "state of the launch control from PCU";
CM_ SG_ 144 PCU_tow_mode_ST "Tow mode activated by VCU (IVI Central Display). In case of VCU to DBC1280 connexion loss, X-Boost will act as a Gateway from VCU to DBC1280";
CM_ SG_ 144 PCU_stability_mode_ST "Current stability level setting";
CM_ BO_ 157 "Request from IVI about setting for driving modes";
CM_ SG_ 158 IVI_PRND_mode_REQ "Request for gear";
CM_ SG_ 157 IVI_driving_mode_REQ "Request for driving mode";
CM_ SG_ 157 IVI_stability_mode_REQ "Request for stability level setting";
CM_ SG_ 156 IVI_throttle_response_REQ "Request for throttle response";
CM_ SG_ 156 IVI_suspension_stiffness_REQ "Request for stiffnes of the suspension";
CM_ SG_ 156 IVI_steering_assistance_REQ "Stiffnes of the steering";
CM_ SG_ 156 IVI_active_aero_setup_REQ "setup for Active Aerodynamics";
CM_ SG_ 156 IVI_regen_off_throttle_REQ "Request for regen breaking on throttle release";
CM_ SG_ 156 IVI_creep_REQ "Request for enabling or disabling creep";
CM_ SG_ 156 IVI_save_to_custom_REQ "Request form IVI to save current setting on one of the Custom modes";
CM_ SG_ 156 IVI_launch_control_REQ "Request from IVI to turn on or off launch control";
CM_ SG_ 156 IVI_temporary_mode_REQ "Request from IVI for temporary mode due to UI color change.";
CM_ SG_ 156 IVI_ESC_reference_REQ "Indicates reference state request to ESC ";
CM_ SG_ 156 IVI_donor_mode_REQ "Request for donor mode";
CM_ SG_ 156 IVI_TC_setup_REQ "Request traction control setup";
CM_ BU_ SWCU "Steering wheel Ecu";
CM_ BU_ DBCU "DASHBOARD ECU ";
CM_ BU_ BCU_F "Front BCU ";
CM_ BU_ SCU_DRV "Driver Seat ECU";
CM_ BU_ DCU_PSG "Passenger side Door ECU";
CM_ BU_ DCU_DRV "Driver side Door ECU";
CM_ BU_ SCU_PSG "Passenger Seat ECU";
CM_ BU_ ACU "T21 Crash Module";
CM_ BU_ CCCU "Central Console Control Unit";
CM_ SG_ 808 SKM_KEYBLADE_unlock_ST "SKM keyblade lock state";
CM_ SG_ 808 SKM_PEPS_active_ST "PEPS Active Status";
CM_ SG_ 808 SKM_KEYFOB_data_base_ST "Number of active KEYFOBs in SKS sistem";
CM_ SG_ 808 SKM_KEYFOB_IMMO_ST "Immobilizer authentication response";
CM_ SG_ 808 CRC "Message CRC";
CM_ SG_ 808 COUNTER "Message sequence number.";
CM_ BO_ 804 "Message containing KEYFOB statuses.";
CM_ SG_ 804 SKM_KEYFOB_PEPS_ST_4 "KEYFOB4 location";
CM_ SG_ 804 SKM_KEYFOB_PEPS_ST_3 "KEYFOB3 location";
CM_ SG_ 804 SKM_KEYFOB_PEPS_ST_2 "KEYFOB2 location";
CM_ SG_ 804 SKM_KEYFOB_PEPS_ST_1 "KEYFOB1 location";
CM_ SG_ 804 SKM_KEYFOB_RKE_distance_4 "KEYFOB4 distance indicator";
CM_ SG_ 804 SKM_KEYFOB_RKE_distance_3 "KEYFOB3 distance indicator";
CM_ SG_ 804 SKM_KEYFOB_RKE_distance_2 "KEYFOB2 distance indicator";
CM_ SG_ 804 SKM_KEYFOB_RKE_distance_1 "KEYFOB1 distance indicator";
CM_ SG_ 804 SKM_KEYFOB_RKE_ST_4 "KEYFOB4 RKE active button value";
CM_ SG_ 804 SKM_KEYFOB_RKE_ST_3 "KEYFOB3 RKE active button value";
CM_ SG_ 804 SKM_KEYFOB_RKE_ST_2 "KEYFOB2 RKE active button value";
CM_ SG_ 804 SKM_KEYFOB_RKE_ST_1 "KEYFOB1 RKE active button value";
CM_ SG_ 804 SKM_KEYFOB_battery_ST_4 "KEYFOB4 battery status";
CM_ SG_ 804 SKM_KEYFOB_battery_ST_3 "KEYFOB3 battery status";
CM_ SG_ 804 SKM_KEYFOB_battery_ST_2 "KEYFOB2 battery status";
CM_ SG_ 804 SKM_KEYFOB_battery_ST_1 "KEYFOB1 battery status";
CM_ SG_ 804 CRC "Message CRC";
CM_ SG_ 804 COUNTER "Message sequence number.";
CM_ BO_ 1919 "ACU diagnostic msg over UDS (Respond)";
CM_ BO_ 1813 "ACU diagnostic msg over UDS (Request)";
CM_ BO_ 2029 "CCCU diagnostic msg over UDS (Respond)";
CM_ BO_ 2028 "CCCU diagnostic msg over UDS (Request)";
CM_ BO_ 2009 "SWCU diagnostic msg over UDS (Respond)";
CM_ BO_ 2008 "SWCU diagnostic msg over UDS (Request)";
CM_ BO_ 2003 "SKM diagnostic msg over UDS (Respond)";
CM_ BO_ 2002 "SKM diagnostic msg over UDS (Request)";
CM_ BO_ 2001 "DBCU diagnostic msg over UDS (Respond)";
CM_ BO_ 2000 "DBCU diagnostic msg over UDS (Request)";
CM_ BO_ 1998 "BCU_R diagnostic msg over UDS (Request)";
CM_ BO_ 1999 "BCU_R diagnostic msg over UDS (Respond)";
CM_ BO_ 1997 "BCU_F diagnostic msg over UDS (Respond)";
CM_ BO_ 1996 "BCU_F diagnostic msg over UDS (Request)";
CM_ BO_ 1995 "SCU_PSG diagnostic msg over UDS (Respond)";
CM_ BO_ 1994 "SCU_PSG diagnostic msg over UDS (Request)";
CM_ BO_ 1993 "SCU_DRV diagnostic msg over UDS (Respond)";
CM_ BO_ 1992 "SCU_DRV diagnostic msg over UDS (Request)";
CM_ BO_ 1991 "DCU_PSG diagnostic msg over UDS (Respond)";
CM_ BO_ 1990 "DCU_PSG diagnostic msg over UDS (Request)";
CM_ BO_ 1989 "DCU_DRV diagnostic msg over UDS (Respond)";
CM_ BO_ 1988 "DCU_DRV diagnostic msg over UDS (Request)";
CM_ BO_ 2025 "LCU_F diagnostic msg over UDS (Respond)";
CM_ BO_ 2024 "LCU_F diagnostic msg over UDS (Request)";
CM_ BO_ 2027 "LCU_R diagnostic msg over UDS (Respond)";
CM_ BO_ 2026 "LCU_R diagnostic msg over UDS (Request)";
CM_ BO_ 1987 "IVI diagnostic msg over UDS (Respond)";
CM_ BO_ 1986 "IVI diagnostic msg over UDS (Request)";
CM_ BO_ 1985 "VCU diagnostic msg over UDS (Respond)";
CM_ BO_ 1984 "VCU diagnostic msg over UDS (Request)";
CM_ BO_ 1977 "XBOOST diagnostic msg over UDS (Respond)";
CM_ BO_ 1976 "XBOOST diagnostic msg over UDS (Request)";
CM_ BO_ 1975 "PDM_F diagnostic msg over UDS (Respond)";
CM_ BO_ 1983 "PDM_F diagnostic msg over UDS (Request)";
CM_ BO_ 1973 "PCU diagnostic msg over UDS (Respond)";
CM_ BO_ 1972 "PCU diagnostic msg over UDS (Request)";
CM_ BO_ 1971 "PDU diagnostic msg over UDS (Respond)";
CM_ BO_ 1970 "PDU diagnostic msg over UDS (Request)";
CM_ BO_ 1955 "DBC1280 diagnostic msg over UDS (Respond)";
CM_ BO_ 1954 "DBC1280 diagnostic msg over UDS (Request)";
CM_ BO_ 1953 "PDM_R diagnostic msg over UDS (Respond)";
CM_ BO_ 1952 "PDM_R diagnostic msg over UDS (Request)";
CM_ BO_ 1939 "CCU_F diagnostic msg over UDS (Respond)";
CM_ BO_ 1938 "CCU_F diagnostic msg over UDS (Request)";
CM_ BO_ 1927 "OBC diagnostic msg over UDS (Respond)";
CM_ BO_ 1926 "OBC diagnostic msg over UDS (Request)";
CM_ BO_ 1925 "CCU_R diagnostic msg over UDS (Respond)";
CM_ BO_ 1924 "CCU_R diagnostic msg over UDS (Request)";
CM_ BO_ 1923 "BFI_RL diagnostic msg over UDS (Respond)";
CM_ BO_ 1922 "BFI_RL diagnostic msg over UDS (Request)";
CM_ BO_ 1921 "BFI_RR diagnostic msg over UDS (Respond)";
CM_ BO_ 1920 "BFI_RR diagnostic msg over UDS (Request)";
CM_ BO_ 2297364746 "Hydraulic pump status message. ";
CM_ SG_ 2297364746 H_PUMP_motor_temp "Motor temperature.";
CM_ SG_ 2297364746 H_PUMP_inverter_temp "Inverter temperature. ";
CM_ SG_ 2297364746 H_PUMP_input_voltage "Input voltage.";
CM_ SG_ 2297364746 H_PUMP_actual_current "Actual current. ";
CM_ SG_ 2297364746 H_PUMP_actual_motor_speed "Actual motor speed.";
CM_ SG_ 2297364746 H_PUMP_motor_ST "Motor status signal.";
CM_ SG_ 2297364746 H_PUMP_motor_temp_low_ERR "Motor low temperature error.";
CM_ SG_ 2297364746 H_PUMP_motor_temp_high_ERR "Motor high temperature error.";
CM_ SG_ 2297364746 H_PUMP_motor_start_ERR "Motor doesn't start. ";
CM_ SG_ 2297364746 H_PUMP_motor_rampup_ERR "Motor doesn't ramp up.";
CM_ SG_ 2297364746 H_PUMP_voltage_low_ERR "Low voltage error. ";
CM_ SG_ 2297364746 H_PUMP_voltage_high_ERR "High voltage error.";
CM_ SG_ 2297364746 H_PUMP_inverter_temp_high_ERR "Inverter high temperature error.";
CM_ SG_ 2297364746 H_PUMP_inverter_current_high_ERR "Inverter high current error.";
CM_ SG_ 2297364746 H_PUMP_motor_temp_low_WARN "Motor low temperature warning. ";
CM_ SG_ 2297364746 H_PUMP_motor_temp_high_WARN "Motor high temperature warning. ";
CM_ SG_ 2297364746 H_PUMP_voltage_low_WARN "Low voltage warning. ";
CM_ SG_ 2297364746 H_PUMP_voltage_high_WARN "High voltage warning. ";
CM_ SG_ 2297364746 H_PUMP_inverter_temp_high_WARN "Inverter high temperature warning. ";
CM_ SG_ 2297364746 H_PUMP_inv_current_high_WARN "Inverter high current warning. ";
CM_ SG_ 2297364746 H_PUMP_rampup_ST "Selected rampup program status.";
CM_ BO_ 2364475905 "Hydraulic pump command message. ";
CM_ SG_ 2364475905 BCU_R_clear_err_REQ "Error clearing signal for hydraulic pump errors.";
CM_ SG_ 2364475905 BCU_R_rampup_REQ "Rampup program selection signal.";
CM_ SG_ 2364475905 BCU_R_motor_EN "Motor stop/start signal.";
CM_ SG_ 2364475905 BCU_R_set_point_motor_speed_REQ "Motor speed set point for hydraulic pump in rpm.";
CM_ SG_ 336 ACU_system_deactivated "If airbag system is disabled by diagnostic services this signal will be active";
CM_ SG_ 336 ACU_diagnostic_active "Signal for diagstic mode. Unit could be in diagnostic mode or in normal operation mode.";
CM_ SG_ 336 ACU_driver_side_crash "Impact of driver side in case of crash";
CM_ SG_ 336 ACU_front_crash "Front impact in case of crash";
CM_ SG_ 336 ACU_warning_lamp "Signal for activatoin of airbag telltale on cluster screen";
CM_ SG_ 336 ACU_passenger_AB_warning_lamp "Warning lamp ON or OFF";
CM_ SG_ 336 ACU_passenger_AB_status "Switch off passanger airbag";
CM_ SG_ 336 ACU_passenger_side_crash "Passenger side impact in case of crash";
CM_ SG_ 336 ACU_rear_crash "Rear impact in case of crash";
CM_ SG_ 336 ACU_rollover_crash "Rollover in case of crash";
CM_ SG_ 336 ACU_system_failure "This signal is active if any component fails or internal failure.Share failure with other ECUs";
CM_ SG_ 533 PCU_ignition_ST "States if powertrian is engaged or not";
CM_ SG_ 533 DBC1280_ABS_status "0x01 ABS Active 0x00 ABS Inactive";
CM_ SG_ 533 PCU_brake_pedal_applied_ST "0x00 Brake pedal not applied 0x01 Brak pedal applied";
CM_ SG_ 533 IVI_airbag_lamp_ST "0x00 Init or Faliure - lamp not working properly 0x01 - Lamp is functionig properly";
CM_ BO_ 1155 "Message sent by Bootloader PC App to start flashing.";
CM_ BO_ 1157 "Message sent by Bootloader PC App to start flashing.";
CM_ BO_ 1154 "Message to communicate with the Bootloader PC App.";
CM_ BO_ 1156 "Message to communicate with the Bootloader PC App.";
CM_ SG_ 642 OFFCAR_SKM_PEPS_EN "Command from OFFCAR PC application to SKM toTurn PEPS antennas ON";
CM_ SG_ 642 OFFCAR_SKM_learning_mode_EN "Enable KEYFOBs pairing mode";
CM_ SG_ 642 OFFCAR_SKM_IMMO_mode_EN "Enable IMMOBILISER mode";
CM_ BO_ 641 "Message containing values for KEYFOB learn.";
CM_ SG_ 641 OFFCAR_SKM_key_learn_val_4 "Key Learning Value 4";
CM_ SG_ 641 OFFCAR_SKM_key_learn_val_3 "Key Learning Value 3";
CM_ SG_ 641 OFFCAR_SKM_key_learn_val_2 "Key Learning Value 1";
CM_ SG_ 641 OFFCAR_SKM_key_learn_val_1 "Key Learning Value 1";
CM_ BO_ 1292 "Steering wheel ECU error message";
CM_ SG_ 1292 SWCU_internal_FATAL_ERR "Initializations failed";
CM_ SG_ 1292 SWCU_misc_camera_ERR "Camera error";
CM_ SG_ 1292 SWCU_mics_coach_ERR "Coach error";
CM_ SG_ 1292 SWCU_misc_voice_ERR "Voice error";
CM_ SG_ 1292 SWCU_wipers_ERR "Wipers switch error";
CM_ SG_ 1292 SWCU_washer_ERR "Washer switch error";
CM_ SG_ 1292 Counter "Payload protection counter";
CM_ SG_ 1292 CRC "Payload protection CRC";
CM_ SG_ 779 PCU_suspension_lvl_RR "Rear Right suspension level sensor value.";
CM_ SG_ 779 PCU_suspension_lvl_RL "Rear Left suspension level sensor value.";
CM_ SG_ 779 PCU_suspension_lvl_FR "Front Right suspension level sensor value.";
CM_ SG_ 779 PCU_suspension_lvl_FL "Front left suspension level sensor value.";
CM_ BO_ 1289 "Passenger seat ECU error message";
CM_ SG_ 1289 SCU_PSG_internal_FATAL_ERR "Initializations failed";
CM_ SG_ 1289 SCU_PSG_internal_ERR "Access to registers, non initialized component; Board component error.";
CM_ SG_ 1289 SCU_PSG_heater_ERR "Seat heater error";
CM_ SG_ 1289 SCU_PSG_seat_move_ERR "Seat adjustment error";
CM_ SG_ 1289 SCU_PSG_ibolt_ERR "Seat ibolt waying error for OCS";
CM_ SG_ 1289 SCU_PSG_seat_lumbar_upper_ERR "Seat lumbar upper error";
CM_ SG_ 1289 SCU_PSG_seat_lumbar_lower_ERR "Seat lumbar lower error";
CM_ SG_ 1289 Counter "Payload protection counter";
CM_ SG_ 1289 CRC "Payload protection CRC";
CM_ BO_ 1288 "Driver seat ECU error message";
CM_ SG_ 1288 SCU_DRV_internal_FATAL_ERR "Initializations failed";
CM_ SG_ 1288 SCU_DRV_internal_ERR "Access to registers, non initialized component; Board component error.";
CM_ SG_ 1288 SCU_DRV_heater_ERR "Seat heater error";
CM_ SG_ 1288 SCU_DRV_seat_move_ERR "Seat adjustment error";
CM_ SG_ 1288 SCU_DRV_seat_lumbar_upper_ERR "Seat lumbar upper error";
CM_ SG_ 1288 SCU_DRV_seat_lumbar_lower_ERR "Seat lumbar lower error";
CM_ SG_ 1288 Counter "Payload protection counter";
CM_ SG_ 1288 CRC "Payload protection CRC";
CM_ BO_ 1283 "Dashboard ECU error message";
CM_ SG_ 1283 DBCU_internal_FATAL_ERR "Initializations failed";
CM_ SG_ 1283 DBCU_internal_ERR "Access to registers, non initialized component; Board component error.";
CM_ SG_ 1283 DBCU_camera_heater_ERR "Camera heater error";
CM_ SG_ 1283 DBCU_glovebox_ERR "Glovebox lock error";
CM_ SG_ 1283 DBCU_horn_sw_ERR "Horn switch error";
CM_ SG_ 1283 DBCU_illumination_ERR "Glovebox and hand rest ilumination error";
CM_ SG_ 1283 DBCU_IVI_disp_pwr_ERR "IVI display power error";
CM_ SG_ 1283 DBCU_IVI_eth_pwr_ERR "IVI Eth switch power error";
CM_ SG_ 1283 DBCU_pre_amp_ERR "Preamp power error";
CM_ SG_ 1283 DBCU_SWCU_pwr_ERR "Steering wheel ECU power error";
CM_ SG_ 1283 DBCU_steering_clmn_depth_ERR "Steering column depth adjust error";
CM_ SG_ 1283 DBCU_steering_clmn_height_ERR "Steering column height adjust error";
CM_ SG_ 1283 DBCU_illumination_knob_ERR "Knobs illumination error";
CM_ SG_ 1283 DBCU_diag_port_pwr_ERR "OBD port power error";
CM_ SG_ 1283 DBCU_IVI_disp_knob_pwr_ERR "IVI Display knobs power error";
CM_ SG_ 1283 DBCU_CCCU_pwr_ERR "Central console ECU power error";
CM_ SG_ 1283 Counter "Payload protection counter";
CM_ SG_ 1283 CRC "Payload protection CRC";
CM_ SG_ 660 CCU_R_aero_cooling_REQ "Cooling request for active aerodynamics";
CM_ SG_ 660 CCU_F_aero_cooling_REQ "Cooling request for active aerodynamics";
CM_ BO_ 2032 "OFFCAR commands - enable non standard features, etc...";
CM_ SG_ 2032 OFFCAR_mule_gear_REQ "Offcar request to engage 1st gear - only for mule";
CM_ SG_ 127 CRC "Message CRC";
CM_ SG_ 127 COUNTER "Message sequence number.";
CM_ BO_ 803 "Message containing values for KEYFOB learn.";
CM_ SG_ 803 SKM_VCU_key_learn_val_1 "SKM to VCU Key Learning value to be encrypted and send back to SKM to unlock Key Learning mode";
CM_ SG_ 1318 SKM_KEYFOB_4_RSSI_4 "LF antenna4 RSSI signal for KEYFOB 4";
CM_ SG_ 1318 SKM_KEYFOB_4_RSSI_3 "LF antenna3 RSSI signal for KEYFOB 4";
CM_ SG_ 1318 SKM_KEYFOB_4_RSSI_2 "LF antenna2 RSSI signal for KEYFOB 4";
CM_ SG_ 1318 SKM_KEYFOB_4_RSSI_1 "LF antenna1 RSSI signal for KEYFOB 4";
CM_ SG_ 1317 SKM_KEYFOB_3_RSSI_4 "LF antenna4 RSSI signal for KEYFOB 3";
CM_ SG_ 1317 SKM_KEYFOB_3_RSSI_3 "LF antenna3 RSSI signal for KEYFOB 3";
CM_ SG_ 1317 SKM_KEYFOB_3_RSSI_2 "LF antenna2 RSSI signal for KEYFOB 3";
CM_ SG_ 1317 SKM_KEYFOB_3_RSSI_1 "LF antenna1 RSSI signal for KEYFOB 3";
CM_ SG_ 1316 SKM_KEYFOB_2_RSSI_4 "LF antenna4 RSSI signal for KEYFOB 2";
CM_ SG_ 1316 SKM_KEYFOB_2_RSSI_3 "LF antenna3 RSSI signal for KEYFOB 2";
CM_ SG_ 1316 SKM_KEYFOB_2_RSSI_2 "LF antenna2 RSSI signal for KEYFOB 2";
CM_ SG_ 1316 SKM_KEYFOB_2_RSSI_1 "LF antenna1 RSSI signal for KEYFOB 2";
CM_ SG_ 1315 SKM_KEYFOB_1_RSSI_4 "LF antenna4 RSSI signal for KEYFOB 1";
CM_ SG_ 1315 SKM_KEYFOB_1_RSSI_3 "LF antenna3 RSSI signal for KEYFOB 1";
CM_ SG_ 1315 SKM_KEYFOB_1_RSSI_2 "LF antenna2 RSSI signal for KEYFOB 1";
CM_ SG_ 1315 SKM_KEYFOB_1_RSSI_1 "LF antenna1 RSSI signal for KEYFOB 1";
CM_ SG_ 640 VCU_PEPS_EN "Command from VCU to SKM toTurn PEPS antennas ON";
CM_ SG_ 640 VCU_IMMO_mode_EN "Enable IMMOBILISER mode";
CM_ SG_ 640 CRC "Message CRC";
CM_ SG_ 640 COUNTER "Message sequence number.";
CM_ BO_ 802 "Message containing all SKM errors.";
CM_ SG_ 802 SKM_KEYFOB_learn_ERR "KEYFOB learning error while learning";
CM_ SG_ 802 SKM_LF_antenna_2_ERR "Diagnostics status of LF antenna2";
CM_ SG_ 802 SKM_LF_antenna_3_ERR "Diagnostics status of LF antenna3";
CM_ SG_ 802 SKM_LF_antenna_5_ERR "Diagnostics status of LF antenna5";
CM_ SG_ 802 SKM_LF_antenna_4_ERR "Diagnostics status of LF antenna4";
CM_ SG_ 802 SKM_LF_antenna_7_ERR "Diagnostics status of LF antenna7";
CM_ SG_ 802 SKM_LF_antenna_6_ERR "Diagnostics status of LF antenna6";
CM_ SG_ 802 SKM_LF_antenna_8_ERR "Diagnostics status of LF antenna8";
CM_ SG_ 802 SKM_LF_antenna_1_ERR "Diagnostics status of LF antenna1";
CM_ SG_ 802 CRC "Message CRC";
CM_ SG_ 802 COUNTER "Message sequence number.";
CM_ SG_ 801 SKM_PEPS_active_ST "PEPS Active Status";
CM_ SG_ 801 SKM_KEYFOB_battery_ST_4 "KEYFOB4 battery status";
CM_ SG_ 801 SKM_KEYFOB_battery_ST_3 "KEYFOB3 battery status";
CM_ SG_ 801 SKM_KEYFOB_battery_ST_2 "KEYFOB2 battery status";
CM_ SG_ 801 SKM_KEYFOB_RKE_ST_4 "KEYFOB4 RKE active button value";
CM_ SG_ 801 SKM_KEYFOB_RKE_ST_3 "KEYFOB3 RKE active button value";
CM_ SG_ 801 SKM_KEYFOB_RKE_ST_2 "KEYFOB2 RKE active button value";
CM_ SG_ 801 SKM_KEYFOB_RKE_ST_1 "KEYFOB1 RKE active button value";
CM_ SG_ 801 SKM_KEYFOB_PEPS_ST_4 "KEYFOB4 location";
CM_ SG_ 801 SKM_KEYFOB_PEPS_ST_3 "KEYFOB3 location";
CM_ SG_ 801 SKM_KEYFOB_PEPS_ST_2 "KEYFOB2 location";
CM_ SG_ 801 SKM_KEYFOB_PEPS_ST_1 "KEYFOB1 location";
CM_ SG_ 801 SKM_KEYFOB_data_base_ST "Number of active KEYFOBs in SKS sistem";
CM_ SG_ 801 SKM_KEYFOB_battery_ST_1 "KEYFOB1 battery status";
CM_ SG_ 801 SKM_KEYFOB_IMMO_ST "Immobilizer authentication response";
CM_ SG_ 801 CRC "Message CRC";
CM_ SG_ 801 COUNTER "Message sequence number.";
CM_ SG_ 582 KW_susp_CAN_ID_rx_ERR "receive error of can message 0 = no error, 1 = error";
CM_ SG_ 582 KW_susp_XXXX_2 "receive error of can message 0 = no error, 1 = error";
CM_ SG_ 582 KW_susp_XXXXX_2 "receive error of can message 0 = no error, 1 = error";
CM_ SG_ 582 KW_susp_XXXXX_1 "receive error of can message 0 = no error, 1 = error";
CM_ SG_ 582 KW_susp_mode_ST "KW ECU selected susp mode
2 = mode 2 - blue (soft)
4 = mode 4 - purple (medium)
5 = mode 5 - red (hard)";
CM_ SG_ 1150 SWCU_bootloader "Boot loader signal for SWCU";
CM_ SG_ 1151 OFFCAR_SWCU_bootloader "Boot loader for SWCU";
CM_ BO_ 1282 "Body front ECU error message";
CM_ SG_ 1282 BCU_F_internal_FATAL_ERR "Initializations failed";
CM_ SG_ 1282 BCU_F_internal_ERR "Access to registers, non initialized component; Board component error.";
CM_ SG_ 1282 BCU_F_brake_wear_ERR "Brake wear sensor error";
CM_ SG_ 1282 BCU_F_dampers_ERR "Dampers error";
CM_ SG_ 1282 BCU_F_horn_1_ERR "Horn 1 error";
CM_ SG_ 1282 BCU_F_sidemarks_ERR "Sidemarks error";
CM_ SG_ 1282 BCU_F_washer_ERR "Washer fluid error";
CM_ SG_ 1282 BCU_F_wipers_ERR "Wipers error";
CM_ SG_ 1282 BCU_F_horn_2_ERR "Horn 2 error";
CM_ SG_ 1282 Counter "Payload protection counter";
CM_ SG_ 1282 CRC "Payload protection CRC";
CM_ BO_ 768 "Message containing all requests which need to go to different networks.";
CM_ SG_ 768 IVI_charge_current_LIM_CTRL "Charging limit of the HV battery set by the IVI";
CM_ SG_ 768 IVI_valet_mode_REQ "Request valet mode";
CM_ SG_ 768 IVI_AC_temp_CTRL "AC temp control";
CM_ SG_ 768 IVI_AC_ON_CTRL "AC ON Signal Control";
CM_ SG_ 768 IVI_AC_fan_speed_REQ "AC FAN Control";
CM_ SG_ 768 IVI_AC_max_demist_REQ "Request max demist mode";
CM_ SG_ 768 IVI_AC_max_cooling_REQ "Request max cooling mode - when temperature reaches 16deg";
CM_ SG_ 768 IVI_AC_max_heating_REQ "Request max heating mode - when temperature reaches 28deg";
CM_ SG_ 768 IVI_AC_auto_mode_REQ "Request AC auto mode";
CM_ SG_ 768 IVI_precooling_REQ "Precooling request from Mobile App";
CM_ SG_ 768 IVI_preheating_REQ "Preheating request from Mobile App";
CM_ SG_ 768 Counter "Message sequence number.";
CM_ SG_ 768 CRC "Message CRC";
CM_ BO_ 409 "Vehicle ECU error message";
CM_ SG_ 409 VCU_internal_FATAL_ERR "Initializations failed";
CM_ SG_ 409 VCU_internal_ERR "Access to registers, non initialized component; Board component error.";
CM_ SG_ 409 VCU_hazard_input_ERR "Hazzard input error";
CM_ SG_ 409 VCU_power_on_mdl_ERR "Power on module error";
CM_ SG_ 409 VCU_wakeup_ERR "Wakeup error";
CM_ SG_ 409 VCU_central_disp_ERR "Central display ECU input error";
CM_ SG_ 409 VCU_ADSA_E_ERR "Adas extension ECU input error";
CM_ SG_ 409 VCU_PCU_ERR "PCU ECU input error";
CM_ SG_ 409 VCU_PDM_F_ERR "PDM front ECU input error";
CM_ SG_ 409 VCU_PDM_R_ERR "PDM rear ECU input error";
CM_ SG_ 409 Counter "Payload protection counter";
CM_ SG_ 409 CRC "Payload protection CRC";
CM_ SG_ 137 VCU_vehicle_ST_WARN "Vehicle state warning ";
CM_ SG_ 137 VCU_stability_lvl_WARN "Stability level waring ";
CM_ SG_ 137 VCU_R_PT_WARN "Rear powertrain warning ";
CM_ SG_ 137 VCU_gear_WARN "Gear warning ";
CM_ SG_ 137 VCU_F_PT_WARN "Front powertrain warning ";
CM_ SG_ 137 VCU_driving_mode_WARN "Driving mode warning ";
CM_ SG_ 140 VCU_parking_brake_applied "The status of the barking brake ";
CM_ SG_ 140 VCU_activate_brakes "State of brake activation from ESP (routed through BCM gateway).";
CM_ SG_ 1353 BCU_R_brake_wear_ST "Brake wear OK/Not OK";
CM_ SG_ 1353 BCU_R_fog_light_ST "Fog light ON/OFF";
CM_ SG_ 1353 BCU_R_tailgate_ST "State of the tailgate.";
CM_ SG_ 1353 BCU_R_Hpump_pressure "Pressure measured after hydraulic pump.";
CM_ SG_ 1353 BCU_R_Hpump_temp "Hydraulic pump current temperature";
CM_ SG_ 1353 BCU_R_suspension_lvl_ST "State of suspension level";
CM_ SG_ 1353 BCU_R_aero_mode_ST "Current rear active aero feedback state";
CM_ SG_ 1353 BCU_R_charger_lid_lock_ST "Charger lid lock state";
CM_ SG_ 848 SWCU_cruise_control_REQ "Cruise control ON/OFF request from steering wheel.";
CM_ SG_ 848 SWCU_siri_google_REQ "Siri or Google Voice request.";
CM_ SG_ 848 SWCU_highbeams_flash_REQ "Highbeams flash request from steering wheel.";
CM_ SG_ 848 SWCU_lift_function_REQ "Lift function request from steering wheel.";
CM_ SG_ 848 SWCU_voice_cmd_REQ "Request ADAS to start listening.";
CM_ SG_ 848 SWCU_volume_inc_REQ "Volume increase request from steering wheel.";
CM_ SG_ 848 SWCU_phone_REQ "Phone ON/OFF  request from steering wheel.";
CM_ SG_ 848 SWCU_volume_dec_REQ "Volume decrease request from steering wheel.";
CM_ SG_ 848 SWCU_wipe_once_REQ "Wipe Once request from steering wheel.";
CM_ SG_ 848 SWCU_cruise_speed_inc_REQ "Cruise control speed increase request from steering wheel.";
CM_ SG_ 848 SWCU_cruise_speed_dec_REQ "Cruise control speed decrease request from steering wheel.";
CM_ SG_ 848 SWCU_washer_pump_REQ "Washer request from steering wheel.";
CM_ SG_ 848 SWCU_indicator_REQ "Indicator request from steering wheel.";
CM_ SG_ 848 SWCU_highbeams_REQ "Highbeams request from steering wheel.";
CM_ SG_ 1351 BCU_R_rear_spoiler_tilt "Position of rear spoiler anglet actuator.";
CM_ SG_ 1351 BCU_R_rear_spoiler_height "Position of rear spoiler height actuator.";
CM_ SG_ 772 BCU_F_parking_lights_ST "Status of the parking lights.";
CM_ SG_ 772 BCU_F_wipers_speed_ST "State of wiper speed.";
CM_ SG_ 772 BCU_F_wipers_automode_ST "State of wiper auto mode.";
CM_ SG_ 772 BCU_F_washer_liquid_warn "send warning to cluster display to display telltale when washer liquid level is low";
CM_ SG_ 772 BCU_F_brake_fluid_warn "Brake fluid level sensor output";
CM_ SG_ 772 BCU_F_bonnet_open_ST "Bonnet position state";
CM_ SG_ 772 BCU_F_bonnet_latch_lock_ST "Bonnet latch lock state";
CM_ SG_ 770 IVI_charger_lid_lock_REQ "Request for charger lid lock/unlock";
CM_ SG_ 772 BCU_F_brake_wear_ST "Brake wear OK/Not OK";
CM_ SG_ 772 BCU_F_follow_home_lights_ST "Chosen duration for the follow home lights. ";
CM_ SG_ 772 BCU_F_horn_ST "Horn state";
CM_ SG_ 772 BCU_F_aero_mode_ST "Current front active aero feedback state";
CM_ SG_ 770 IVI_parking_lights_REQ "Control of the parking lights.";
CM_ SG_ 770 IVI_wipers_automode_EN "enable and disable the feature of autowiping";
CM_ SG_ 770 IVI_lock_unlock_REQ "IVI request to lock or unlock the car";
CM_ SG_ 770 IVI_keyless_REQ "IVI request to disable or re-enable the immobilizer";
CM_ SG_ 770 IVI_follow_home_lights_REQ "Duration for the follow home lights. ";
CM_ SG_ 770 IVI_rear_trunk_REQ "Rear_trunk control signal is sent when the button is pressed.";
CM_ SG_ 770 IVI_flash_lights_lock_EN "Enable/disable flashing headlights when locking/unlocking the vehicle";
CM_ SG_ 770 IVI_mirror_drop_EN "Enable and disable the feature of mirror reverse assistance (mirror drop)";
CM_ SG_ 770 IVI_lights_REQ "Control headlights from IVI";
CM_ SG_ 770 IVI_horn_REQ "Horn request from IVI";
CM_ SG_ 770 IVI_DCU_puddle_light_REQ "Duration for the puddle lights feature";
CM_ SG_ 770 IVI_VCU_wake_REQ "IVI request to go to VSM Standby and prevent going to Sleep";
CM_ BO_ 771 "IVI OTA Update Status message";
CM_ SG_ 771 IVI_ota_update_REQ "IVI OTA Update request";
CM_ SG_ 776 IVI_seat_Z_pos_REQ "Position request from 0% to 100% for backrest angle adjustment. 127 = SNA value";
CM_ SG_ 776 IVI_seat_Y_pos_REQ "Position request from 0% to 100% for height adjustment. 127 = SNA value";
CM_ SG_ 776 IVI_seat_X_pos_REQ "Position request from 0% to 100% for depth adjustment. 127 = SNA value";
CM_ SG_ 777 IVI_seat_Z_pos_REQ "Position request from 0% to 100% for backrest angle adjustment. 127 = SNA value";
CM_ SG_ 777 IVI_seat_Y_pos_REQ "Position request from 0% to 100% for height adjustment. 127 = SNA value";
CM_ SG_ 777 IVI_seat_X_pos_REQ "Position request from 0% to 100% for depth adjustment. 127 = SNA value";
CM_ SG_ 263 IVI_folding_mirror_REQ "Mirror folding request.";
CM_ SG_ 263 IVI_mirror_Y_pos_REQ "Position request from 0% to 100% for up/down adjustment. 127 = SNA value";
CM_ SG_ 263 IVI_mirror_X_pos_REQ "Position request from 0% to 100% for left/right adjustment. 127 = SNA value";
CM_ SG_ 264 IVI_folding_mirror_REQ "Mirror folding request.";
CM_ SG_ 264 IVI_mirror_Y_pos_REQ "Position request from 0% to 100% for up/down adjustment. 127 = SNA value";
CM_ SG_ 264 IVI_mirror_X_pos_REQ "Position request from 0% to 100% for left/right adjustment. 127 = SNA value";
CM_ BO_ 266 "IVI steering wheel control.";
CM_ SG_ 266 IVI_glovebox_lock_REQ "Glove box compartment lock/unlock signal.";
CM_ SG_ 266 IVI_swcol_X_depth_REQ "Request change of depth position of steering wheel.";
CM_ SG_ 266 IVI_swcol_Y_height_REQ "Request change of height position of steering wheel.";
CM_ SG_ 266 IVI_swcol_X_depth_pos_REQ "Position request from 0% to 100% for depth adjustment. 127 = SNA value";
CM_ SG_ 266 IVI_swcol_Y_height_pos_REQ "Position request from 0% to 100% for height adjustment. 127 = SNA value";
CM_ BO_ 781 "This message is sent on request when user moves media joystick on central console.";
CM_ SG_ 781 CCCU_DIR_A_REQ "Media joystick pushed forward.";
CM_ SG_ 781 CCCU_DIR_C_REQ "Media joystick pushed backward.";
CM_ SG_ 781 CCCU_DIR_B_REQ "Media joystick pushed towards left.";
CM_ SG_ 781 CCCU_DIR_D_REQ "Media joystick pushed towards right.";
CM_ SG_ 781 CCCU_PUSH_REQ "Media joystick pressed.";
CM_ SG_ 781 CCCU_rotaryEncoder_REQ "Media joystick knob rotation.";
CM_ SG_ 769 DBCU_SWCU_depth_position "Steering wheel depth position";
CM_ SG_ 769 DBCU_SWCU_height_position "Steering wheel height position";
CM_ SG_ 769 DBCU_glovebox_lock_ST "Glove box locking state ";
CM_ SG_ 782 DBCU_horn_REQ "Horn request from steering wheel.";
CM_ SG_ 261 VCU_doors_lock_REQ "Door lock request.";
CM_ SG_ 261 VCU_rear_trunk_REQ "Rear trunk open/close request.";
CM_ SG_ 261 VCU_hazard_light_REQ "Hazard light activation request";
CM_ SG_ 261 VCU_window_DRV_REQ "Request to move one window all the way down or up. It is done on SKM request when LOCK or UNLOCK is held more than 3seconds or when CCCU DRV window button is pressed";
CM_ SG_ 261 VCU_window_PSG_REQ "Request to move one window all the way down or up. It is done on SKM request when LOCK or UNLOCK is held more than 3seconds or when CCCU PSG window button is pressed";
CM_ SG_ 530 DCU_folding_mirror_ST "Mirror fold state.";
CM_ SG_ 530 DCU_puddle_light_ST "Puddle light duration state.";
CM_ SG_ 530 DCU_mirror_position_X "Mirror position in X.";
CM_ SG_ 530 DCU_mirror_position_Y "Mirror position in Y.";
CM_ SG_ 530 DCU_lock_unlock_ST "State of door latch.";
CM_ SG_ 530 DCU_mirror_drop_ST "State of mirror reverse assistance (drop) enable feature.";
CM_ SG_ 530 DCU_window_ST "State of window position.";
CM_ SG_ 530 DCU_door_open_close_ST "State of door position.";
CM_ BO_ 264 "IVI driver door control";
CM_ SG_ 264 IVI_DCU_mirror_control_REQ "Request change of position of mirror.";
CM_ SG_ 529 DCU_folding_mirror_ST "Mirror fold state.";
CM_ SG_ 529 DCU_puddle_light_ST "Puddle light duration state.";
CM_ SG_ 529 DCU_mirror_position_X "Mirror position in X.";
CM_ SG_ 529 DCU_mirror_position_Y "Mirror position in Y.";
CM_ SG_ 529 DCU_lock_unlock_ST "State of door latch.";
CM_ SG_ 529 DCU_mirror_drop_ST "State of mirror reverse assistance (drop) enable feature.";
CM_ SG_ 529 DCU_window_ST "State of window position.";
CM_ SG_ 529 DCU_door_open_close_ST "State of door position.";
CM_ SG_ 513 SCU_seat_position_Z "Z position in % (0% - 100%)";
CM_ SG_ 513 SCU_seat_position_Y "Y position in % (0% - 100%)";
CM_ SG_ 513 SCU_seat_position_X "X position in % (0% - 100%)";
CM_ SG_ 513 SCU_PSG_ibolt_ERR "States if there is an error in iBolt system. 0x0 No Error 0x1 Error";
CM_ SG_ 513 SCU_PSG_seat_F_position_ST "States if the passenger seat is in full front position. With some treshold";
CM_ SG_ 512 SCU_seat_position_Z "Z position in % (0% - 100%)";
CM_ SG_ 512 SCU_seat_position_Y "Y position in % (0% - 100%)";
CM_ SG_ 512 SCU_seat_position_X "X position in % (0% - 100%)";
CM_ SG_ 512 SCU_seat_F_position_ST "States if the Driver seat is in full front position. With some treshold";
CM_ SG_ 111 ADAS_washer_pump_REQ "ADAS request to run windscreen washer pump.";
CM_ SG_ 111 ADAS_wiper_speed_REQ "ADAS request to set windscreen wiper speed.";
CM_ SG_ 256 PCU_avg_motor_RPM_QF "Qualifier for motorRPM value. ";
CM_ SG_ 256 PCU_avg_motor_RPM "Indicates average value of all 4 motors RMP for data logging";
CM_ BO_ 255 "Speed Message sent as an input to the steering ECU and airbag.";
CM_ SG_ 255 PCU_vehicle_charging_ST "State of charging process of vehicle.";
CM_ SG_ 255 CRC "Message CRC.";
CM_ SG_ 255 COUNTER " ";
CM_ SG_ 255 PCU_vehicle_mileage "Total mileage done by vehicle.";
CM_ SG_ 255 PCU_accelerator_pedal "Position of accelerator pedal.";
CM_ SG_ 255 PCU_vehicle_speed "Vehicle speed";
CM_ BO_ 524 "Request for the color and intensity of ambient light";
CM_ SG_ 524 IVI_red_REQ "Ambient light red color";
CM_ SG_ 524 IVI_green_REQ "Ambient light green color";
CM_ SG_ 524 IVI_blue_REQ "Ambient light blue color";
CM_ SG_ 524 IVI_white_red_REQ "White ambient light red value";
CM_ SG_ 524 IVI_white_green_REQ "White ambient light green value";
CM_ SG_ 524 IVI_white_blue_REQ "White ambient light blue value";
CM_ SG_ 524 IVI_intensity_REQ "Ambient light intensity";
CM_ BO_ 1299 "Central console ECU error message";
CM_ SG_ 1299 CCCU_internal_FATAL_ERR "Initializations failed";
CM_ SG_ 1299 CCCU_internal_ERR "Access to registers, non initialized component; Board component error.";
CM_ SG_ 1299 CCCU_joystick_ERR "Joystick error";
CM_ SG_ 1299 Counter "Payload protection counter";
CM_ SG_ 1299 CRC "Payload protection CRC";
CM_ BO_ 1280 "Driver door ECU error message";
CM_ SG_ 1280 DCU_DRV_internal_FATAL_ERR "Initializations failed";
CM_ SG_ 1280 DCU_DRV_internal_ERR "Access to registers, non initialized component; Board component error.";
CM_ SG_ 1280 DCU_DRV_door_latch_ERR "Door latch error";
CM_ SG_ 1280 DCU_DRV_mirror_adj_ERR "Mirror adjustment mechanism error";
CM_ SG_ 1280 DCU_DRV_mirror_heater_ERR "Mirror heater error";
CM_ SG_ 1280 DCU_DRV_puddle_light_ERR "Puddle light error";
CM_ SG_ 1280 DCU_DRV_window_ERR "Window adjustment mechanism error";
CM_ SG_ 1280 DCU_DRV_ambinet_light_ERR "Door ambient light error";
CM_ SG_ 1280 DCU_DRV_indicator_ERR "Door indicator error";
CM_ SG_ 1280 DCU_DRV_crash_detection_ERR "Crash detection error";
CM_ SG_ 1280 DCU_DRV_can_rx_ERR "CAN RX error (cyclic message not received - timeout)";
CM_ SG_ 1280 Counter "Payload protection counter";
CM_ SG_ 1280 CRC "Payload protection CRC";
CM_ BO_ 1281 "Passenger door ECU error message";
CM_ SG_ 1281 DCU_PSG_internal_FATAL_ERR "Initializations failed";
CM_ SG_ 1281 DCU_PSG_internal_ERR "Access to registers, non initialized component; Board component error.";
CM_ SG_ 1281 DCU_PSG_door_latch_ERR "Door latch error";
CM_ SG_ 1281 DCU_PSG_mirror_adj_ERR "Mirror adjustment mechanism error";
CM_ SG_ 1281 DCU_PSG_mirror_heater_ERR "Mirror heater error";
CM_ SG_ 1281 DCU_PSG_puddle_light_ERR "Puddle light error";
CM_ SG_ 1281 DCU_PSG_window_ERR "Window adjustment mechanism error";
CM_ SG_ 1281 DCU_PSG_ambinet_light_ERR "Door ambient light error";
CM_ SG_ 1281 DCU_PSG_indicator_ERR "Door indicator error";
CM_ SG_ 1281 DCU_PSG_crash_detection_ERR "Crash detection error";
CM_ SG_ 1281 DCU_PSG_can_rx_ERR "CAN RX error (cyclic message not received - timeout)";
CM_ SG_ 1281 Counter "Payload protection counter";
CM_ SG_ 1281 CRC "Payload protection CRC";
CM_ BO_ 1293 "Body rear ECU error message";
CM_ SG_ 1293 BCU_R_internal_FATAL_ERR "Initializations failed";
CM_ SG_ 1293 BCU_R_internal_ERR "Access to registers, non initialized component; Board component error.";
CM_ SG_ 1293 BCU_R_hydraulic_pump_ERR "Hydraulic pump error";
CM_ SG_ 1293 BCU_R_hydraulic_accumulator_ERR "Hydraulic accumulator error";
CM_ SG_ 1293 BCU_R_suspension_ERR "Suspension lift error";
CM_ SG_ 1293 BCU_R_wing_angle_ERR "Wing angle adjust error";
CM_ SG_ 1293 BCU_R_wing_height_ERR "Wing height error";
CM_ SG_ 1293 BCU_R_reverse_light_ERR "Reverse light error";
CM_ SG_ 1293 BCU_R_fog_light_ERR "Fog light error";
CM_ SG_ 1293 BCU_R_brakes_wear_ERR "Brake wear sensor error";
CM_ SG_ 1293 BCU_R_tailgate_latch_ERR "Tailgate latch error";
CM_ SG_ 1293 BCU_R_sidemarks_ERR "Sidemarks error";
CM_ SG_ 1293 BCU_R_licenselight_ERR "Licence plate light error";
CM_ SG_ 1293 BCU_R_brake_light_ERR "Third brake light error";
CM_ SG_ 1293 BCU_R_trunk_light_ERR "Trunk light error";
CM_ SG_ 1293 BCU_R_ultrasonic_board_ERR  "Ultrasonic board error";
CM_ SG_ 1293 Counter "Payload protection counter";
CM_ SG_ 1293 CRC "Payload protection CRC";
CM_ BO_ 1305 "SKM ECU error message";
CM_ SG_ 1305 SKM_internal_FATAL_ERR "Initializations failed";
CM_ SG_ 1305 SKM_internal_ERR "Access to registers, non initialized component; Board component error.";
CM_ SG_ 1305 SKM_immobilizer_ERR "Immobilizer error";
CM_ SG_ 1305 SKM_keyfob_ERR "Keyfob error";
CM_ SG_ 1305 SKM_PEPS_ERR "PEPS error";
CM_ SG_ 1305 Counter "Payload protection counter";
CM_ SG_ 1305 CRC "Payload protection CRC";
CM_ SG_ 291 CRC "Message CRC";
CM_ SG_ 291 COUNTER "Message sequence number.";
CM_ SG_ 291 PDU_HV_battery_voltage "Measured voltage of the energy store. ";
CM_ SG_ 291 PDU_HV_battery_current "Measured current of the energy store. ";
CM_ SG_ 448 BCU_F_RHS_LED_DRIVE_3_REQ "Left hand outboard PWM duty rate request.";
CM_ SG_ 448 BCU_F_LHS_LED_DRIVE_3_REQ "Left hand outboard PWM duty rate request.";
CM_ SG_ 448 BCU_F_front_RH_OB_REQ "Right hand outboard PWM duty rate request.";
CM_ SG_ 448 BCU_F_front_RH_IB_REQ "Right hand inboard PWM duty rate request.";
CM_ SG_ 448 BCU_F_front_LH_OB_REQ "Left hand outboard PWM duty rate request.";
CM_ SG_ 448 BCU_F_front_LH_IB_REQ "Left hand inboard PWM duty rate request.";
CM_ SG_ 447 BCU_F_LHS_LED_DRIVE_4_REQ "Right hand inboard PWM duty rate request.";
CM_ SG_ 447 BCU_F_RHS_LED_DRIVE_4_REQ "Right hand inboard PWM duty rate request.";
CM_ SG_ 447 BCU_F_RHS_LED_DRIVE_1_2_REQ "Left hand inboard PWM duty rate request.";
CM_ SG_ 447 BCU_F_LHS_LED_DRIVE_1_2_REQ "Left hand inboard PWM duty rate request.";
CM_ SG_ 447 BCU_F_RH_mirror_DI_EN "Right hand mirror indicator control.";
CM_ SG_ 447 BCU_F_LH_mirror_DI_EN "Left hand mirror indicator control.";
CM_ SG_ 447 BCU_F_front_RH_DI_REQ "Right hand direction indicator PWM duty rate request.";
CM_ SG_ 447 BCU_F_front_LH_DI_REQ "Left hand direction indicator PWM duty rate request.";
CM_ SG_ 128 VCU_lock_ST "Indicating Vehicle Lock status";
CM_ SG_ 128 CRC "Message CRC";
CM_ SG_ 128 COUNTER "Message sequence number.";
CM_ SG_ 1861 XB_state "X-Boost state reported redundantly to DBC1280 over vehicle CAN";
CM_ SG_ 1861 XB_brake_pedal_applied_QF "Qualifier for the brake pedal applied signal";
CM_ SG_ 1861 XB_brake_pedal_applied "0: brake pedal not applied / 1: brake pedal applied / information about the driver attendance / For X-Boost correspond with 2 out of the 3 sensors indicating a brake pedal applied (For PCU and DBC as Redundant Private CAN signal)";
CM_ SG_ 1861 XB_brake_pedal_amp_QF "High/Medium/Low/Invalid";
CM_ SG_ 1861 XB_brake_pedal_amp "the normalized amplitude of the Brake Pedal application to support the unintended propulsion mitigation";
CM_ SG_ 1861 XB_base_brake_active_QF "Vehicle CAN usage + Private CAN signal redundancy";
CM_ SG_ 1861 XB_base_brake_active "Indicate a Base Brake activity induced by the driver or by an external brake request + Private CAN signal redundancy";
CM_ SG_ 1861 XB_BB_actual_amp_QF "3:High/2:Medium/1:Low/0:Invalid";
CM_ SG_ 1861 XB_BB_actual_amp "CBS reporting the normalized amplitude of Base Brake function to AERO";
CM_ SG_ 123 DBC_sec_BB_actual_amp_QF "High/Medium/Low/Invalid of FBM BB to AERO";
CM_ SG_ 123 DBC_sec_BB_actual_amp "CBS reporting the normalized amplitude of FBM base brake function to AERO";
CM_ SG_ 123 DBC_ST "DBC1280 state reported redundantly to X-Boost over vehicle CAN";
CM_ SG_ 123 DBC_sec_brake_pedal_applied_QF "brake pedal applied confirmation (qualifier)";
CM_ SG_ 123 DBC_sec_brake_pedal_applied "brake pedal applied confirmation by DBC to PCU";
CM_ SG_ 123 DBC_sec_brake_pedal_amp_QF "High/Medium/Low/Invalid";
CM_ SG_ 123 DBC_sec_brake_pedal_amp "normalized amplitude of the brake Pedal application to support the unintended propulsion mitigation";
CM_ SG_ 123 DBC_sec_base_brake_active_QF "0: Not initialized / 1: Valid / 2: Faulty (Private CAN signal Redundancy)";
CM_ SG_ 123 DBC_sec_base_brake_active "Associated with the foot on brake wakeUp + Private CAN signal Redundancy";
CM_ BO_ 948 "PDU diagnostic msg over UDS (Respond) for Slave 1";
CM_ BO_ 947 "PDU diagnostic msg over UDS (request) for Slave 1";
CM_ BO_ 1005 "PDU diagnostic msg over UDS (Respond) for Slave 2";
CM_ BO_ 949 "PDU diagnostic msg over UDS (request) for Slave 2";
CM_ BO_ 952 "PDU diagnostic msg over UDS (Respond) for Slave 3";
CM_ BO_ 951 "PDU diagnostic msg over UDS (request) for Slave 3";
CM_ BO_ 954 "PDU diagnostic msg over UDS (Respond) for Slave 4";
CM_ BO_ 953 "PDU diagnostic msg over UDS (request) for Slave 4";
CM_ BO_ 956 "PDU diagnostic msg over UDS (Respond) for Slave 5";
CM_ BO_ 955 "PDU diagnostic msg over UDS (request) for Slave 5";
CM_ BO_ 958 "PDU diagnostic msg over UDS (Respond) for Slave 6";
CM_ BO_ 957 "PDU diagnostic msg over UDS (request) for Slave 6";
CM_ BO_ 960 "PDU diagnostic msg over UDS (Respond) for Slave 7";
CM_ BO_ 959 "PDU diagnostic msg over UDS (request) for Slave 7";
CM_ BO_ 962 "PDU diagnostic msg over UDS (Respond) for Slave 8";
CM_ BO_ 961 "PDU diagnostic msg over UDS (request) for Slave 8";
CM_ BO_ 964 "PDU diagnostic msg over UDS (Respond) for Slave 9";
CM_ BO_ 963 "PDU diagnostic msg over UDS (request) for Slave 9";
CM_ BO_ 966 "PDU diagnostic msg over UDS (Respond) for Slave 10";
CM_ BO_ 965 "PDU diagnostic msg over UDS (request) for Slave 10";
CM_ BO_ 968 "PDU diagnostic msg over UDS (Respond) for Slave 11";
CM_ BO_ 967 "PDU diagnostic msg over UDS (request) for Slave 11";
CM_ BO_ 970 "PDU diagnostic msg over UDS (Respond) for Slave 12";
CM_ BO_ 969 "PDU diagnostic msg over UDS (request) for Slave 12";
CM_ BO_ 972 "PDU diagnostic msg over UDS (Respond) for Slave 13";
CM_ BO_ 971 "PDU diagnostic msg over UDS (request) for Slave 13";
CM_ BO_ 974 "PDU diagnostic msg over UDS (Respond) for Slave 14";
CM_ BO_ 973 "PDU diagnostic msg over UDS (request) for Slave 14";
CM_ BO_ 976 "PDU diagnostic msg over UDS (Respond) for Slave 15";
CM_ BO_ 975 "PDU diagnostic msg over UDS (request) for Slave 15";
CM_ BO_ 978 "PDU diagnostic msg over UDS (Respond) for Slave 16";
CM_ BO_ 977 "PDU diagnostic msg over UDS (request) for Slave 16";
CM_ BO_ 980 "PDU diagnostic msg over UDS (Respond) for Slave 17";
CM_ BO_ 979 "PDU diagnostic msg over UDS (request) for Slave 17";
CM_ BO_ 982 "PDU diagnostic msg over UDS (Respond) for Slave 18";
CM_ BO_ 981 "PDU diagnostic msg over UDS (request) for Slave 18";
CM_ BO_ 984 "PDU diagnostic msg over UDS (Respond) for Slave 19";
CM_ BO_ 983 "PDU diagnostic msg over UDS (request) for Slave 19";
CM_ BO_ 986 "PDU diagnostic msg over UDS (Respond) for Slave 20";
CM_ BO_ 985 "PDU diagnostic msg over UDS (request) for Slave 20";
CM_ BO_ 988 "PDU diagnostic msg over UDS (Respond) for Slave 21";
CM_ BO_ 987 "PDU diagnostic msg over UDS (request) for Slave 21";
CM_ BO_ 990 "PDU diagnostic msg over UDS (Respond) for Slave 22";
CM_ BO_ 989 "PDU diagnostic msg over UDS (request) for Slave 22";
CM_ BO_ 992 "PDU diagnostic msg over UDS (Respond) for Slave 23";
CM_ BO_ 991 "PDU diagnostic msg over UDS (request) for Slave 23";
CM_ BO_ 994 "PDU diagnostic msg over UDS (Respond) for Slave 24";
CM_ BO_ 993 "PDU diagnostic msg over UDS (request) for Slave 24";
CM_ BO_ 996 "PDU diagnostic msg over UDS (Respond) for Slave 25";
CM_ BO_ 995 "PDU diagnostic msg over UDS (request) for Slave 25";
CM_ BO_ 998 "PDU diagnostic msg over UDS (Respond) for Slave 26";
CM_ BO_ 997 "PDU diagnostic msg over UDS (request) for Slave 26";
CM_ BO_ 1000 "PDU diagnostic msg over UDS (Respond) for Slave 27";
CM_ BO_ 999 "PDU diagnostic msg over UDS (request) for Slave 27";
CM_ BO_ 1002 "PDU diagnostic msg over UDS (Respond) for Slave 28";
CM_ BO_ 1001 "PDU diagnostic msg over UDS (request) for Slave 28";
CM_ BO_ 1004 "PDU diagnostic msg over UDS (Respond) for Slave 29";
CM_ BO_ 1003 "PDU diagnostic msg over UDS (request) for Slave 29";
CM_ BO_ 299 "Safety Critical warnings.";
CM_ SG_ 299 PDM_F_adas_WARN "Notification to ADAS ECU that there is a problem with power supply.";
CM_ SG_ 299 PDM_F_dcdc_WARN "Notification to relevant ECUs that there is a problem with a DCDC power supply.";
CM_ SG_ 299 PDM_F_battery_WARN "Notification to relevant ECUs that there is a problem with a 12V Battery power supply.";
CM_ SG_ 299 PDM_F_soh_WARN "Notification to relevant ECUs that 12V Battery State of Health is too low.";
CM_ SG_ 299 COUNTER  "4-bit circular running counter.";
CM_ SG_ 299 CRC "8H2F Cyclic Redundancy Check";

CM_ BO_ 300 "Safety Critical redundant warnings.";
CM_ SG_ 300 PDM_F_adas_redn_WARN "Redundant notification to ADAS ECU that there is a problem with power supply.";
CM_ SG_ 300 PDM_F_dcdc_redn_WARN "Redundant notification to relevant ECUs that there is a problem with a DCDC power supply.";
CM_ SG_ 300 PDM_F_battery_redn_WARN "Redundant notification to relevant ECUs that there is a problem with a 12V Battery power supply.";
CM_ SG_ 300 PDM_F_soh_redn_WARN "Redundant notification to relevant ECUs that 12V Battery State of Health is too low.";
CM_ SG_ 300 COUNTER  "4-bit circular running counter.";
CM_ SG_ 300 CRC "8H2F Cyclic Redundancy Check";

CM_ BO_ 306 "Safety Critical warnings.";
CM_ SG_ 306 PDM_R_adas_WARN "Notification to ADAS ECU that there is a problem with power supply.";
CM_ SG_ 306 PDM_R_dcdc_WARN "Notification to relevant ECUs that there is a problem with a DCDC power supply.";
CM_ SG_ 306 PDM_R_battery_WARN "Notification to relevant ECUs that there is a problem with a 12V Battery power supply.";
CM_ SG_ 306 PDM_R_soh_WARN "Notification to relevant ECUs that 12V Battery State of Health is too low.";
CM_ SG_ 306 COUNTER  "4-bit circular running counter.";
CM_ SG_ 306 CRC "8H2F Cyclic Redundancy Check";

CM_ BO_ 307 "Safety Critical redundant warnings.";
CM_ SG_ 307 PDM_R_adas_redn_WARN "Redundant notification to ADAS ECU that there is a problem with power supply.";
CM_ SG_ 307 PDM_R_dcdc_redn_WARN "Redundant notification to relevant ECUs that there is a problem with a DCDC power supply.";
CM_ SG_ 307 PDM_R_battery_redn_WARN "Redundant notification to relevant ECUs that there is a problem with a 12V Battery power supply.";
CM_ SG_ 307 PDM_R_soh_redn_WARN "Redundant notification to relevant ECUs that 12V Battery State of Health is too low.";
CM_ SG_ 307 COUNTER  "4-bit circular running counter.";
CM_ SG_ 307 CRC "8H2F Cyclic Redundancy Check";

BA_DEF_ SG_  "SigType" ENUM  "Default","Range","RangeSigned","ASCII","Discrete","Control","ReferencePGN","DTC","StringDelimiter","StringLength","StringLengthControl","PayloadCRC","PayloadCounter";
BA_DEF_ SG_  "GenSigEVName" STRING ;
BA_DEF_ SG_  "GenSigILSupport" ENUM  "Yes","No";
BA_DEF_ SG_  "GenSigSendType" ENUM  "Cyclic","OnWrite","OnWriteWithRepetition","OnChange","OnChangeWithRepetition","IfActive","IfActiveWithRepetition","NoSigSendType";
BA_DEF_ SG_  "GenSigStartValue" INT 0 10000;
BA_DEF_ BO_  "GenMsgDelayTime" INT 0 1000;
BA_DEF_ BO_  "GenMsgILSupport" ENUM  "Yes","No";
BA_DEF_ BO_  "GenMsgStartDelayTime" INT 0 100000;
BA_DEF_ BU_  "NodeLayerModules" STRING ;
BA_DEF_ BU_  "NmStationAddress" INT 0 255;
BA_DEF_ BO_  "GenMsgSendType" ENUM  "Cyclic","SendOnRequest","CyclicIfActive","SendOnRequestWithDelay","CyclicAndSendOnRequest","CyclicAndSendOnRequestWithDelay","IfActive","NoMsgSendType";
BA_DEF_ BO_  "GenMsgRequestable" INT 0 1;
BA_DEF_ BO_  "GenMsgCycleTime" INT 0 3600000;
BA_DEF_ SG_  "GenSigInactiveValue" INT 0 0;
BA_DEF_ BU_  "ILUsed" ENUM  "Yes","No";
BA_DEF_ BO_  "GenMsgNrOfRepetition" INT 0 999999;
BA_DEF_ BO_  "GenMsgCycleTimeFast" INT 2 100000;
BA_DEF_ BO_  "GenMsgPayloadProtected" ENUM "NotProtected","Protected";
BA_DEF_ BO_  "GenMsgPayloadProtectionCRC" ENUM "CRC_ALGORITHM_NOT_USED","CRC_ALGORITHM_8_BIT_J1850","CRC_ALGORITHM_8_BIT_8H2F";
BA_DEF_  "DBName" STRING ;
BA_DEF_  "Baudrate" INT 0 1000000;
BA_DEF_  "BusType" STRING ;
BA_DEF_  "ProtocolType" STRING ;
BA_DEF_DEF_  "SigType" "Default";
BA_DEF_DEF_  "GenSigEVName" "Env@Nodename_@Signame";
BA_DEF_DEF_  "GenSigILSupport" "Yes";
BA_DEF_DEF_  "GenSigSendType" "Cyclic";
BA_DEF_DEF_  "GenSigStartValue" 0;
BA_DEF_DEF_  "GenMsgDelayTime" 1;
BA_DEF_DEF_  "GenMsgILSupport" "Yes";
BA_DEF_DEF_  "GenMsgStartDelayTime" 0;
BA_DEF_DEF_  "NodeLayerModules" "CANoeILNLVector.dll";
BA_DEF_DEF_  "NmStationAddress" 254;
BA_DEF_DEF_  "GenMsgSendType" "Cyclic";
BA_DEF_DEF_  "GenMsgRequestable" 1;
BA_DEF_DEF_  "GenMsgCycleTime" 100;
BA_DEF_DEF_  "GenSigInactiveValue" 0;
BA_DEF_DEF_  "ILUsed" "Yes";
BA_DEF_DEF_  "GenMsgNrOfRepetition" 0;
BA_DEF_DEF_  "GenMsgCycleTimeFast" 100;
BA_DEF_DEF_  "DBName" "";
BA_DEF_DEF_  "Baudrate" 500000;
BA_DEF_DEF_  "BusType" "";
BA_DEF_DEF_  "ProtocolType" "J1939";
BA_DEF_DEF_  "GenMsgPayloadProtected" "NotProtected";
BA_DEF_DEF_  "GenMsgPayloadProtectionCRC" "CRC_ALGORITHM_NOT_USED";
BA_ "BusType" "CAN";
BA_ "ProtocolType" "";
BA_ "DBName" "C2_Body";

BA_ "GenMsgCycleTime" BO_ 299 50;
BA_ "SigType" SG_ 299 CRC 11;
BA_ "SigType" SG_ 299 COUNTER 12;
BA_ "GenMsgPayloadProtected" BO_ 299 1;
BA_ "GenMsgPayloadProtectionCRC" BO_ 299 2;
BA_ "GenMsgCycleTime" BO_ 300 50;
BA_ "SigType" SG_ 300 CRC 11;
BA_ "SigType" SG_ 300 COUNTER 12;
BA_ "GenMsgPayloadProtected" BO_ 300 1;
BA_ "GenMsgPayloadProtectionCRC" BO_ 300 2;
BA_ "GenMsgCycleTime" BO_ 306 50;
BA_ "SigType" SG_ 306 CRC 11;
BA_ "SigType" SG_ 306 COUNTER 12;
BA_ "GenMsgPayloadProtected" BO_ 306 1;
BA_ "GenMsgPayloadProtectionCRC" BO_ 306 2;
BA_ "GenMsgCycleTime" BO_ 307 50;
BA_ "SigType" SG_ 307 CRC 11;
BA_ "SigType" SG_ 307 COUNTER 12;
BA_ "GenMsgPayloadProtected" BO_ 307 1;
BA_ "GenMsgPayloadProtectionCRC" BO_ 307 2;
BA_ "NmStationAddress" BU_ OFFCAR_SSCU 241;
BA_ "GenMsgNrOfRepetition" BO_ 320 5;
BA_ "GenMsgSendType" BO_ 320 6;
BA_ "GenMsgCycleTime" BO_ 2029 0;
BA_ "GenMsgCycleTime" BO_ 156 50;
BA_ "GenMsgCycleTime" BO_ 157 50;
BA_ "GenMsgCycleTime" BO_ 158 50;
BA_ "GenMsgCycleTime" BO_ 144 50;
BA_ "GenSigInactiveValue" SG_ 144 PCU_PT_front_knob_limit 127;
BA_ "GenSigInactiveValue" SG_ 144 PCU_PT_rear_knob_limit 127;
BA_ "GenMsgSendType" BO_ 2029 1;
BA_ "GenMsgSendType" BO_ 265 1;
BA_ "GenMsgCycleTime" BO_ 265 0;
BA_ "GenMsgCycleTime" BO_ 1048 1000;
BA_ "GenMsgCycleTime" BO_ 1584 0;
BA_ "GenMsgSendType" BO_ 1584 1;
BA_ "GenMsgCycleTime" BO_ 1585 0;
BA_ "GenMsgSendType" BO_ 1585 1;
BA_ "GenMsgCycleTime" BO_ 1586 0;
BA_ "GenMsgSendType" BO_ 1586 1;
BA_ "GenMsgCycleTime" BO_ 1587 0;
BA_ "GenMsgSendType" BO_ 1587 1;
BA_ "GenMsgCycleTime" BO_ 2028 0;
BA_ "GenMsgSendType" BO_ 2028 1;
BA_ "GenMsgCycleTime" BO_ 2027 0;
BA_ "GenMsgSendType" BO_ 2027 1;
BA_ "GenMsgCycleTime" BO_ 2026 0;
BA_ "GenMsgSendType" BO_ 2026 1;
BA_ "GenMsgCycleTime" BO_ 2025 0;
BA_ "GenMsgSendType" BO_ 2025 1;
BA_ "GenMsgCycleTime" BO_ 2024 0;
BA_ "GenMsgSendType" BO_ 2024 1;
BA_ "GenMsgCycleTime" BO_ 2009 0;
BA_ "GenMsgSendType" BO_ 2009 1;
BA_ "GenMsgCycleTime" BO_ 2008 0;
BA_ "GenMsgSendType" BO_ 2008 1;
BA_ "GenMsgCycleTime" BO_ 2003 0;
BA_ "GenMsgSendType" BO_ 2003 1;
BA_ "GenMsgCycleTime" BO_ 2002 0;
BA_ "GenMsgSendType" BO_ 2002 1;
BA_ "GenMsgCycleTime" BO_ 2001 0;
BA_ "GenMsgSendType" BO_ 2001 1;
BA_ "GenMsgCycleTime" BO_ 2000 0;
BA_ "GenMsgSendType" BO_ 2000 1;
BA_ "GenMsgCycleTime" BO_ 1998 0;
BA_ "GenMsgSendType" BO_ 1998 1;
BA_ "GenMsgCycleTime" BO_ 1999 0;
BA_ "GenMsgSendType" BO_ 1999 1;
BA_ "GenMsgCycleTime" BO_ 1997 0;
BA_ "GenMsgSendType" BO_ 1997 1;
BA_ "GenMsgCycleTime" BO_ 1996 0;
BA_ "GenMsgSendType" BO_ 1996 1;
BA_ "GenMsgCycleTime" BO_ 1995 0;
BA_ "GenMsgSendType" BO_ 1995 1;
BA_ "GenMsgCycleTime" BO_ 1994 0;
BA_ "GenMsgSendType" BO_ 1994 1;
BA_ "GenMsgCycleTime" BO_ 1993 0;
BA_ "GenMsgSendType" BO_ 1993 1;
BA_ "GenMsgCycleTime" BO_ 1992 0;
BA_ "GenMsgSendType" BO_ 1992 1;
BA_ "GenMsgCycleTime" BO_ 1991 0;
BA_ "GenMsgSendType" BO_ 1991 1;
BA_ "GenMsgCycleTime" BO_ 1990 0;
BA_ "GenMsgSendType" BO_ 1990 1;
BA_ "GenMsgCycleTime" BO_ 1989 0;
BA_ "GenMsgSendType" BO_ 1989 1;
BA_ "GenMsgCycleTime" BO_ 1988 0;
BA_ "GenMsgSendType" BO_ 1988 1;
BA_ "GenMsgCycleTime" BO_ 1987 0;
BA_ "GenMsgSendType" BO_ 1987 1;
BA_ "GenMsgCycleTime" BO_ 1986 0;
BA_ "GenMsgSendType" BO_ 1986 1;
BA_ "GenMsgCycleTime" BO_ 1985 0;
BA_ "GenMsgSendType" BO_ 1985 1;
BA_ "GenMsgCycleTime" BO_ 1984 0;
BA_ "GenMsgSendType" BO_ 1984 1;
BA_ "GenMsgCycleTime" BO_ 1977 0;
BA_ "GenMsgSendType" BO_ 1977 1;
BA_ "GenMsgCycleTime" BO_ 1976 0;
BA_ "GenMsgSendType" BO_ 1976 1;
BA_ "GenMsgCycleTime" BO_ 1975 0;
BA_ "GenMsgSendType" BO_ 1975 1;
BA_ "GenMsgCycleTime" BO_ 1983 0;
BA_ "GenMsgSendType" BO_ 1983 1;
BA_ "GenMsgCycleTime" BO_ 1973 0;
BA_ "GenMsgSendType" BO_ 1973 1;
BA_ "GenMsgCycleTime" BO_ 1972 0;
BA_ "GenMsgSendType" BO_ 1972 1;
BA_ "GenMsgCycleTime" BO_ 1971 0;
BA_ "GenMsgSendType" BO_ 1971 1;
BA_ "GenMsgCycleTime" BO_ 1970 0;
BA_ "GenMsgSendType" BO_ 1970 1;
BA_ "GenMsgCycleTime" BO_ 1955 0;
BA_ "GenMsgSendType" BO_ 1955 1;
BA_ "GenMsgCycleTime" BO_ 1954 0;
BA_ "GenMsgSendType" BO_ 1954 1;
BA_ "GenMsgCycleTime" BO_ 1953 0;
BA_ "GenMsgSendType" BO_ 1953 1;
BA_ "GenMsgCycleTime" BO_ 1952 0;
BA_ "GenMsgSendType" BO_ 1952 1;
BA_ "GenMsgCycleTime" BO_ 1939 0;
BA_ "GenMsgSendType" BO_ 1939 1;
BA_ "GenMsgCycleTime" BO_ 1938 0;
BA_ "GenMsgSendType" BO_ 1938 1;
BA_ "GenMsgCycleTime" BO_ 1927 0;
BA_ "GenMsgSendType" BO_ 1927 1;
BA_ "GenMsgCycleTime" BO_ 1926 0;
BA_ "GenMsgSendType" BO_ 1926 1;
BA_ "GenMsgCycleTime" BO_ 1925 0;
BA_ "GenMsgSendType" BO_ 1925 1;
BA_ "GenMsgCycleTime" BO_ 1924 0;
BA_ "GenMsgSendType" BO_ 1924 1;
BA_ "GenMsgCycleTime" BO_ 1923 0;
BA_ "GenMsgSendType" BO_ 1923 1;
BA_ "GenMsgCycleTime" BO_ 1922 0;
BA_ "GenMsgSendType" BO_ 1922 1;
BA_ "GenMsgCycleTime" BO_ 1921 0;
BA_ "GenMsgSendType" BO_ 1921 1;
BA_ "GenMsgCycleTime" BO_ 1920 0;
BA_ "GenMsgSendType" BO_ 1920 1;
BA_ "GenMsgCycleTime" BO_ 1792 0;
BA_ "GenMsgSendType" BO_ 1792 1;
BA_ "GenMsgCycleTime" BO_ 2033 0;
BA_ "GenMsgSendType" BO_ 2033 1;
BA_ "GenMsgCycleTime" BO_ 1813 0;
BA_ "GenMsgSendType" BO_ 1813 1;
BA_ "GenMsgCycleTime" BO_ 2041 0;
BA_ "GenMsgSendType" BO_ 2041 1;
BA_ "GenMsgCycleTime" BO_ 1919 0;
BA_ "GenMsgSendType" BO_ 1919 1;
BA_ "GenMsgDelayTime" BO_ 1919 90;
BA_ "GenMsgSendType" BO_ 80 4;
BA_ "GenMsgCycleTime" BO_ 533 200;
BA_ "GenMsgCycleTime" BO_ 1024 1000;
BA_ "GenMsgCycleTime" BO_ 523 1000;
BA_ "GenMsgCycleTime" BO_ 1155 0;
BA_ "GenMsgSendType" BO_ 1155 1;
BA_ "GenMsgCycleTime" BO_ 1154 0;
BA_ "GenMsgSendType" BO_ 1154 1;
BA_ "GenMsgCycleTime" BO_ 947 0;
BA_ "GenMsgSendType" BO_ 947 1;
BA_ "GenMsgCycleTime" BO_ 948 0;
BA_ "GenMsgSendType" BO_ 948 1;
BA_ "GenMsgCycleTime" BO_ 949 0;
BA_ "GenMsgSendType" BO_ 949 1;
BA_ "GenMsgCycleTime" BO_ 1005 0;
BA_ "GenMsgSendType" BO_ 1005 1;
BA_ "GenMsgCycleTime" BO_ 951 0;
BA_ "GenMsgSendType" BO_ 951 1;
BA_ "GenMsgCycleTime" BO_ 952 0;
BA_ "GenMsgSendType" BO_ 952 1;
BA_ "GenMsgCycleTime" BO_ 953 0;
BA_ "GenMsgSendType" BO_ 953 1;
BA_ "GenMsgCycleTime" BO_ 954 0;
BA_ "GenMsgSendType" BO_ 954 1;
BA_ "GenMsgCycleTime" BO_ 955 0;
BA_ "GenMsgSendType" BO_ 955 1;
BA_ "GenMsgCycleTime" BO_ 956 0;
BA_ "GenMsgSendType" BO_ 956 1;
BA_ "GenMsgCycleTime" BO_ 957 0;
BA_ "GenMsgSendType" BO_ 957 1;
BA_ "GenMsgCycleTime" BO_ 958 0;
BA_ "GenMsgSendType" BO_ 958 1;
BA_ "GenMsgCycleTime" BO_ 959 0;
BA_ "GenMsgSendType" BO_ 959 1;
BA_ "GenMsgCycleTime" BO_ 960 0;
BA_ "GenMsgSendType" BO_ 960 1;
BA_ "GenMsgCycleTime" BO_ 961 0;
BA_ "GenMsgSendType" BO_ 961 1;
BA_ "GenMsgCycleTime" BO_ 962 0;
BA_ "GenMsgSendType" BO_ 962 1;
BA_ "GenMsgCycleTime" BO_ 963 0;
BA_ "GenMsgSendType" BO_ 963 1;
BA_ "GenMsgCycleTime" BO_ 964 0;
BA_ "GenMsgSendType" BO_ 964 1;
BA_ "GenMsgCycleTime" BO_ 965 0;
BA_ "GenMsgSendType" BO_ 965 1;
BA_ "GenMsgCycleTime" BO_ 966 0;
BA_ "GenMsgSendType" BO_ 966 1;
BA_ "GenMsgCycleTime" BO_ 967 0;
BA_ "GenMsgSendType" BO_ 967 1;
BA_ "GenMsgCycleTime" BO_ 968 0;
BA_ "GenMsgSendType" BO_ 968 1;
BA_ "GenMsgCycleTime" BO_ 969 0;
BA_ "GenMsgSendType" BO_ 969 1;
BA_ "GenMsgCycleTime" BO_ 970 0;
BA_ "GenMsgSendType" BO_ 970 1;
BA_ "GenMsgCycleTime" BO_ 971 0;
BA_ "GenMsgSendType" BO_ 971 1;
BA_ "GenMsgCycleTime" BO_ 972 0;
BA_ "GenMsgSendType" BO_ 972 1;
BA_ "GenMsgCycleTime" BO_ 973 0;
BA_ "GenMsgSendType" BO_ 973 1;
BA_ "GenMsgCycleTime" BO_ 974 0;
BA_ "GenMsgSendType" BO_ 974 1;
BA_ "GenMsgCycleTime" BO_ 975 0;
BA_ "GenMsgSendType" BO_ 975 1;
BA_ "GenMsgCycleTime" BO_ 976 0;
BA_ "GenMsgSendType" BO_ 976 1;
BA_ "GenMsgCycleTime" BO_ 977 0;
BA_ "GenMsgSendType" BO_ 977 1;
BA_ "GenMsgCycleTime" BO_ 978 0;
BA_ "GenMsgSendType" BO_ 978 1;
BA_ "GenMsgCycleTime" BO_ 979 0;
BA_ "GenMsgSendType" BO_ 979 1;
BA_ "GenMsgCycleTime" BO_ 980 0;
BA_ "GenMsgSendType" BO_ 980 1;
BA_ "GenMsgCycleTime" BO_ 981 0;
BA_ "GenMsgSendType" BO_ 981 1;
BA_ "GenMsgCycleTime" BO_ 982 0;
BA_ "GenMsgSendType" BO_ 982 1;
BA_ "GenMsgCycleTime" BO_ 983 0;
BA_ "GenMsgSendType" BO_ 983 1;
BA_ "GenMsgCycleTime" BO_ 984 0;
BA_ "GenMsgSendType" BO_ 984 1;
BA_ "GenMsgCycleTime" BO_ 985 0;
BA_ "GenMsgSendType" BO_ 985 1;
BA_ "GenMsgCycleTime" BO_ 986 0;
BA_ "GenMsgSendType" BO_ 986 1;
BA_ "GenMsgCycleTime" BO_ 987 0;
BA_ "GenMsgSendType" BO_ 987 1;
BA_ "GenMsgCycleTime" BO_ 988 0;
BA_ "GenMsgSendType" BO_ 988 1;
BA_ "GenMsgCycleTime" BO_ 989 0;
BA_ "GenMsgSendType" BO_ 989 1;
BA_ "GenMsgCycleTime" BO_ 990 0;
BA_ "GenMsgSendType" BO_ 990 1;
BA_ "GenMsgCycleTime" BO_ 991 0;
BA_ "GenMsgSendType" BO_ 991 1;
BA_ "GenMsgCycleTime" BO_ 992 0;
BA_ "GenMsgSendType" BO_ 992 1;
BA_ "GenMsgCycleTime" BO_ 993 0;
BA_ "GenMsgSendType" BO_ 993 1;
BA_ "GenMsgCycleTime" BO_ 994 0;
BA_ "GenMsgSendType" BO_ 994 1;
BA_ "GenMsgCycleTime" BO_ 995 0;
BA_ "GenMsgSendType" BO_ 995 1;
BA_ "GenMsgCycleTime" BO_ 996 0;
BA_ "GenMsgSendType" BO_ 996 1;
BA_ "GenMsgCycleTime" BO_ 997 0;
BA_ "GenMsgSendType" BO_ 997 1;
BA_ "GenMsgCycleTime" BO_ 998 0;
BA_ "GenMsgSendType" BO_ 998 1;
BA_ "GenMsgCycleTime" BO_ 999 0;
BA_ "GenMsgSendType" BO_ 999 1;
BA_ "GenMsgCycleTime" BO_ 1000 0;
BA_ "GenMsgSendType" BO_ 1000 1;
BA_ "GenMsgCycleTime" BO_ 1001 0;
BA_ "GenMsgSendType" BO_ 1001 1;
BA_ "GenMsgCycleTime" BO_ 1002 0;
BA_ "GenMsgSendType" BO_ 1002 1;
BA_ "GenMsgCycleTime" BO_ 1003 0;
BA_ "GenMsgSendType" BO_ 1003 1;
BA_ "GenMsgCycleTime" BO_ 1004 0;
BA_ "GenMsgSendType" BO_ 1004 1;
BA_ "GenSigInactiveValue" SG_ 157 IVI_driving_mode_REQ 15;
BA_ "GenSigInactiveValue" SG_ 157 IVI_stability_mode_REQ 7;
BA_ "GenSigInactiveValue" SG_ 156 IVI_throttle_response_REQ 3;
BA_ "GenSigInactiveValue" SG_ 156 IVI_suspension_stiffness_REQ 3;
BA_ "GenSigInactiveValue" SG_ 156 IVI_steering_assistance_REQ 3;
BA_ "GenSigInactiveValue" SG_ 156 IVI_active_aero_setup_REQ 4;
BA_ "GenSigInactiveValue" SG_ 156 IVI_regen_off_throttle_REQ 3;
BA_ "GenSigInactiveValue" SG_ 156 IVI_save_to_custom_REQ 3;
BA_ "GenSigInactiveValue" SG_ 156 IVI_creep_REQ 2;
BA_ "GenMsgCycleTime" BO_ 1294 200;
BA_ "GenMsgCycleTime" BO_ 779 20;
BA_ "GenMsgCycleTime" BO_ 1319 0;
BA_ "GenMsgSendType" BO_ 1319 6;
BA_ "GenMsgCycleTime" BO_ 2032 0;
BA_ "GenMsgSendType" BO_ 2032 1;
BA_ "GenMsgCycleTime" BO_ 1579 0;
BA_ "GenMsgSendType" BO_ 1579 1;
BA_ "GenMsgCycleTime" BO_ 1578 0;
BA_ "GenMsgSendType" BO_ 1578 1;
BA_ "GenMsgCycleTime" BO_ 1573 0;
BA_ "GenMsgSendType" BO_ 1573 1;
BA_ "GenMsgCycleTime" BO_ 1572 0;
BA_ "GenMsgSendType" BO_ 1572 1;
BA_ "GenMsgCycleTime" BO_ 1571 0;
BA_ "GenMsgSendType" BO_ 1571 1;
BA_ "GenMsgCycleTime" BO_ 1570 0;
BA_ "GenMsgSendType" BO_ 1570 1;
BA_ "GenMsgCycleTime" BO_ 1565 0;
BA_ "GenMsgSendType" BO_ 1565 1;
BA_ "GenMsgCycleTime" BO_ 1566 0;
BA_ "GenMsgSendType" BO_ 1566 1;
BA_ "GenMsgCycleTime" BO_ 1563 0;
BA_ "GenMsgSendType" BO_ 1563 1;
BA_ "GenMsgCycleTime" BO_ 1562 0;
BA_ "GenMsgSendType" BO_ 1562 1;
BA_ "GenMsgCycleTime" BO_ 1561 0;
BA_ "GenMsgSendType" BO_ 1561 1;
BA_ "GenMsgCycleTime" BO_ 1560 0;
BA_ "GenMsgSendType" BO_ 1560 1;
BA_ "GenMsgCycleTime" BO_ 1555 0;
BA_ "GenMsgSendType" BO_ 1555 1;
BA_ "GenMsgCycleTime" BO_ 1554 0;
BA_ "GenMsgSendType" BO_ 1554 1;
BA_ "GenMsgCycleTime" BO_ 1553 0;
BA_ "GenMsgSendType" BO_ 1553 1;
BA_ "GenMsgCycleTime" BO_ 1552 0;
BA_ "GenMsgSendType" BO_ 1552 1;
BA_ "GenMsgCycleTime" BO_ 1539 0;
BA_ "GenMsgSendType" BO_ 1539 1;
BA_ "GenMsgCycleTime" BO_ 1538 0;
BA_ "GenMsgSendType" BO_ 1538 1;
BA_ "GenMsgCycleTime" BO_ 1537 0;
BA_ "GenMsgSendType" BO_ 1537 1;
BA_ "GenMsgCycleTime" BO_ 1536 0;
BA_ "GenMsgSendType" BO_ 1536 1;
BA_ "GenMsgCycleTime" BO_ 127 10;
BA_ "GenMsgCycleTime" BO_ 803 0;
BA_ "GenMsgSendType" BO_ 803 6;
BA_ "GenMsgCycleTime" BO_ 1153 0;
BA_ "GenMsgSendType" BO_ 1153 1;
BA_ "GenMsgCycleTime" BO_ 1152 0;
BA_ "GenMsgSendType" BO_ 1152 1;
BA_ "GenMsgSendType" BO_ 1318 6;
BA_ "GenMsgCycleTime" BO_ 1318 0;
BA_ "GenMsgSendType" BO_ 1317 6;
BA_ "GenMsgCycleTime" BO_ 1317 0;
BA_ "GenMsgSendType" BO_ 1316 6;
BA_ "GenMsgCycleTime" BO_ 1316 0;
BA_ "GenMsgSendType" BO_ 1315 6;
BA_ "GenMsgCycleTime" BO_ 1315 0;
BA_ "GenMsgCycleTime" BO_ 1041 1000;
BA_ "GenMsgCycleTime" BO_ 802 300;
BA_ "GenMsgCycleTime" BO_ 1112 0;
BA_ "GenMsgSendType" BO_ 1112 1;
BA_ "GenMsgCycleTime" BO_ 1113 0;
BA_ "GenMsgSendType" BO_ 1113 1;
BA_ "GenMsgCycleTime" BO_ 1111 0;
BA_ "GenMsgSendType" BO_ 1111 1;
BA_ "GenMsgCycleTime" BO_ 1110 0;
BA_ "GenMsgSendType" BO_ 1110 1;
BA_ "GenMsgCycleTime" BO_ 1121 0;
BA_ "GenMsgSendType" BO_ 1121 1;
BA_ "GenMsgCycleTime" BO_ 1120 0;
BA_ "GenMsgSendType" BO_ 1120 1;
BA_ "GenMsgCycleTime" BO_ 1117 0;
BA_ "GenMsgSendType" BO_ 1117 1;
BA_ "GenMsgCycleTime" BO_ 1116 0;
BA_ "GenMsgSendType" BO_ 1116 1;
BA_ "GenMsgCycleTime" BO_ 1109 0;
BA_ "GenMsgSendType" BO_ 1109 1;
BA_ "GenMsgCycleTime" BO_ 1107 0;
BA_ "GenMsgSendType" BO_ 1107 1;
BA_ "GenMsgCycleTime" BO_ 1108 0;
BA_ "GenMsgSendType" BO_ 1108 1;
BA_ "GenMsgCycleTime" BO_ 1106 0;
BA_ "GenMsgSendType" BO_ 1106 1;
BA_ "GenMsgCycleTime" BO_ 1150 0;
BA_ "GenMsgSendType" BO_ 1150 1;
BA_ "GenMsgCycleTime" BO_ 1151 0;
BA_ "GenMsgSendType" BO_ 1151 1;
BA_ "GenMsgCycleTime" BO_ 1119 0;
BA_ "GenMsgSendType" BO_ 1119 1;
BA_ "GenMsgCycleTime" BO_ 1118 0;
BA_ "GenMsgSendType" BO_ 1118 1;
BA_ "GenMsgCycleTime" BO_ 1115 0;
BA_ "GenMsgSendType" BO_ 1115 1;
BA_ "GenMsgCycleTime" BO_ 1114 0;
BA_ "GenMsgSendType" BO_ 1114 1;
BA_ "GenMsgSendType" BO_ 768 4;
BA_ "GenMsgNrOfRepetition" BO_ 768 5;
BA_ "GenMsgCycleTime" BO_ 1045 1000;
BA_ "GenMsgCycleTime" BO_ 1032 1000;
BA_ "GenMsgCycleTime" BO_ 1033 1000;
BA_ "GenMsgCycleTime" BO_ 1047 1000;
BA_ "GenMsgCycleTime" BO_ 1042 1000;
BA_ "GenMsgCycleTime" BO_ 1036 1000;
BA_ "GenMsgCycleTime" BO_ 1025 1000;
BA_ "GenMsgCycleTime" BO_ 1023 1000;
BA_ "GenMsgCycleTime" BO_ 1038 1000;
BA_ "GenMsgCycleTime" BO_ 1037 1000;
BA_ "GenMsgSendType" BO_ 776 4;
BA_ "GenMsgSendType" BO_ 777 4;
BA_ "GenMsgNrOfRepetition" BO_ 777 5;
BA_ "GenMsgCycleTime" BO_ 409 150;
BA_ "GenMsgCycleTime" BO_ 137 200;
BA_ "GenMsgCycleTime" BO_ 140 10;
BA_ "GenMsgCycleTime" BO_ 1353 200;
BA_ "GenMsgCycleTime" BO_ 1821 10;
BA_ "GenMsgCycleTime" BO_ 1822 10;
BA_ "GenMsgCycleTime" BO_ 1823 10;
BA_ "GenMsgCycleTimeFast" BO_ 848 10;
BA_ "GenMsgSendType" BO_ 848 4;
BA_ "GenMsgCycleTime" BO_ 848 50;
BA_ "GenMsgCycleTime" BO_ 1351 200;
BA_ "GenMsgCycleTime" BO_ 772 200;
BA_ "GenMsgSendType" BO_ 770 4;
BA_ "GenMsgNrOfRepetition" BO_ 770 5;
BA_ "GenMsgCycleTime" BO_ 771 200;
BA_ "GenMsgCycleTime" BO_ 530 300;
BA_ "GenMsgSendType" BO_ 263 4;
BA_ "GenMsgSendType" BO_ 264 4;
BA_ "GenMsgNrOfRepetition" BO_ 264 5;
BA_ "GenMsgSendType" BO_ 266 4;
BA_ "GenMsgNrOfRepetition" BO_ 266 5;
BA_ "GenMsgCycleTime" BO_ 529 300;
BA_ "GenMsgCycleTime" BO_ 513 400;
BA_ "GenMsgCycleTime" BO_ 111 200;
BA_ "GenSigStartValue" SG_ 2364475905 BCU_R_set_point_motor_speed_REQ 333;
BA_ "GenSigStartValue" SG_ 779 PCU_suspension_lvl_RR 125;
BA_ "GenSigStartValue" SG_ 779 PCU_suspension_lvl_RL 125;
BA_ "GenSigStartValue" SG_ 779 PCU_suspension_lvl_FR 125;
BA_ "GenSigStartValue" SG_ 779 PCU_suspension_lvl_FL 125;
BA_ "GenSigStartValue" SG_ 776 IVI_seat_Z_pos_REQ 127;
BA_ "GenSigStartValue" SG_ 776 IVI_seat_Y_pos_REQ 127;
BA_ "GenSigStartValue" SG_ 776 IVI_seat_X_pos_REQ 127;
BA_ "GenSigStartValue" SG_ 777 IVI_seat_Z_pos_REQ 127;
BA_ "GenSigStartValue" SG_ 777 IVI_seat_Y_pos_REQ 127;
BA_ "GenSigStartValue" SG_ 777 IVI_seat_X_pos_REQ 127;
BA_ "GenSigStartValue" SG_ 768 IVI_AC_temp_CTRL 140;
BA_ "GenSigStartValue" SG_ 768 IVI_charge_soc_LIM_CTRL 90;
BA_ "GenSigStartValue" SG_ 768 IVI_charge_current_LIM_CTRL 32;
BA_ "GenSigStartValue" SG_ 1353 BCU_R_Hpump_temp 40;
BA_ "GenSigStartValue" SG_ 513 SCU_PSG_airbag_activate_REQ 1;
BA_ "GenSigStartValue" SG_ 256 EPS_steering_wheel_angle 7800;
BA_ "GenMsgNrOfRepetition" BO_ 524 5;
BA_ "GenMsgSendType" BO_ 524 4;
BA_ "GenSigStartValue" SG_ 524 IVI_red_REQ 255;
BA_ "GenSigStartValue" SG_ 524 IVI_green_REQ 255;
BA_ "GenSigStartValue" SG_ 524 IVI_blue_REQ 255;
BA_ "GenSigStartValue" SG_ 524 IVI_white_red_REQ 255;
BA_ "GenSigStartValue" SG_ 524 IVI_white_green_REQ 255;
BA_ "GenSigStartValue" SG_ 524 IVI_white_blue_REQ 255;
BA_ "GenSigStartValue" SG_ 263 IVI_mirror_X_pos_REQ 127;
BA_ "GenSigStartValue" SG_ 263 IVI_mirror_Y_pos_REQ 127;
BA_ "GenSigStartValue" SG_ 264 IVI_mirror_X_pos_REQ 127;
BA_ "GenSigStartValue" SG_ 264 IVI_mirror_Y_pos_REQ 127;
BA_ "GenSigStartValue" SG_ 266 IVI_swcol_X_depth_pos_REQ 127;
BA_ "GenSigStartValue" SG_ 266 IVI_swcol_Y_height_pos_REQ 127;
BA_ "SigType" SG_ 1282 CRC 11;
BA_ "SigType" SG_ 1282 Counter 12;
BA_ "GenMsgPayloadProtected" BO_ 1282 1;
BA_ "GenMsgPayloadProtectionCRC" BO_ 1282 2;
BA_ "SigType" SG_ 1299 CRC 11;
BA_ "SigType" SG_ 1299 Counter 12;
BA_ "GenMsgPayloadProtected" BO_ 1299 1;
BA_ "GenMsgPayloadProtectionCRC" BO_ 1299 2;
BA_ "SigType" SG_ 1283 CRC 11;
BA_ "SigType" SG_ 1283 Counter 12;
BA_ "GenMsgPayloadProtected" BO_ 1283 1;
BA_ "GenMsgPayloadProtectionCRC" BO_ 1283 2;
BA_ "SigType" SG_ 1280 CRC 11;
BA_ "SigType" SG_ 1280 Counter 12;
BA_ "GenMsgPayloadProtected" BO_ 1280 1;
BA_ "GenMsgPayloadProtectionCRC" BO_ 1280 2;
BA_ "SigType" SG_ 1281 CRC 11;
BA_ "SigType" SG_ 1281 Counter 12;
BA_ "GenMsgPayloadProtected" BO_ 1281 1;
BA_ "GenMsgPayloadProtectionCRC" BO_ 1281 2;
BA_ "SigType" SG_ 1293 CRC 11;
BA_ "SigType" SG_ 1293 Counter 12;
BA_ "GenMsgPayloadProtected" BO_ 1293 1;
BA_ "GenMsgPayloadProtectionCRC" BO_ 1293 2;
BA_ "SigType" SG_ 1288 CRC 11;
BA_ "SigType" SG_ 1288 Counter 12;
BA_ "GenMsgPayloadProtected" BO_ 1288 1;
BA_ "GenMsgPayloadProtectionCRC" BO_ 1288 2;
BA_ "SigType" SG_ 1289 CRC 11;
BA_ "SigType" SG_ 1289 Counter 12;
BA_ "GenMsgPayloadProtected" BO_ 1289 1;
BA_ "GenMsgPayloadProtectionCRC" BO_ 1289 2;
BA_ "SigType" SG_ 1305 CRC 11;
BA_ "SigType" SG_ 1305 Counter 12;
BA_ "GenMsgPayloadProtected" BO_ 1305 1;
BA_ "GenMsgPayloadProtectionCRC" BO_ 1305 2;
BA_ "SigType" SG_ 1292 CRC 11;
BA_ "SigType" SG_ 1292 Counter 12;
BA_ "GenMsgPayloadProtected" BO_ 1292 1;
BA_ "GenMsgPayloadProtectionCRC" BO_ 1292 2;
BA_ "SigType" SG_ 409 CRC 11;
BA_ "SigType" SG_ 409 Counter 12;
BA_ "GenMsgPayloadProtected" BO_ 409 1;
BA_ "GenMsgPayloadProtectionCRC" BO_ 409 2;
BA_ "GenSigStartValue" SG_ 778 CCU_F_ambient_temp 100;
BA_ "GenMsgCycleTime" BO_ 291 10;
BA_ "GenMsgCycleTimeFast" BO_ 448 20;
BA_ "GenMsgNrOfRepetition" BO_ 448 3;
BA_ "GenMsgCycleTime" BO_ 448 200;
BA_ "GenMsgCycleTimeFast" BO_ 447 20;
BA_ "GenMsgNrOfRepetition" BO_ 447 3;
BA_ "GenMsgCycleTime" BO_ 447 200;
BA_ "GenMsgCycleTime" BO_ 1301 200;
BA_ "GenMsgCycleTimeFast" BO_ 1301 20;
BA_ "GenMsgCycleTime" BO_ 1302 200;
BA_ "GenMsgCycleTimeFast" BO_ 1302 20;
BA_ "GenMsgCycleTime" BO_ 1303 200;
BA_ "GenMsgCycleTimeFast" BO_ 1303 20;
BA_ "GenMsgCycleTime" BO_ 1304 200;
BA_ "GenMsgCycleTimeFast" BO_ 1304 20;
BA_ "GenMsgSendType" BO_ 1806 1;
BA_ "GenMsgCycleTime" BO_ 1806 0;
BA_ "GenMsgSendType" BO_ 1807 1;
BA_ "GenMsgCycleTime" BO_ 1807 0;
BA_ "GenMsgSendType" BO_ 1804 1;
BA_ "GenMsgCycleTime" BO_ 1804 0;
BA_ "GenMsgSendType" BO_ 1805 1;
BA_ "GenMsgCycleTime" BO_ 1805 0;
BA_ "GenMsgSendType" BO_ 1802 1;
BA_ "GenMsgCycleTime" BO_ 1802 0;
BA_ "GenMsgSendType" BO_ 1803 1;
BA_ "GenMsgCycleTime" BO_ 1803 0;
BA_ "GenMsgSendType" BO_ 1800 1;
BA_ "GenMsgCycleTime" BO_ 1800 0;
BA_ "GenMsgSendType" BO_ 1801 1;
BA_ "GenMsgCycleTime" BO_ 1801 0;
BA_ "GenMsgCycleTime" BO_ 123 10;
BA_ "GenMsgCycleTime" BO_ 1861 10;
BA_ "GenSigSendType" SG_ 448 BCU_F_RHS_LED_DRIVE_3_REQ 4;
BA_ "GenSigSendType" SG_ 448 BCU_F_LHS_LED_DRIVE_3_REQ 4;
BA_ "GenSigSendType" SG_ 448 BCU_F_front_RH_OB_REQ 4;
BA_ "GenSigSendType" SG_ 448 BCU_F_front_RH_IB_REQ 4;
BA_ "GenSigSendType" SG_ 448 BCU_F_front_LH_OB_REQ 4;
BA_ "GenSigSendType" SG_ 448 BCU_F_front_LH_IB_REQ 4;
BA_ "GenSigSendType" SG_ 447 BCU_F_LHS_LED_DRIVE_4_REQ 4;
BA_ "GenSigSendType" SG_ 447 BCU_F_RHS_LED_DRIVE_4_REQ 4;
BA_ "GenSigSendType" SG_ 447 BCU_F_RHS_LED_DRIVE_1_2_REQ 4;
BA_ "GenSigSendType" SG_ 447 BCU_F_LHS_LED_DRIVE_1_2_REQ 4;
BA_ "GenSigSendType" SG_ 447 BCU_F_RH_mirror_DI_EN 4;
BA_ "GenSigSendType" SG_ 447 BCU_F_LH_mirror_DI_EN 4;
BA_ "GenSigSendType" SG_ 447 BCU_F_front_RH_DI_REQ 4;
BA_ "GenSigSendType" SG_ 447 BCU_F_front_LH_DI_REQ 4;
BA_ "GenMsgCycleTime" BO_ 128 20;

VAL_ 111 ADAS_ultrasonic_board_ON_REQ 1 "ON" 0 "OFF" ;
VAL_ 1353 BCU_R_ultrasonic_board_ST 1 "ON" 0 "OFF" ;
VAL_ 320 SSCU_rear_trunk_REQ 1 "Request" 0 "IDLE" ;
VAL_ 320 SSCU_vehicle_lock_unlock_REQ 1 "Request" 0 "IDLE" ;
VAL_ 320 SSCU_fog_light_REQ 1 "ON" 0 "OFF" ;
VAL_ 320 SSCU_window_PSG_REQ 4 "Request auto down" 3 "Request down" 2 "Request auto up" 1 "Request up" 0 "IDLE" ;
VAL_ 320 SSCU_max_demist_REQ 1 "Request" 0 "IDLE" ;
VAL_ 320 SSCU_window_DRV_REQ 4 "Request auto down" 3 "Request down" 2 "Request auto up" 1 "Request up" 0 "IDLE" ;
VAL_ 1861 XB_brake_pedal_amp_QF 3 "High" 2 "Medium" 1 "Low" 0 "Invalid";
VAL_ 1861 XB_brake_pedal_applied 1 "Applied" 0 "Not applied";
VAL_ 1861 XB_base_brake_in_use 1 "True" 0 "False";
VAL_ 1861 XB_BB_actual_amp_QF 3 "High" 2 "Medium" 1 "Low" 0 "Invalid";
VAL_ 1861 XB_state 6 "SHUT_DOWN" 5 "UNKNOWN" 4 "ACTIVE" 3 "MANUAL_CONTROL" 2 "IDLE" 1 "INIT" 0 "OFF" ;
VAL_ 1861 XB_brake_pedal_applied_QF 2 "Faulty" 1 "Valid" 0 "Not Initialized";
VAL_ 1861 XB_base_brake_active_QF 2 "Faulty" 1 "Valid" 0 "Not Initialized";
VAL_ 1861 XB_base_brake_active 1 "Active" 0 "Inactive";
VAL_ 123 DBC_sec_BB_actual_amp_QF 3 "High" 2 "Medium" 1 "Low" 0 "Invalid" ;
VAL_ 123 DBC_sec_base_brake_active 1 "Active" 0 "Inactive";
VAL_ 123 DBC_sec_base_brake_active_QF 2 "Faulty" 1 "Valid" 0 "Not Initialized";
VAL_ 123 DBC_sec_brake_pedal_amp_QF 3 "High" 2 "Medium" 1 "Low" 0 "Invalid";
VAL_ 123 DBC_sec_brake_pedal_applied 1 "Active" 0 "Inactive";
VAL_ 123 DBC_sec_base_brake_in_use 1 "True" 0 "False";
VAL_ 123 DBC_ST 12 "Shutdown" 11 "Pre_shutdown" 10 "System_suspended" 9 "Nvm_processing" 8 "Ram_download" 7 "Device_ctrl" 6 "State_DVT" 5 "Fault_pwr_off" 3 "Normal" 2 "Init_ON" 1 "Init_OFF" 0 "Pre_Init";
VAL_ 123 DBC_sec_brake_pedal_applied_QF 2 "Faulty" 1 "Normal" 0 "Not initialized";
VAL_ 1300 SSCU_thermal_driver_led_ERR 1 "Error temperature driver led" 0 "No driver led temperature error" ;
VAL_ 1300 SSCU_right_window_led_ERR 1 "Led BackLight Error" 0 "No Error" ;
VAL_ 1300 SSCU_left_window_led_ERR 1 "Led BackLight Error" 0 "No Error" ;
VAL_ 1300 SSCU_rear_fog_led_ERR 3 "Function and Backlight Error" 2 "Function Led Error" 1 "BackLight Led Error" 0 "No Error" ;
VAL_ 1300 SSCU_max_demist_led_ERR 3 "Function and Backlight Error" 2 "Function Led Error" 1 "BackLight Led Error" 0 "No Error" ;
VAL_ 1300 SSCU_doors_lock_led_ERR 3 "Function and Backlight Error" 2 "Function Led Error" 1 "BackLight Led Error" 0 "No Error" ;
VAL_ 1300 SSCU_rear_trunk_led_ERR 1 "Led BackLight Error" 0 "No Error" ;
VAL_ 1300 SSCU_mcu_ERR 3 "Overvoltage" 2 "Undervoltage" 1 "Overtemperature" 0 "None" ;
VAL_ 1300 SSCU_right_window_key_ERR 1 "Key stuck close Error" 0 "No Error" ;
VAL_ 1300 SSCU_left_window_key_ERR 1 "Key stuck close Error" 0 "No Error" ;
VAL_ 1300 SSCU_rear_fog_key_ERR 1 "Key stuck close Error" 0 "No Error" ;
VAL_ 1300 SSCU_max_demist_key_ERR 1 "Key stuck close Error" 0 "No Error" ;
VAL_ 1300 SSCU_doors_lock_key_ERR 1 "Key stuck close Error" 0 "No Error" ;
VAL_ 1300 SSCU_rear_trunk_key_ERR 1 "Key stuck close Error" 0 "No Error" ;
VAL_ 1300 SSCU_right_window_key_incohe_ERR 1 "Wrong analog voltage Error" 0 "No Error" ;
VAL_ 1300 SSCU_left_window_key_incohe_ERR 1 "Wrong analog voltage Error" 0 "No Error" ;
VAL_ 1300 SSCU_communication_ERR 1 "Communication Error" 0 "No Error" ;
VAL_ 164 VCU_turn_signal_ST 4 "Unavailable" 3 "Hazard lights" 2 "Right" 1 "Left" 0 "On";
VAL_ 164 VCU_tire_pressure_warning 2 "Unavailable" 1 "On" 0 "Off";
VAL_ 164 VCU_brake_system_warning 2 "Unavailable" 1 "On" 0 "Off";
VAL_ 164 VCU_ABS_ST 2 "Fault" 1 "Active" 0 "Not active";
VAL_ 164 VCU_ESC_ST 3 "Fault" 2 "OFF" 1 "On and active" 0 "On but not active";
VAL_ 164 VCU_TC_ST 3 "Fault" 2 "OFF" 1 "On and active" 0 "On but not active";
VAL_ 144 PCU_PRND_mode_ST 3 "D" 2 "N" 1 "R" 0 "P";
VAL_ 144 PCU_PRND_modes_AVBL 15 "PRND" 14 "RND" 13 "PND" 12 "ND" 11 "PRD" 10 "RD" 9 "PD" 8 "D" 7 "PRN" 6 "RN" 5 "PN" 4 "N" 3 "PR" 2 "R" 1 "P" 0 "Nothing";
VAL_ 144 PCU_driving_mode_ST 7 "TEMPORARY" 6 "CUSTOM 2" 5 "CUSTOM 1" 4 "DRIFT" 3 "TRACK" 2 "SPORT" 1 "COMFORT" 0 "RANGE";
VAL_ 144 PCU_stability_mode_ST 7 "IDLE" 5 "DRIFT" 4 "TV+ ON" 3 "TV ON" 2 "TV OFF" 1 "TC OFF" 0 "ALL OFF";
VAL_ 144 PCU_throttle_response_ST 3 "IDLE" 2 "Aggressive" 1 "Direct" 0 "Smooth";
VAL_ 144 PCU_suspension_stiffness_ST 3 "IDLE" 2 "Hard" 1 "Medium" 0 "Soft";
VAL_ 144 PCU_steering_assistance_ST 3 "IDLE" 2 "High" 1 "Medium" 0 "Low";
VAL_ 144 PCU_active_aero_setup_ST 7 "Drift" 6 "Track" 5 "Sport" 4 "Comfort" 3 "Range" 2 "High" 1 "Medium" 0 "Low" ;
VAL_ 144 PCU_regen_off_throttle_ST 2 "Normal" 1 "Low" 0 "Off";
VAL_ 144 PCU_creep_ST 1 "ON" 0 "OFF";
VAL_ 144 PCU_ignition_ST 1 "ENGAGED" 0 "DISENGAGED";
VAL_ 144 PCU_launch_control_ST 1 "Enabled" 0 "Disabled";
VAL_ 144 PCU_tow_mode_ST 1 "ON" 0 "OFF";
VAL_ 660 CCU_R_aero_cooling_REQ 3 "LVL 3" 2 "LVL 2" 1 "LVL 1" 0 "No cooling" ;
VAL_ 660 CCU_F_aero_cooling_REQ 3 "LVL 3" 2 "LVL 2" 1 "LVL 1" 0 "No cooling" ;
VAL_ 158 IVI_PRND_mode_REQ 7 "IDLE" 3 "D" 2 "N" 1 "R" 0 "P";
VAL_ 157 IVI_driving_mode_REQ 15 "IDLE" 7 "TEMPORARY" 6 "CUSTOM_2" 5 "CUSTOM_1" 4 "DRIFT" 3 "TRACK" 2 "SPORT" 1 "COMFORT" 0 "RANGE";
VAL_ 157 IVI_stability_mode_REQ 7 "IDLE" 5 "DRIFT" 4 "TV+ ON" 3 "TV ON" 2 "TV OFF" 1 "TC OFF" 0 "ALL OFF";
VAL_ 156 IVI_donor_mode_REQ 7 "IDLE" 4 "DRIFT" 3 "TRACK" 2 "SPORT" 1 "COMFORT" 0 "RANGE";
VAL_ 156 IVI_throttle_response_REQ 3 "IDLE" 2 "Aggressive" 1 "Direct" 0 "Smooth";
VAL_ 156 IVI_suspension_stiffness_REQ 3 "IDLE" 2 "Hard" 1 "Medium" 0 "Soft";
VAL_ 156 IVI_steering_assistance_REQ 3 "IDLE" 2 "High" 1 "Medium" 0 "Low";
VAL_ 156 IVI_active_aero_setup_REQ 4 "IDLE" 3 "Mode based" 2 "High" 1 "Medium" 0 "Low" ;
VAL_ 156 IVI_regen_off_throttle_REQ 3 "IDLE" 2 "Normal" 1 "Low" 0 "Off";
VAL_ 156 IVI_creep_REQ 2 "IDLE" 1 "ON" 0 "OFF";
VAL_ 156 IVI_save_to_custom_REQ 3 "IDLE" 1 "Save CUSTOM 2" 0 "Save CUSTOM 1";
VAL_ 156 IVI_launch_control_REQ 3 "IDLE" 1 "Enable" 0 "Disable";
VAL_ 156 IVI_temporary_mode_REQ 1 "ON" 0 "IDLE";
VAL_ 156 IVI_ESC_reference_REQ 4 "ESC REF 3 - Loose bounds" 3 "ESC REF 2 - Medium Bounds" 2 "ESC REF 1 - Tight Bounds" 1 "OFF" 0 "IDLE";
VAL_ 156 IVI_TC_setup_REQ 2 "ON" 1 "OFF" 0 "IDLE";
VAL_ 808 SKM_KEYBLADE_unlock_ST 1 "KEYBLADE unlock active" 0 "KEYBLADE unlock disabled" ;
VAL_ 808 SKM_PEPS_active_ST 1 "PEPS Active" 0 "PEPS Disabled" ;
VAL_ 808 SKM_KEYFOB_data_base_ST 4 "4 Active KEYFOBs" 3 "3 Active KEYFOBs" 2 "2 Active KEYFOBs" 1 "1 Active KEYFOB" 0 "EMPTY" ;
VAL_ 808 SKM_KEYFOB_IMMO_ST 2 "Authenticated" 1 "Not authenticated" 0 "IDLE" ;
VAL_ 804 SKM_KEYFOB_RKE_distance_4 1 "LESS THAN 6M" 0 "MORE THAN 6M" ;
VAL_ 804 SKM_KEYFOB_RKE_distance_3 1 "LESS THAN 6M" 0 "MORE THAN 6M" ;
VAL_ 804 SKM_KEYFOB_RKE_distance_2 1 "LESS THAN 6M" 0 "MORE THAN 6M" ;
VAL_ 804 SKM_KEYFOB_RKE_distance_1 1 "LESS THAN 6M" 0 "MORE THAN 6M" ;
VAL_ 804 SKM_KEYFOB_RKE_ST_4 18 "Long press BT6" 17 "Long press BT5" 16 "Long press BT4" 15 "Long press BT3" 14 "Long press BT2" 13 "Long press BT1" 12 "Double press BT6" 11 "Double press BT5" 10 "Double press BT4" 9 "Double press BT3" 8 "Double press BT2" 7 "Double press BT1" 6 "Short press BT6" 5 "Short press BT5" 4 "Short press BT4" 3 "Short press BT3" 2 "Short press BT2" 1 "Short press BT1" 0 "No keys are pressed" ;
VAL_ 804 SKM_KEYFOB_RKE_ST_3 18 "Long press BT6" 17 "Long press BT5" 16 "Long press BT4" 15 "Long press BT3" 14 "Long press BT2" 13 "Long press BT1" 12 "Double press BT6" 11 "Double press BT5" 10 "Double press BT4" 9 "Double press BT3" 8 "Double press BT2" 7 "Double press BT1" 6 "Short press BT6" 5 "Short press BT5" 4 "Short press BT4" 3 "Short press BT3" 2 "Short press BT2" 1 "Short press BT1" 0 "No keys are pressed" ;
VAL_ 804 SKM_KEYFOB_RKE_ST_2 18 "Long press BT6" 17 "Long press BT5" 16 "Long press BT4" 15 "Long press BT3" 14 "Long press BT2" 13 "Long press BT1" 12 "Double press BT6" 11 "Double press BT5" 10 "Double press BT4" 9 "Double press BT3" 8 "Double press BT2" 7 "Double press BT1" 6 "Short press BT6" 5 "Short press BT5" 4 "Short press BT4" 3 "Short press BT3" 2 "Short press BT2" 1 "Short press BT1" 0 "No keys are pressed" ;
VAL_ 804 SKM_KEYFOB_RKE_ST_1 18 "Long press BT6" 17 "Long press BT5" 16 "Long press BT4" 15 "Long press BT3" 14 "Long press BT2" 13 "Long press BT1" 12 "Double press BT6" 11 "Double press BT5" 10 "Double press BT4" 9 "Double press BT3" 8 "Double press BT2" 7 "Double press BT1" 6 "Short press BT6" 5 "Short press BT5" 4 "Short press BT4" 3 "Short press BT3" 2 "Short press BT2" 1 "Short press BT1" 0 "No keys are pressed" ;
VAL_ 804 SKM_KEYFOB_battery_ST_4 1 "LOW" 0 "OK" ;
VAL_ 804 SKM_KEYFOB_battery_ST_3 1 "LOW" 0 "OK" ;
VAL_ 804 SKM_KEYFOB_battery_ST_2 1 "LOW" 0 "OK" ;
VAL_ 804 SKM_KEYFOB_battery_ST_1 1 "LOW" 0 "OK" ;
VAL_ 1048 CCCU_version_info_MUX 3 "Serial number and DBC version" 2 "Hardware version" 1 "Firmware version" 0 "Bootloader version" ;
VAL_ 1299 CCCU_internal_FATAL_ERR 1 "Error" 0 "OK";
VAL_ 1299 CCCU_internal_ERR 1 "Error" 0 "OK";
VAL_ 1299 CCCU_joystick_ERR 1 "Error" 0 "OK";
VAL_ 2297364746 H_PUMP_motor_ST 3 "Motor is stopped due to error" 2 "Motor is manually stopped" 1 "Motor given speed not reached" 0 "Motor is running at given speed" ;
VAL_ 2297364746 H_PUMP_rampup_ST 1 "Program 2 selected" 0 "Program 1 selected" ;
VAL_ 2364475905 BCU_R_rampup_REQ 1 "program 2" 0 "program 1" ;
VAL_ 2364475905 BCU_R_motor_EN 1 "Motor start" 0 "Motor stop" ;
VAL_ 80 ACU_front_crash_ST 0 "No front crash event" 1 "Front crash detected" ;
VAL_ 80 ACU_driver_side_crash_ST 0 "No driver side crash event" 1 "driver side crash detected" ;
VAL_ 80 ACU_psg_side_crash_ST 0 "No passenger side crash event" 1 "passanger side crash detected" ;
VAL_ 80 ACU_rear_crash_ST 0 "No rear crash event" 1 "Rear crash detected" ;
VAL_ 80 ACU_roll_crash_ST 0 "No roll crash event" 1 "Roll crash detected" ;
VAL_ 80 ACU_driver_belt_dply_ST 0 "No driver belt dply" 1 "Driver belt dply occured" ;
VAL_ 80 ACU_psg_belt_dply_ST 0 "No passanger belt dply" 1 "psg belt dply occured" ;
VAL_ 80 ACU_driver_F_AB_1st_stg_dply_ST 0 "No driver FAB 1st stage dply" 1 "DRV FAB 1st stage dply occured" ;
VAL_ 80 ACU_driver_F_AB_2nd_stg_dply_ST 0 "No driver FAB 2nd stage dply" 1 "DRV FAB 2nd stage dply occured" ;
VAL_ 80 ACU_psg_F_AB_1st_stg_dply_ST 0 "No psg FAB 1st stage dply" 1 "psg FAB 1st stage dply occured" ;
VAL_ 80 ACU_psg_F_AB_2nd_stg_dply_ST 0 "No psg FAB 2nd stage dply" 1 " PSG FAB 2stage dply occured" ;
VAL_ 80 ACU_psg_side_AB_dply_ST 0 "No psg side airbag dplymnt" 1 "psg side AB dply occured" ;
VAL_ 80 ACU_driver_side_AB_dply_ST 0 "No driver side airbag dply" 1 "Driver side airbag dply occured" ;
VAL_ 80 ACU_battery_cutoff_dply_ST 0 "No battery cutoff dply" 1 "Batt cutoff dply occured" ;
VAL_ 336 ACU_seat_belt_driver_ST 0 "Not Available" 1 "Failure" 2 "Not buckled" 3 "Buckled" ;
VAL_ 336 ACU_seat_belt_passenger_ST 0 "Not Available" 1 "Failure" 2 "Not buckled" 3 "Buckled" ;
VAL_ 336 ACU_system_deactivated 0 "AB Normal Operation" 1 "AB System_Deactivated" ;
VAL_ 336 ACU_diagnostic_active 0 "AB Normal Operation" 1 "AB Diagnostic Active" ;
VAL_ 336 ACU_driver_side_crash 0 "No Event" 1 "DriverSide Crash Detected" ;
VAL_ 336 ACU_front_crash 0 "No Event" 1 "Front Crash Detected" ;
VAL_ 336 ACU_warning_lamp 0 "AB Warning Lamp OFF" 1 "AB Warning Lamp ON" ;
VAL_ 336 ACU_passenger_AB_warning_lamp 0 "Passenger AB Warning Lamp OFF" 1 "Passenger AB Warning Lamp ON" ;
VAL_ 336 ACU_passenger_AB_status 0 "Passenger Activated" 1 "Passenger Deactivated" ;
VAL_ 336 ACU_passenger_side_crash 0 "No Event" 1 "PassSide Crash Detected" ;
VAL_ 336 ACU_rear_crash 0 "No Event" 1 "Rear Crash Detected" ;
VAL_ 336 ACU_rollover_crash 0 "No Event" 1 "Rollover Crash Detected" ;
VAL_ 336 ACU_system_failure 0 "AB Normal Operation" 1 "AB System Failure" ;
VAL_ 533 DBC1280_ABS_status_QF 0 "Signal invalid" 1 "Signal valid" ;
VAL_ 533 PCU_ESP_status_QF 0 "Signal invalid" 1 "Signal valid" ;
VAL_ 533 PCU_ignition_ST 1 "ENGAGED" 0 "DISENGAGED" ;
VAL_ 533 PCU_ESP_status 0 "ESP not active" 1 "ESP active" 2 "ESP deactivated by user" ;
VAL_ 533 DBC1280_ABS_status 0 "ABS not active" 1 "ABS active" ;
VAL_ 533 PCU_brake_pedal_applied_ST 0 "Not applied" 1 "Applied" ;
VAL_ 533 PCU_brake_pedal_applied_ST_QF 0 "Signal invalid" 1 "Signal valid" ;
VAL_ 533 PCU_accelerator_pedal_posit_QF 0 "Signal invalid" 1 "Signal valid" ;
VAL_ 533 IVI_airbag_lamp_ST 0 "Failure" 1 "OK" ;
VAL_ 642 OFFCAR_SKM_PEPS_EN 0 "Disable PEPS" 1 "Enable PEPS" ;
VAL_ 642 OFFCAR_SKM_IMMO_mode_EN 0 "Disable" 1 "Enable" ;
VAL_ 1292 SWCU_internal_FATAL_ERR 1 "Error" 0 "OK";
VAL_ 1292 SWCU_internal_ERR 1 "Error" 0 "OK";
VAL_ 1292 SWCU_menu_switch_ERR 1 "Error" 0 "OK";
VAL_ 1292 SWCU_lights_sw_ERR 1 "Error" 0 "OK";
VAL_ 1292 SWCU_indicators_ERR 1 "Error" 0 "OK";
VAL_ 1292 SWCU_misc_camera_ERR 1 "Error" 0 "OK";
VAL_ 1292 SWCU_mics_coach_ERR 1 "Error" 0 "OK";
VAL_ 1292 SWCU_misc_voice_ERR 1 "Error" 0 "OK";
VAL_ 1292 SWCU_wipers_ERR 1 "Error" 0 "OK";
VAL_ 1292 SWCU_washer_ERR 1 "Error" 0 "OK";
VAL_ 1289 SCU_PSG_internal_FATAL_ERR 1 "Error" 0 "OK";
VAL_ 1289 SCU_PSG_seat_move_ERR 1 "Error" 0 "OK";
VAL_ 1289 SCU_PSG_ibolt_ERR 1 "Error" 0 "OK";
VAL_ 1289 SCU_PSG_seat_lumbar_upper_ERR 1 "ERROR" 0 "OK" ;
VAL_ 1289 SCU_PSG_seat_lumbar_lower_ERR 1 "ERROR" 0 "OK" ;
VAL_ 1288 SCU_DRV_internal_FATAL_ERR 1 "Error" 0 "OK";
VAL_ 1288 SCU_DRV_internal_ERR 1 "Error" 0 "OK";
VAL_ 1288 SCU_DRV_heater_ERR 1 "Error" 0 "OK";
VAL_ 1288 SCU_DRV_seat_move_ERR 1 "Error" 0 "OK";
VAL_ 1288 SCU_DRV_seat_lumbar_upper_ERR 1 "ERROR" 0 "OK" ;
VAL_ 1288 SCU_DRV_seat_lumbar_lower_ERR 1 "ERROR" 0 "OK" ;
VAL_ 1283 DBCU_internal_FATAL_ERR 1 "Error" 0 "OK";
VAL_ 1283 DBCU_internal_ERR 1 "Error" 0 "OK";
VAL_ 1283 DBCU_camera_heater_ERR 1 "Error" 0 "OK";
VAL_ 1283 DBCU_glovebox_ERR 1 "Error" 0 "OK";
VAL_ 1283 DBCU_horn_sw_ERR 1 "Error" 0 "OK";
VAL_ 1283 DBCU_illumination_ERR 1 "Error" 0 "OK";
VAL_ 1283 DBCU_IVI_disp_pwr_ERR 1 "Error" 0 "OK";
VAL_ 1283 DBCU_IVI_eth_pwr_ERR 1 "Error" 0 "OK";
VAL_ 1283 DBCU_pre_amp_ERR 1 "Error" 0 "OK";
VAL_ 1283 DBCU_SWCU_pwr_ERR 1 "Error" 0 "OK";
VAL_ 1283 DBCU_steering_clmn_depth_ERR 1 "Error" 0 "OK";
VAL_ 1283 DBCU_steering_clmn_height_ERR 1 "Error" 0 "OK";
VAL_ 1283 DBCU_illumination_knob_ERR 1 "Error" 0 "OK";
VAL_ 1283 DBCU_diag_port_pwr_ERR 1 "Error" 0 "OK";
VAL_ 1283 DBCU_IVI_disp_knob_pwr_ERR 1 "Error" 0 "OK";
VAL_ 1283 DBCU_CCCU_pwr_ERR 1 "Error" 0 "OK";
VAL_ 1281 DCU_PSG_internal_FATAL_ERR 1 "Error" 0 "OK";
VAL_ 1281 DCU_PSG_internal_ERR 1 "Error" 0 "OK";
VAL_ 1281 DCU_PSG_door_latch_ERR 1 "Error" 0 "OK";
VAL_ 1281 DCU_PSG_mirror_adj_ERR 1 "Error" 0 "OK";
VAL_ 1281 DCU_PSG_mirror_heater_ERR 1 "Error" 0 "OK";
VAL_ 1281 DCU_PSG_puddle_light_ERR 1 "Error" 0 "OK";
VAL_ 1281 DCU_PSG_window_ERR 1 "Error" 0 "OK";
VAL_ 1281 DCU_PSG_ambinet_light_ERR 1 "Error" 0 "OK";
VAL_ 1281 DCU_PSG_indicator_ERR 1 "Error" 0 "OK";
VAL_ 1281 DCU_PSG_crash_detection_ERR 1 "Error" 0 "OK";
VAL_ 1281 DCU_PSG_can_rx_ERR 1 "Error" 0 "OK";
VAL_ 1280 DCU_DRV_internal_FATAL_ERR 1 "Error" 0 "OK";
VAL_ 1280 DCU_DRV_internal_ERR 1 "Error" 0 "OK";
VAL_ 1280 DCU_DRV_door_latch_ERR 1 "Error" 0 "OK";
VAL_ 1280 DCU_DRV_mirror_adj_ERR 1 "Error" 0 "OK";
VAL_ 1280 DCU_DRV_mirror_heater_ERR 1 "Error" 0 "OK";
VAL_ 1280 DCU_DRV_puddle_light_ERR 1 "Error" 0 "OK";
VAL_ 1280 DCU_DRV_window_ERR 1 "Error" 0 "OK";
VAL_ 1280 DCU_DRV_ambinet_light_ERR 1 "Error" 0 "OK";
VAL_ 1280 DCU_DRV_indicator_ERR 1 "Error" 0 "OK";
VAL_ 1280 DCU_DRV_crash_detection_ERR 1 "Error" 0 "OK";
VAL_ 1280 DCU_DRV_can_rx_ERR 1 "Error" 0 "OK";
VAL_ 1305 SKM_internal_FATAL_ERR 1 "Error" 0 "OK";
VAL_ 1305 SKM_internal_ERR 1 "Error" 0 "OK";
VAL_ 1305 SKM_immobilizer_ERR 1 "Error" 0 "OK";
VAL_ 1305 SKM_keyfob_ERR 1 "Error" 0 "OK";
VAL_ 1305 SKM_PEPS_ERR 1 "Error" 0 "OK";
VAL_ 2032 OFFCAR_mule_gear_REQ 1 "1st gear" 0 "Default" ;
VAL_ 127 VCU_lock_ST 1 "Unlocked" 0 "Locked" ;
VAL_ 127 VCU_vehicle_ST 7 "Sleep Charging" 6 "StandBy Charging" 5 "Accessory Charging" 4 "Powertrain" 3 "Accesory" 2 "StandBy" 1 "Sleepy" 0 "Sleep" ;
VAL_ 127 VCU_auth_ST 1 "TRUE" 0 "FALSE" ;
VAL_ 127 VCU_silent_alarm_mode_ST 1 "Active" 0 "Not active" ;
VAL_ 127 VCU_hibernation_mode_ST 1 "Active" 0 "Not active" ;
VAL_ 127 VCU_low_pwr_consump_mode_ST 1 "Active" 0 "Not active" ;
VAL_ 127 VCU_limp_mode_ST 1 "Active" 0 "Not active" ;
VAL_ 127 VCU_adas_drv_coach_mode_ST 1 "Active" 0 "Not active" ;
VAL_ 127 VCU_valet_mode_ST 1 "Active" 0 "Not active" ;
VAL_ 127 VCU_towing_mode_ST 1 "Active" 0 "Not active" ;
VAL_ 127 VCU_launch_control_mode_ST 1 "Active" 0 "Not active" ;
VAL_ 127 VCU_low_12V_battery_mode_ST 1 "Active" 0 "Not active" ;
VAL_ 127 VCU_ota_update_mode_ST 1 "Active" 0 "Not active" ;
VAL_ 127 VCU_user_stealth_mode_ST 1 "Stealth" 0 "User" ;
VAL_ 640 VCU_PEPS_EN 0 "Disable PEPS" 1 "Enable PEPS" ;
VAL_ 640 VCU_IMMO_mode_EN 0 "Disable" 1 "Enable" ;
VAL_ 1041 SKM_version_info_MUX 3 "SKM serial number" 2 "Hardware version" 1 "Application firmware version" 0 "Bootloader firmware version" ;
VAL_ 802 SKM_KEYFOB_learn_ERR 1 "Key Learning Checksum ERROR" 0 "Key Learning Checksum Default" ;
VAL_ 802 SKM_LF_antenna_2_ERR 2 "Open" 1 "Short circuit" 0 "Ok" ;
VAL_ 802 SKM_LF_antenna_3_ERR 2 "Open" 1 "Short circuit" 0 "Ok" ;
VAL_ 802 SKM_LF_antenna_5_ERR 2 "Open" 1 "Short circuit" 0 "Ok" ;
VAL_ 802 SKM_LF_antenna_4_ERR 2 "Open" 1 "Short circuit" 0 "Ok" ;
VAL_ 802 SKM_LF_antenna_7_ERR 2 "Open" 1 "Short circuit" 0 "Ok" ;
VAL_ 802 SKM_LF_antenna_6_ERR 2 "Open" 1 "Short circuit" 0 "Ok" ;
VAL_ 802 SKM_LF_antenna_8_ERR 2 "Open" 1 "Short circuit" 0 "Ok" ;
VAL_ 802 SKM_LF_antenna_1_ERR 2 "Open" 1 "Short circuit" 0 "Ok" ;
VAL_ 801 SKM_PEPS_active_ST 1 "PEPS Active" 0 "PEPS Disabled" ;
VAL_ 801 SKM_KEYFOB_battery_ST_4 1 "LOW" 0 "OK" ;
VAL_ 801 SKM_KEYFOB_battery_ST_3 1 "LOW" 0 "OK" ;
VAL_ 801 SKM_KEYFOB_battery_ST_2 1 "LOW" 0 "OK" ;
VAL_ 801 SKM_KEYFOB_RKE_ST_4 18 "Long press BT6" 17 "Long press BT5" 16 "Long press BT4" 15 "Long press BT3" 14 "Long press BT2" 13 "Long press BT1" 12 "Double press BT6" 11 "Double press BT5" 10 "Double press BT4" 9 "Double press BT3" 8 "Double press BT2" 7 "Double press BT1" 6 "Short press BT6" 5 "Short press BT5" 4 "Short press BT4" 3 "Short press BT3" 2 "Short press BT2" 1 "Short press BT1" 0 "No keys are pressed" ;
VAL_ 801 SKM_KEYFOB_RKE_ST_3 18 "Long press BT6" 17 "Long press BT5" 16 "Long press BT4" 15 "Long press BT3" 14 "Long press BT2" 13 "Long press BT1" 12 "Double press BT6" 11 "Double press BT5" 10 "Double press BT4" 9 "Double press BT3" 8 "Double press BT2" 7 "Double press BT1" 6 "Short press BT6" 5 "Short press BT5" 4 "Short press BT4" 3 "Short press BT3" 2 "Short press BT2" 1 "Short press BT1" 0 "No keys are pressed" ;
VAL_ 801 SKM_KEYFOB_RKE_ST_2 18 "Long press BT6" 17 "Long press BT5" 16 "Long press BT4" 15 "Long press BT3" 14 "Long press BT2" 13 "Long press BT1" 12 "Double press BT6" 11 "Double press BT5" 10 "Double press BT4" 9 "Double press BT3" 8 "Double press BT2" 7 "Double press BT1" 6 "Short press BT6" 5 "Short press BT5" 4 "Short press BT4" 3 "Short press BT3" 2 "Short press BT2" 1 "Short press BT1" 0 "No keys are pressed" ;
VAL_ 801 SKM_KEYFOB_RKE_ST_1 18 "Long press BT6" 17 "Long press BT5" 16 "Long press BT4" 15 "Long press BT3" 14 "Long press BT2" 13 "Long press BT1" 12 "Double press BT6" 11 "Double press BT5" 10 "Double press BT4" 9 "Double press BT3" 8 "Double press BT2" 7 "Double press BT1" 6 "Short press BT6" 5 "Short press BT5" 4 "Short press BT4" 3 "Short press BT3" 2 "Short press BT2" 1 "Short press BT1" 0 "No keys are pressed" ;
VAL_ 801 SKM_KEYFOB_PEPS_ST_4 6 "KEYFOB detected INSIDE" 5 "KEYFOB detected on FRONT side" 4 "KEYFOB detected on BACKside" 3 "KEYFOB detected on RIGHT side" 2 "KEYFOB detected on LEFT side" 1 "EARLY KEYFOB detection" 0 "KEYFOB is not detected" ;
VAL_ 801 SKM_KEYFOB_PEPS_ST_3 6 "KEYFOB detected INSIDE" 5 "KEYFOB detected on FRONT side" 4 "KEYFOB detected on BACKside" 3 "KEYFOB detected on RIGHT side" 2 "KEYFOB detected on LEFT side" 1 "EARLY KEYFOB detection" 0 "KEYFOB is not detected" ;
VAL_ 801 SKM_KEYFOB_PEPS_ST_2 6 "KEYFOB detected INSIDE" 5 "KEYFOB detected on FRONT side" 4 "KEYFOB detected on BACKside" 3 "KEYFOB detected on RIGHT side" 2 "KEYFOB detected on LEFT side" 1 "EARLY KEYFOB detection" 0 "KEYFOB is not detected" ;
VAL_ 801 SKM_KEYFOB_PEPS_ST_1 6 "KEYFOB detected INSIDE" 5 "KEYFOB detected on FRONT side" 4 "KEYFOB detected on BACKside" 3 "KEYFOB detected on RIGHT side" 2 "KEYFOB detected on LEFT side" 1 "EARLY KEYFOB detection" 0 "KEYFOB is not detected" ;
VAL_ 801 SKM_KEYFOB_data_base_ST 4 "4 Active KEYFOBs" 3 "3 Active KEYFOBs" 2 "2 Active KEYFOBs" 1 "1 Active KEYFOB" 0 "EMPTY" ;
VAL_ 801 SKM_KEYFOB_battery_ST_1 1 "LOW" 0 "OK" ;
VAL_ 801 SKM_KEYFOB_IMMO_ST 2 "Authenticated" 1 "Not authenticated" 0 "IDLE" ;
VAL_ 1282 BCU_F_internal_FATAL_ERR 1 "Error" 0 "OK";
VAL_ 1282 BCU_F_internal_ERR 1 "Error" 0 "OK";
VAL_ 1282 BCU_F_brake_wear_ERR 1 "Error" 0 "OK";
VAL_ 1282 BCU_F_dampers_ERR 1 "Error" 0 "OK";
VAL_ 1282 BCU_F_horn_1_ERR 1 "Error" 0 "OK";
VAL_ 1282 BCU_F_sidemarks_ERR 1 "Error" 0 "OK";
VAL_ 1282 BCU_F_washer_ERR 1 "Error" 0 "OK";
VAL_ 1282 BCU_F_wipers_ERR 1 "Error" 0 "OK";
VAL_ 1282 BCU_F_horn_2_ERR 1 "Error" 0 "OK";
VAL_ 1293 BCU_R_internal_FATAL_ERR 1 "Error" 0 "OK";
VAL_ 1293 BCU_R_internal_ERR 1 "Error" 0 "OK";
VAL_ 1293 BCU_R_hydraulic_pump_ERR 1 "Error" 0 "OK";
VAL_ 1293 BCU_R_hydraulic_accumulator_ERR 1 "Error" 0 "OK";
VAL_ 1293 BCU_R_suspension_ERR 1 "Error" 0 "OK";
VAL_ 1293 BCU_R_wing_angle_ERR 1 "Error" 0 "OK";
VAL_ 1293 BCU_R_wing_height_ERR 1 "Error" 0 "OK";
VAL_ 1293 BCU_R_reverse_light_ERR 1 "Error" 0 "OK";
VAL_ 1293 BCU_R_fog_light_ERR 1 "Error" 0 "OK";
VAL_ 1293 BCU_R_brakes_wear_ERR 1 "Error" 0 "OK";
VAL_ 1293 BCU_R_tailgate_latch_ERR 1 "Error" 0 "OK";
VAL_ 1293 BCU_R_sidemarks_ERR 1 "Error" 0 "OK";
VAL_ 1293 BCU_R_licenselight_ERR 1 "Error" 0 "OK";
VAL_ 1293 BCU_R_brake_light_ERR 1 "Error" 0 "OK";
VAL_ 1293 BCU_R_trunk_light_ERR 1 "Error" 0 "OK";
VAL_ 1293 BCU_R_ultrasonic_board_ERR  1 "Error" 0 "OK";
VAL_ 768 IVI_stop_resume_charging_REQ 2 "Resume" 1 "Stop" 0 "IDLE" ;
VAL_ 768 IVI_TPMS_low_pressure_reset_REQ 1 "TPMS reset pressure" 0 "No request" ;
VAL_ 768 IVI_valet_mode_REQ 1 "Request" 0 "IDLE" ;
VAL_ 768 IVI_AC_recirculation_REQ 2 "Auto mode" 1 "Recirculation mode" 0 "Fresh air mode" ;
VAL_ 768 IVI_AC_flow_dir_REQ 7 "Wind and Foot and Driver" 6 "Wind and Foot" 5 "Wind and Driver" 4 "Driver and Foot" 3 "Footwell" 2 "Driver" 1 "Windshield" 0 "Auto" ;
VAL_ 768 IVI_AC_ON_CTRL 1 "AC ON" 0 "AC OFF" ;
VAL_ 768 IVI_AC_fan_speed_REQ 8 "Auto" 7 "7" 6 "6" 5 "5" 4 "4" 3 "3" 2 "2" 1 "1" 0 "OFF" ;
VAL_ 768 IVI_AC_max_demist_REQ 1 "Request" 0 "IDLE";
VAL_ 768 IVI_AC_max_cooling_REQ 1 "Request" 0 "IDLE";
VAL_ 768 IVI_AC_max_heating_REQ 1 "Request" 0 "IDLE";
VAL_ 768 IVI_AC_auto_mode_REQ 1 "ON" 0 "OFF";
VAL_ 768 IVI_precooling_REQ 1 "Request" 0 "IDLE";
VAL_ 768 IVI_preheating_REQ 1 "Request" 0 "IDLE";
VAL_ 1045 VCU_version_info_MUX 3 "VCU serial number" 2 "Hardware version" 1 "Application firmware version" 0 "Bootloader firmware version" ;
VAL_ 1032 BCU_F_version_info_MUX 3 "BCU F serial number" 2 "Hardware version" 1 "Application firmware version" 0 "Bootloader firmware version" ;
VAL_ 1033 BCU_R_version_info_MUX 3 "BCU R serial number" 2 "Hardware version" 1 "Application firmware version" 0 "Bootloader firmware version" ;
VAL_ 1047 IVI_version_info_MUX 3 "IVI serial number" 2 "Hardware version" 1 "Application firmware version" 0 "Bootloader firmware version" ;
VAL_ 1042 SWCU_version_info_MUX 3 "SWCU serial number" 2 "Hardware version" 1 "Application firmware version" 0 "Bootloader firmware version" ;
VAL_ 1036 DBCU_version_info_MUX 3 "DBCU serial number" 2 "Hardware version" 1 "Application firmware version" 0 "Bootloader firmware version" ;
VAL_ 1025 SCU_PSG_version_info_MUX 3 "SCU PSG serial number" 2 "Hardware version" 1 "Application firmware version" 0 "Bootloader firmware version" ;
VAL_ 1023 SCU_DRV_version_info_MUX 3 "SCU DRV serial number" 2 "Hardware version" 1 "Application firmware version" 0 "Bootloader firmware version" ;
VAL_ 1038 DCU_PSG_version_info_MUX 3 "DCU PSG serial number" 2 "Hardware version" 1 "Application firmware version" 0 "Bootloader firmware version" ;
VAL_ 1037 DCU_DRV_version_info_MUX 3 "DCU DRV serial number" 2 "Hardware version" 1 "Application firmware version" 0 "Bootloader firmware version" ;
VAL_ 776 IVI_seat_heat_CTRL 3 "HIGH" 2 "MEDIUM" 1 "LOW" 0 "OFF" ;
VAL_ 776 IVI_seat_Z_CTRL 2 "BACKWARD" 1 "FORWARD" 0 "IDLE" ;
VAL_ 776 IVI_seat_Y_CTRL 2 "DOWN" 1 "UP" 0 "IDLE" ;
VAL_ 776 IVI_seat_X_CTRL 2 "BACKWARD" 1 "FORWARD" 0 "IDLE" ;
VAL_ 776 IVI_seat_lumbar_CTRL 4 "Deflate upper inflate lower" 3 "Inflate upper deflate lower" 2 "Deflate both" 1 "Inflate both" 0 "IDLE" ;
VAL_ 777 IVI_seat_heat_CTRL 3 "HIGH" 2 "MEDIUM" 1 "LOW" 0 "OFF" ;
VAL_ 777 IVI_seat_Z_CTRL 2 "BACKWARD" 1 "FORWARD" 0 "IDLE" ;
VAL_ 777 IVI_seat_Y_CTRL 2 "DOWN" 1 "UP" 0 "IDLE" ;
VAL_ 777 IVI_seat_X_CTRL 2 "BACKWARD" 1 "FORWARD" 0 "IDLE" ;
VAL_ 777 IVI_seat_lumbar_CTRL 4 "Deflate upper inflate lower" 3 "Inflate upper deflate lower" 2 "Deflate both" 1 "Inflate both" 0 "IDLE" ;
VAL_ 140 VCU_parking_brake_applied 2 "Applied" 1 "Not applied" 0 "IDLE" ;
VAL_ 140 VCU_activate_brakes 2 "Activate" 1 "Deactivate" 0 "IDLE" ;
VAL_ 1353 BCU_R_brake_wear_ST 1 "Not OK" 0 "OK" ;
VAL_ 1353 BCU_R_fog_light_ST 1 "ON" 0 "OFF" ;
VAL_ 1353 BCU_R_tailgate_ST 2 "UNLOCKED" 1 "LATCHED" 0 "LOCKED" ;
VAL_ 1353 BCU_R_suspension_lvl_ST 1 "Up" 0 "Down" ;
VAL_ 1353 BCU_R_aero_mode_ST 7 "Drift" 6 "Track" 5 "Sport" 4 "Comfort" 3 "Range" 2 "High" 1 "Medium" 0 "Low" ;
VAL_ 1353 BCU_R_charger_lid_lock_ST 3 "OPENING" 2 "OPEN" 1 "LOCKING" 0 "LOCKED" ;
VAL_ 848 SWCU_cruise_control_REQ 1 "ON" 0 "OFF" ;
VAL_ 848 SWCU_lift_function_REQ 1 "Request" 0 "IDLE" ;
VAL_ 848 SWCU_voice_cmd_REQ 1 "Request" 0 "IDLE" ;
VAL_ 848 SWCU_volume_inc_REQ 1 "Request" 0 "IDLE" ;
VAL_ 848 SWCU_phone_REQ 1 "Request" 0 "IDLE" ;
VAL_ 848 SWCU_volume_dec_REQ 1 "Request" 0 "IDLE" ;
VAL_ 848 SWCU_wipe_once_REQ 1 "ON" 0 "OFF" ;
VAL_ 848 SWCU_cruise_speed_inc_REQ 1 "Request" 0 "IDLE" ;
VAL_ 848 SWCU_cruise_speed_dec_REQ 1 "Request" 0 "IDLE" ;
VAL_ 848 SWCU_washer_pump_REQ 1 "ON" 0 "OFF" ;
VAL_ 848 SWCU_indicator_REQ 4 "3FlashRHS" 3 "3FlashLHS" 2 "RHS" 1 "LHS" 0 "OFF" ;
VAL_ 848 SWCU_highbeams_REQ 1 "ON" 0 "OFF" ;
VAL_ 848 SWCU_highbeams_flash_REQ 1 "ON" 0 "OFF" ;
VAL_ 848 SWCU_siri_google_REQ 1 "ON" 0 "OFF" ;
VAL_ 772 BCU_F_parking_lights_ST 1 "ON " 0 "OFF" ;
VAL_ 772 BCU_F_wipers_speed_ST 3 "Fast" 2 "Medium" 1 "Slow" 0 "OFF" ;
VAL_ 772 BCU_F_wipers_automode_ST 1 "ON" 0 "OFF" ;
VAL_ 772 BCU_F_washer_liquid_warn 1 "LOW" 0 "OK" ;
VAL_ 772 BCU_F_brake_fluid_warn 1 "LOW" 0 "OK" ;
VAL_ 772 BCU_F_bonnet_open_ST 1 "OPEN" 0 "CLOSE" ;
VAL_ 772 BCU_F_bonnet_latch_lock_ST 1 "UNLOCKED" 0 "LOCKED" ;
VAL_ 772 BCU_F_brake_wear_ST 1 "Not OK" 0 "OK" ;
VAL_ 772 BCU_F_follow_home_lights_ST 3 "60 seconds" 2 "30 seconds" 1 "10 seconds" 0 "0 seconds" ;
VAL_ 772 BCU_F_horn_ST 1 "ON" 0 "OFF" ;
VAL_ 772 BCU_F_aero_mode_ST 7 "Drift" 6 "Track" 5 "Sport" 4 "Comfort" 3 "Range" 2 "High" 1 "Medium" 0 "Low" ;
VAL_ 770 IVI_DCU_puddle_light_REQ  3 "60 seconds" 2 "30 seconds" 1 "10 seconds" 0 "0 seconds" ;
VAL_ 770 IVI_parking_lights_REQ 1 "ON " 0 "OFF" ;
VAL_ 770 IVI_wipers_automode_EN 1 "Enable" 0 "Disable" ;
VAL_ 770 IVI_mirror_drop_EN 1 "ENABLE" 0 "DISABLE" ;
VAL_ 770 IVI_lock_unlock_REQ 2 "UNLOCK" 1 "LOCK" 0 "IDLE" ;
VAL_ 770 IVI_keyless_REQ 2 "Keyless ON" 1 "Keyless OFF" 0 "IDLE" ;
VAL_ 770 IVI_follow_home_lights_REQ 3 "60 seconds" 2 "30 seconds" 1 "10 seconds" 0 "0 seconds" ;
VAL_ 770 IVI_rear_trunk_REQ 1 "Request" 0 "IDLE" ;
VAL_ 770 IVI_flash_lights_lock_EN 1 "Enable" 0 "Disable" ;
VAL_ 770 IVI_bonnet_latch_unlock_REQ 1 "UNLOCK" 0 "IDLE" ;
VAL_ 770 IVI_lights_REQ 2 "Low" 1 "Position" 0 "OFF" ;
VAL_ 770 IVI_charger_lid_lock_REQ 2 "UNLOCK" 1 "LOCK" 0 "IDLE" ;
VAL_ 770 IVI_VCU_wake_REQ 1 "ON" 0 "OFF" ;
VAL_ 771 IVI_ota_update_REQ 1 "TRUE" 0 "FALSE";
VAL_ 781 CCCU_DIR_A_REQ 1 "Request" 0 "IDLE" ;
VAL_ 781 CCCU_DIR_C_REQ 1 "Request" 0 "IDLE" ;
VAL_ 781 CCCU_DIR_B_REQ 1 "Request" 0 "IDLE" ;
VAL_ 781 CCCU_DIR_D_REQ 1 "Request" 0 "IDLE" ;
VAL_ 781 CCCU_PUSH_REQ 1 "Request" 0 "IDLE" ;
VAL_ 781 CCCU_rotaryEncoder_REQ 2 "Rotation left" 1 "Rotation right" 0 "IDLE" ;
VAL_ 782 DBCU_horn_REQ 1 "ON" 0 "OFF" ;
VAL_ 261 VCU_doors_lock_src_REQ 5 "Facial recognition" 4 "Central console" 3 "Mobile Application" 2 "Key Fob" 1 "PEPS" 0 "IDLE" ;
VAL_ 261 VCU_doors_lock_REQ 2 "UNLOCK" 1 "LOCK" 0 "IDLE" ;
VAL_ 261 VCU_rear_trunk_REQ 2 "CLOSE" 1 "OPEN" 0 "IDLE" ;
VAL_ 261 VCU_wipers_speed_REQ 3 "Fast" 2 "Medium" 1 "Slow" 0 "OFF" ;
VAL_ 261 VCU_washer_REQ 2 "ON" 1 "OFF" 0 "IDLE" ;
VAL_ 261 VCU_hazard_light_REQ 1 "ON" 0 "OFF" ;
VAL_ 261 VCU_window_DRV_REQ 5 "Request auto-down-crash" 4 "Request auto-down" 3 "Request down" 2 "Request auto-up" 1 "Request up" 0 "IDLE" ;
VAL_ 261 VCU_window_PSG_REQ 5 "Request auto-down-crash" 4 "Request auto-down" 3 "Request down" 2 "Request auto-up" 1 "Request up" 0 "IDLE" ;
VAL_ 265 OFFCAR_VCU_SWCU_cal_REQ 1 "CALIBRATE" 0 "IDLE" ;
VAL_ 265 OFFCAR_VCU_window_cal_DRV_REQ 1 "CALIBRATE" 0 "IDLE" ;
VAL_ 265 OFFCAR_VCU_window_cal_PSG_REQ 1 "CALIBRATE" 0 "IDLE" ;
VAL_ 265 OFFCAR_VCU_seat_cal_DRV_REQ 1 "CALIBRATE" 0 "IDLE" ;
VAL_ 265 OFFCAR_VCU_seat_cal_PSG_REQ 1 "CALIBRATE" 0 "IDLE" ;
VAL_ 265 OFFCAR_VCU_rear_aero_cal_REQ 1 "CALIBRATE" 0 "IDLE" ;
VAL_ 530 DCU_puddle_light_ST 3 "60 seconds" 2 "30 seconds" 1 "10 seconds" 0 "0 seconds" ;
VAL_ 530 DCU_folding_mirror_ST 1 "FOLDED" 0 "UNFOLDED" ;
VAL_ 530 DCU_lock_unlock_ST 1 "Unlocked" 0 "Locked" ;
VAL_ 530 DCU_mirror_drop_ST 1 "ENABLED" 0 "DISABLED" ;
VAL_ 530 DCU_window_ST 1 "OPEN" 0 "CLOSED" ;
VAL_ 530 DCU_door_open_close_ST 1 "OPEN" 0 "CLOSE" ;
VAL_ 263 IVI_DCU_mirror_control_REQ 4 "TILT RIGHT" 3 "TILT LEFT" 2 "TILT DOWN" 1 "TILT UP" 0 "IDLE" ;
VAL_ 264 IVI_DCU_mirror_control_REQ 4 "TILT RIGHT" 3 "TILT LEFT" 2 "TILT DOWN" 1 "TILT UP" 0 "IDLE" ;
VAL_ 263 IVI_folding_mirror_REQ 2 "UNFOLD" 1 "FOLD" 0 "IDLE" ;
VAL_ 264 IVI_folding_mirror_REQ 2 "UNFOLD" 1 "FOLD" 0 "IDLE" ;
VAL_ 266 IVI_glovebox_lock_REQ 2 "UNLOCK" 1 "LOCK" 0 "IDLE" ;
VAL_ 266 IVI_swcol_X_depth_REQ 2 "Backward" 1 "Forward" 0 "IDLE" ;
VAL_ 266 IVI_swcol_Y_height_REQ 2 "Down" 1 "Up" 0 "IDLE" ;
VAL_ 529 DCU_folding_mirror_ST 1 "FOLDED" 0 "UNFOLDED" ;
VAL_ 529 DCU_puddle_light_ST 3 "60 seconds" 2 "30 seconds" 1 "10 seconds" 0 "0 seconds" ;
VAL_ 529 DCU_lock_unlock_ST 1 "Unlocked" 0 "Locked" ;
VAL_ 529 DCU_mirror_drop_ST 1 "ENABLED" 0 "DISABLED" ;
VAL_ 529 DCU_window_ST 1 "OPEN" 0 "CLOSED" ;
VAL_ 529 DCU_door_open_close_ST 1 "OPEN" 0 "CLOSE" ;
VAL_ 513 SCU_PSG_airbag_activate_REQ 0 "NOT Engaged" 1 "Init or Engaged" ;
VAL_ 513 SCU_PSG_seat_occupied 1 "TRUE" 0 "FALSE" ;
VAL_ 513 SCU_seat_ST 7 "Fault move" 6 "Fault" 5 "Adjust" 4 "Retract" 3 "Not calibrated" 2 "Move" 1 "Calibrate" 0 "Sleep" ;
VAL_ 513 SCU_seat_heat_level_ST 2 "HIGH" 1 "LOW" 0 "OFF" ;
VAL_ 513 SCU_PSG_ibolt_ERR 0 "OK" 1 "Error" ;
VAL_ 513 SCU_PSG_seat_F_position_ST 0 "Not in full frond position" 1 "Full front position" ;
VAL_ 513 SCU_seat_lumbar_ST  4 "Deflate upper inflate lower" 3 "Inflate upper deflate lower" 2 "Deflate both" 1 "Inflate both" 0 "IDLE" ;
VAL_ 512 SCU_seat_ST 7 "Fault move" 6 "Fault" 5 "Adjust" 4 "Retract" 3 "Not calibrated" 2 "Move" 1 "Calibrate" 0 "Sleep" ;
VAL_ 512 SCU_seat_heat_level_ST 2 "HIGH" 1 "LOW" 0 "OFF" ;
VAL_ 512 SCU_seat_F_position_ST 0 "Not in full frond position" 1 "Full front position" ;
VAL_ 512 SCU_seat_lumbar_ST  4 "Deflate upper inflate lower" 3 "Inflate upper deflate lower" 2 "Deflate both" 1 "Inflate both" 0 "IDLE" ;
VAL_ 111 ADAS_washer_pump_REQ 1 "ON" 0 "OFF" ;
VAL_ 111 ADAS_wiper_speed_REQ 3 "Fast" 2 "Medium" 1 "Slow" 0 "OFF" ;
VAL_ 256 PCU_avg_motor_RPM_QF 0 "Signal invalid" 1 "Signal valid" ;
VAL_ 256 EPS_steering_wheel_angle_QF 0 "Signal invalid" 1 "Signal valid" ;
VAL_ 256 PCU_vehicle_speed_QF 0 "Signal invalid" 1 "Signal valid" ;
VAL_ 255 PCU_vehicle_charging_ST 3 "Error" 2 "Complete" 1 "Inactive" 0 "Active" ;
VAL_ 1823 IMU1_vert_acc_QF 14 "NOT AVAILABLE" 15 "UNFILLED" 6 "INVALID" 4 "SUBSTITUTE" 2 "VALID" ;
VAL_ 1823 IMU1_pitch_rate_QF 14 "NOT AVAILABLE" 15 "UNFILLED" 6 "INVALID" 4 "SUBSTITUTE" 2 "VALID" ;
VAL_ 1823 IMU1_pitch_rate 65535 "UNFILLED" 65534 "INVALID" 65533 "NOT AVAILABLE" ;
VAL_ 1823 IMU1_vert_acc 65535 "UNFILLED" 65534 "INVALID" 65533 "NOT AVAILABLE" ;
VAL_ 1822 IMU1_long_acc 65535 "UNFILLED" 65534 "INVALID" 65533 "NOT AVAILABLE" ;
VAL_ 1822 IMU1_long_acc_QF 14 "NOT AVAILABLE" 15 "UNFILLED" 6 "INVALID" 4 "SUBSTITUTE" 2 "VALID" ;
VAL_ 1822 IMU1_roll_rate_QF 14 "NOT AVAILABLE" 15 "UNFILLED" 6 "INVALID" 4 "SUBSTITUTE" 2 "VALID" ;
VAL_ 1822 IMU1_roll_rate 65535 "UNFILLED" 65534 "INVALID" 65533 "NOT AVAILABLE" ;
VAL_ 1821 IMU1_yaw_rate_QF 14 "NOT AVAILABLE" 15 "UNFILLED" 6 "INVALID" 4 "SUBSTITUTE" 2 "VALID" ;
VAL_ 1821 IMU1_sc_status 15 "UNFILLED" 14 "FUNC ERROR" 13 "FUNC NOT AVAILABLE" 5 "SYNC FAIL" 4 "SYNC UNDERFLOW" 3 "OVERVOLTAGE" 2 "UNDERVOLTAGE" 0 "NO MISTAKE" ;
VAL_ 1821 IMU1_lat_acc_QF 14 "NOT AVAILABLE" 15 "UNFILLED" 6 "INVALID" 4 "SUBSTITUTE" 2 "VALID" ;
VAL_ 1821 IMU1_lat_acc 65535 "UNFILLED" 65534 "INVALID" 65533 "NOT AVAILABLE" ;
VAL_ 1821 IMU1_yaw_rate 65535 "UNFILLED" 65534 "INVALID" 65533 "NOT AVAILABLE" ;
VAL_ 409 VCU_internal_FATAL_ERR 1 "Error" 0 "OK";
VAL_ 409 VCU_internal_ERR 1 "Error" 0 "OK";
VAL_ 409 VCU_hazard_input_ERR 1 "Error" 0 "OK";
VAL_ 409 VCU_power_on_mdl_ERR 1 "Error" 0 "OK";
VAL_ 409 VCU_wakeup_ERR 1 "Error" 0 "OK";
VAL_ 409 VCU_central_disp_ERR 1 "Error" 0 "OK";
VAL_ 409 VCU_ADSA_E_ERR 1 "Error" 0 "OK";
VAL_ 409 VCU_PCU_ERR 1 "Error" 0 "OK";
VAL_ 409 VCU_PDM_F_ERR 1 "Error" 0 "OK";
VAL_ 409 VCU_PDM_R_ERR 1 "Error" 0 "OK";
VAL_ 447 BCU_F_RH_mirror_DI_EN 1 "ON" 0 "OFF" ;
VAL_ 447 BCU_F_LH_mirror_DI_EN 1 "ON" 0 "OFF" ;
VAL_ 1301 FCL_L_Rx_ERR 3 "Init" 1 "Fault" 0 "NoFault" ;
VAL_ 1301 FCL_L_internal_ERR 3 "Init" 1 "Fault" 0 "NoFault" ;
VAL_ 1301 FCL_L_LH_DI_ERR 3 "Init" 1 "Fault" 0 "NoFault" ;
VAL_ 1301 FCL_L_LH_OB_ERR 3 "Init" 1 "Fault" 0 "NoFault" ;
VAL_ 1301 FCL_L_LH_IB_ERR 3 "Init" 1 "Fault" 0 "NoFault" ;
VAL_ 1302 FCL_R_Rx_ERR 3 "Init" 1 "Fault" 0 "NoFault" ;
VAL_ 1302 FCL_R_internal_ERR 3 "Init" 1 "Fault" 0 "NoFault" ;
VAL_ 1302 FCL_R_RH_DI_ERR 3 "Init" 1 "Fault" 0 "NoFault" ;
VAL_ 1302 FCL_R_RH_OB_ERR 3 "Init" 1 "Fault" 0 "NoFault" ;
VAL_ 1302 FCL_R_RH_IB_ERR 3 "Init" 1 "Fault" 0 "NoFault" ;
VAL_ 1303 RCL_L_LED_DRIVE_4_ERR 3 "Init" 1 "Fault" 0 "NoFault" ;
VAL_ 1303 RCL_L_LED_DRIVE_3_ERR 3 "Init" 1 "Fault" 0 "NoFault" ;
VAL_ 1303 RCL_L_Rx_ERR 3 "Init" 1 "Fault" 0 "NoFault" ;
VAL_ 1303 RCL_L_internal_ERR 3 "Init" 1 "Fault" 0 "NoFault" ;
VAL_ 1303 RCL_L_LED_DRIVE_1_2_ERR 3 "Init" 1 "Fault" 0 "NoFault" ;
VAL_ 1304 RCL_R_LED_DRIVE_4_ERR 3 "Init" 1 "Fault" 0 "NoFault" ;
VAL_ 1304 RCL_R_LED_DRIVE_3_ERR 3 "Init" 1 "Fault" 0 "NoFault" ;
VAL_ 1304 RCL_R_LED_DRIVE_1_2_ERR 3 "Init" 1 "Fault" 0 "NoFault" ;
VAL_ 1304 RCL_R_Rx_ERR 3 "Init" 1 "Fault" 0 "NoFault" ;
VAL_ 1304 RCL_R_internal_ERR 3 "Init" 1 "Fault" 0 "NoFault" ;
VAL_ 128 VCU_lock_ST 1 "Unlocked" 0 "Locked" ;

VAL_ 299 PDM_F_airbag_WARN 1 "Warning" 0 "OK";
VAL_ 299 PDM_F_adas_WARN 1 "Warning" 0 "OK";
VAL_ 299 PDM_F_dcdc_WARN 1 "Warning" 0 "OK";
VAL_ 299 PDM_F_battery_WARN 1 "Warning" 0 "OK";
VAL_ 299 PDM_F_soh_WARN 1 "Warning" 0 "OK";

VAL_ 300 PDM_F_airbag_redn_WARN 1 "Warning" 0 "OK";
VAL_ 300 PDM_F_adas_redn_WARN 1 "Warning" 0 "OK";
VAL_ 300 PDM_F_dcdc_redn_WARN 1 "Warning" 0 "OK";
VAL_ 300 PDM_F_battery_redn_WARN 1 "Warning" 0 "OK";
VAL_ 300 PDM_F_soh_redn_WARN 1 "Warning" 0 "OK";

VAL_ 306 PDM_R_adas_WARN 1 "Warning" 0 "OK";
VAL_ 306 PDM_R_dcdc_WARN 1 "Warning" 0 "OK";
VAL_ 306 PDM_R_battery_WARN 1 "Warning" 0 "OK";
VAL_ 306 PDM_R_soh_WARN 1 "Warning" 0 "OK";

VAL_ 307 PDM_R_adas_redn_WARN 1 "Warning" 0 "OK";
VAL_ 307 PDM_R_dcdc_redn_WARN 1 "Warning" 0 "OK";
VAL_ 307 PDM_R_battery_redn_WARN 1 "Warning" 0 "OK";
VAL_ 307 PDM_R_soh_redn_WARN 1 "Warning" 0 "OK";
